VERSION "created by canmatrix"

NS_ :

BS_:

BU_: RadarFrontCenter DASy

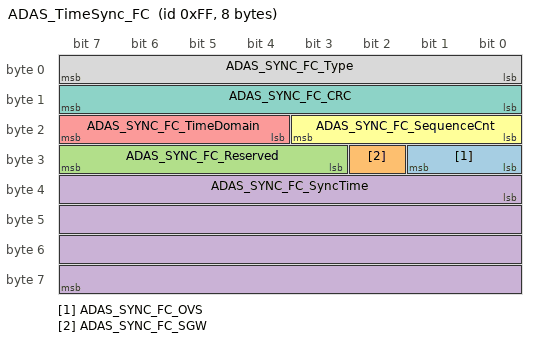
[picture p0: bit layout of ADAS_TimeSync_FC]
BO_ 255 ADAS_TimeSync_FC: 8 DASy
 SG_ ADAS_SYNC_FC_OVS : 24|2@1+ (1,0) [0|3] ""  RadarFrontCenter
 SG_ ADAS_SYNC_FC_SGW : 26|1@1+ (1,0) [0|1] ""  RadarFrontCenter
 SG_ ADAS_SYNC_FC_Reserved : 27|5@1+ (1,0) [0|31] ""  RadarFrontCenter
 SG_ ADAS_SYNC_FC_SyncTime : 32|32@1+ (1,0) [0|4294967295] ""  RadarFrontCenter
 SG_ ADAS_SYNC_FC_TimeDomain : 20|4@1+ (1,0) [0|15] ""  RadarFrontCenter
 SG_ ADAS_SYNC_FC_SequenceCnt : 16|4@1+ (1,0) [0|15] ""  RadarFrontCenter
 SG_ ADAS_SYNC_FC_CRC : 8|8@1+ (1,0) [0|0] ""  RadarFrontCenter
 SG_ ADAS_SYNC_FC_Type : 0|8@1+ (1,0) [0|255] ""  RadarFrontCenter

BO_ 384 RFC_LocationHdr00: 64 RadarFrontCenter
 SG_ RFC_Hdr00_CRC : 0|16@1+ (1,0) [0|65535] ""  DASy
 SG_ RFC_Hdr00_AliveCtr : 16|8@1+ (1,0) [0|255] ""  DASy
 SG_ RFC_Hdr00_ProtBlockCtr : 24|8@1+ (1,0) [0|255] ""  DASy
 SG_ RFC_Hdr00_ProtLocationCount : 48|8@1+ (1,0) [0|255] ""  DASy
 SG_ RFC_Hdr00_SensorState : 56|4@1+ (1,0) [0|15] ""  DASy
 SG_ RFC_Hdr00_TimeStamp : 60|26@1+ (1,0) [0|67108863] "ms"  DASy
 SG_ RFC_Hdr00_TimeStampStatus : 488|8@1+ (1,0) [0|255] ""  DASy

BO_ 400 RFC_Location_000_001: 64 RadarFrontCenter
 SG_ RFC_Loc000_CRC : 0|16@1+ (1,0) [0|65535] ""  DASy
 SG_ RFC_Loc000_AliveCtr : 16|8@1+ (1,0) [0|255] ""  DASy
 SG_ RFC_Loc000_ProtBlockCtr : 24|8@1+ (1,0) [0|255] ""  DASy
 SG_ RFC_Loc000_Dr : 32|16@1+ (0.0078125,0) [0|511.9921875] "m"  DASy
 SG_ RFC_Loc000_Vr : 48|16@1+ (0.00390625,-128) [-128|127.99609375] "m/s"  DASy
 SG_ RFC_Loc000_Theta : 64|16@1+ (0.01,-327.68) [-90|90] "deg"  DASy
 SG_ RFC_Loc000_Phi : 80|16@1+ (0.01,-327.68) [-30|30] "deg"  DASy
 SG_ RFC_Loc000_DrVnce : 96|16@1+ (1.52588E-005,0) [0|0.999984741210937] "m^2"  DASy
 SG_ RFC_Loc000_VrVnce : 112|16@1+ (1.52588E-005,0) [0|0.999984741210937] "m^2/s^2"  DASy
 SG_ RFC_Loc000_ThetaVnce : 128|16@1+ (0.00390625,0) [0|255.99609375] "deg^2"  DASy
 SG_ RFC_Loc000_PhiVnce : 144|16@1+ (0.00390625,0) [0|255.99609375] "deg^2"  DASy
 SG_ RFC_Loc000_RCS : 176|16@1+ (0.00390625,-128) [-128|127.99609375] "dBsm"  DASy
 SG_ RFC_Loc000_RSSI : 192|16@1+ (0.00195312,0) [0|127.998046875] "dimensionless"  DASy
 SG_ RFC_Loc001_Dr : 256|16@1+ (0.0078125,0) [0|511.9921875] "m"  DASy
 SG_ RFC_Loc001_Vr : 272|16@1+ (0.00390625,-128) [-128|127.99609375] "m/s"  DASy
 SG_ RFC_Loc001_Theta : 288|16@1+ (0.01,-327.68) [-90|90] "deg"  DASy
 SG_ RFC_Loc001_Phi : 304|16@1+ (0.01,-327.68) [-30|30] "deg"  DASy
 SG_ RFC_Loc001_DrVnce : 320|16@1+ (1.52588E-005,0) [0|0.999984741210937] "m^2"  DASy
 SG_ RFC_Loc001_VrVnce : 336|16@1+ (1.52588E-005,0) [0|0.999984741210937] "m^2/s^2"  DASy
 SG_ RFC_Loc001_ThetaVnce : 352|16@1+ (0.00390625,0) [0|255.99609375] "deg^2"  DASy
 SG_ RFC_Loc001_PhiVnce : 368|16@1+ (0.00390625,0) [0|255.99609375] "deg^2"  DASy
 SG_ RFC_Loc001_RCS : 400|16@1+ (0.00390625,-128) [-128|127.99609375] "dBsm"  DASy
 SG_ RFC_Loc001_RSSI : 416|16@1+ (0.00195312,0) [0|127.998046875] "dimensionless"  DASy

BO_ 401 RFC_Location_002_003: 64 RadarFrontCenter
 SG_ RFC_Loc002_CRC : 0|16@1+ (1,0) [0|65535] ""  DASy
 SG_ RFC_Loc002_AliveCtr : 16|8@1+ (1,0) [0|255] ""  DASy
 SG_ RFC_Loc002_ProtBlockCtr : 24|8@1+ (1,0) [0|255] ""  DASy
 SG_ RFC_Loc002_Dr : 32|16@1+ (0.0078125,0) [0|511.9921875] "m"  DASy
 SG_ RFC_Loc002_Vr : 48|16@1+ (0.00390625,-128) [-128|127.99609375] "m/s"  DASy
 SG_ RFC_Loc002_Theta : 64|16@1+ (0.01,-327.68) [-90|90] "deg"  DASy
 SG_ RFC_Loc002_Phi : 80|16@1+ (0.01,-327.68) [-30|30] "deg"  DASy
 SG_ RFC_Loc002_DrVnce : 96|16@1+ (1.52588E-005,0) [0|0.999984741210937] "m^2"  DASy
 SG_ RFC_Loc002_VrVnce : 112|16@1+ (1.52588E-005,0) [0|0.999984741210937] "m^2/s^2"  DASy
 SG_ RFC_Loc002_ThetaVnce : 128|16@1+ (0.00390625,0) [0|255.99609375] "deg^2"  DASy
 SG_ RFC_Loc002_PhiVnce : 144|16@1+ (0.00390625,0) [0|255.99609375] "deg^2"  DASy
 SG_ RFC_Loc002_RCS : 176|16@1+ (0.00390625,-128) [-128|127.99609375] "dBsm"  DASy
 SG_ RFC_Loc002_RSSI : 192|16@1+ (0.00195312,0) [0|127.998046875] "dimensionless"  DASy
 SG_ RFC_Loc003_Dr : 256|16@1+ (0.0078125,0) [0|511.9921875] "m"  DASy
 SG_ RFC_Loc003_Vr : 272|16@1+ (0.00390625,-128) [-128|127.99609375] "m/s"  DASy
 SG_ RFC_Loc003_Theta : 288|16@1+ (0.01,-327.68) [-90|90] "deg"  DASy
 SG_ RFC_Loc003_Phi : 304|16@1+ (0.01,-327.68) [-30|30] "deg"  DASy
 SG_ RFC_Loc003_DrVnce : 320|16@1+ (1.52588E-005,0) [0|0.999984741210937] "m^2"  DASy
 SG_ RFC_Loc003_VrVnce : 336|16@1+ (1.52588E-005,0) [0|0.999984741210937] "m^2/s^2"  DASy
 SG_ RFC_Loc003_ThetaVnce : 352|16@1+ (0.00390625,0) [0|255.99609375] "deg^2"  DASy
 SG_ RFC_Loc003_PhiVnce : 368|16@1+ (0.00390625,0) [0|255.99609375] "deg^2"  DASy
 SG_ RFC_Loc003_RCS : 400|16@1+ (0.00390625,-128) [-128|127.99609375] "dBsm"  DASy
 SG_ RFC_Loc003_RSSI : 416|16@1+ (0.00195312,0) [0|127.998046875] "dimensionless"  DASy

BO_ 402 RFC_Location_004_005: 64 RadarFrontCenter
 SG_ RFC_Loc004_CRC : 0|16@1+ (1,0) [0|65535] ""  DASy
 SG_ RFC_Loc004_AliveCtr : 16|8@1+ (1,0) [0|255] ""  DASy
 SG_ RFC_Loc004_ProtBlockCtr : 24|8@1+ (1,0) [0|255] ""  DASy
 SG_ RFC_Loc004_Dr : 32|16@1+ (0.0078125,0) [0|511.9921875] "m"  DASy
 SG_ RFC_Loc004_Vr : 48|16@1+ (0.00390625,-128) [-128|127.99609375] "m/s"  DASy
 SG_ RFC_Loc004_Theta : 64|16@1+ (0.01,-327.68) [-90|90] "deg"  DASy
 SG_ RFC_Loc004_Phi : 80|16@1+ (0.01,-327.68) [-30|30] "deg"  DASy
 SG_ RFC_Loc004_DrVnce : 96|16@1+ (1.52588E-005,0) [0|0.999984741210937] "m^2"  DASy
 SG_ RFC_Loc004_VrVnce : 112|16@1+ (1.52588E-005,0) [0|0.999984741210937] "m^2/s^2"  DASy
 SG_ RFC_Loc004_ThetaVnce : 128|16@1+ (0.00390625,0) [0|255.99609375] "deg^2"  DASy
 SG_ RFC_Loc004_PhiVnce : 144|16@1+ (0.00390625,0) [0|255.99609375] "deg^2"  DASy
 SG_ RFC_Loc004_RCS : 176|16@1+ (0.00390625,-128) [-128|127.99609375] "dBsm"  DASy
 SG_ RFC_Loc004_RSSI : 192|16@1+ (0.00195312,0) [0|127.998046875] "dimensionless"  DASy
 SG_ RFC_Loc005_Dr : 256|16@1+ (0.0078125,0) [0|511.9921875] "m"  DASy
 SG_ RFC_Loc005_Vr : 272|16@1+ (0.00390625,-128) [-128|127.99609375] "m/s"  DASy
 SG_ RFC_Loc005_Theta : 288|16@1+ (0.01,-327.68) [-90|90] "deg"  DASy
 SG_ RFC_Loc005_Phi : 304|16@1+ (0.01,-327.68) [-30|30] "deg"  DASy
 SG_ RFC_Loc005_DrVnce : 320|16@1+ (1.52588E-005,0) [0|0.999984741210937] "m^2"  DASy
 SG_ RFC_Loc005_VrVnce : 336|16@1+ (1.52588E-005,0) [0|0.999984741210937] "m^2/s^2"  DASy
 SG_ RFC_Loc005_ThetaVnce : 352|16@1+ (0.00390625,0) [0|255.99609375] "deg^2"  DASy
 SG_ RFC_Loc005_PhiVnce : 368|16@1+ (0.00390625,0) [0|255.99609375] "deg^2"  DASy
 SG_ RFC_Loc005_RCS : 400|16@1+ (0.00390625,-128) [-128|127.99609375] "dBsm"  DASy
 SG_ RFC_Loc005_RSSI : 416|16@1+ (0.00195312,0) [0|127.998046875] "dimensionless"  DASy

BO_ 403 RFC_Location_006_007: 64 RadarFrontCenter
 SG_ RFC_Loc006_CRC : 0|16@1+ (1,0) [0|65535] ""  DASy
 SG_ RFC_Loc006_AliveCtr : 16|8@1+ (1,0) [0|255] ""  DASy
 SG_ RFC_Loc006_ProtBlockCtr : 24|8@1+ (1,0) [0|255] ""  DASy
 SG_ RFC_Loc006_Dr : 32|16@1+ (0.0078125,0) [0|511.9921875] "m"  DASy
 SG_ RFC_Loc006_Vr : 48|16@1+ (0.00390625,-128) [-128|127.99609375] "m/s"  DASy
 SG_ RFC_Loc006_Theta : 64|16@1+ (0.01,-327.68) [-90|90] "deg"  DASy
 SG_ RFC_Loc006_Phi : 80|16@1+ (0.01,-327.68) [-30|30] "deg"  DASy
 SG_ RFC_Loc006_DrVnce : 96|16@1+ (1.52588E-005,0) [0|0.999984741210937] "m^2"  DASy
 SG_ RFC_Loc006_VrVnce : 112|16@1+ (1.52588E-005,0) [0|0.999984741210937] "m^2/s^2"  DASy
 SG_ RFC_Loc006_ThetaVnce : 128|16@1+ (0.00390625,0) [0|255.99609375] "deg^2"  DASy
 SG_ RFC_Loc006_PhiVnce : 144|16@1+ (0.00390625,0) [0|255.99609375] "deg^2"  DASy
 SG_ RFC_Loc006_RCS : 176|16@1+ (0.00390625,-128) [-128|127.99609375] "dBsm"  DASy
 SG_ RFC_Loc006_RSSI : 192|16@1+ (0.00195312,0) [0|127.998046875] "dimensionless"  DASy
 SG_ RFC_Loc007_Dr : 256|16@1+ (0.0078125,0) [0|511.9921875] "m"  DASy
 SG_ RFC_Loc007_Vr : 272|16@1+ (0.00390625,-128) [-128|127.99609375] "m/s"  DASy
 SG_ RFC_Loc007_Theta : 288|16@1+ (0.01,-327.68) [-90|90] "deg"  DASy
 SG_ RFC_Loc007_Phi : 304|16@1+ (0.01,-327.68) [-30|30] "deg"  DASy
 SG_ RFC_Loc007_DrVnce : 320|16@1+ (1.52588E-005,0) [0|0.999984741210937] "m^2"  DASy
 SG_ RFC_Loc007_VrVnce : 336|16@1+ (1.52588E-005,0) [0|0.999984741210937] "m^2/s^2"  DASy
 SG_ RFC_Loc007_ThetaVnce : 352|16@1+ (0.00390625,0) [0|255.99609375] "deg^2"  DASy
 SG_ RFC_Loc007_PhiVnce : 368|16@1+ (0.00390625,0) [0|255.99609375] "deg^2"  DASy
 SG_ RFC_Loc007_RCS : 400|16@1+ (0.00390625,-128) [-128|127.99609375] "dBsm"  DASy
 SG_ RFC_Loc007_RSSI : 416|16@1+ (0.00195312,0) [0|127.998046875] "dimensionless"  DASy

BO_ 404 RFC_Location_008_009: 64 RadarFrontCenter
 SG_ RFC_Loc008_CRC : 0|16@1+ (1,0) [0|65535] ""  DASy
 SG_ RFC_Loc008_AliveCtr : 16|8@1+ (1,0) [0|255] ""  DASy
 SG_ RFC_Loc008_ProtBlockCtr : 24|8@1+ (1,0) [0|255] ""  DASy
 SG_ RFC_Loc008_Dr : 32|16@1+ (0.0078125,0) [0|511.9921875] "m"  DASy
 SG_ RFC_Loc008_Vr : 48|16@1+ (0.00390625,-128) [-128|127.99609375] "m/s"  DASy
 SG_ RFC_Loc008_Theta : 64|16@1+ (0.01,-327.68) [-90|90] "deg"  DASy
 SG_ RFC_Loc008_Phi : 80|16@1+ (0.01,-327.68) [-30|30] "deg"  DASy
 SG_ RFC_Loc008_DrVnce : 96|16@1+ (1.52588E-005,0) [0|0.999984741210937] "m^2"  DASy
 SG_ RFC_Loc008_VrVnce : 112|16@1+ (1.52588E-005,0) [0|0.999984741210937] "m^2/s^2"  DASy
 SG_ RFC_Loc008_ThetaVnce : 128|16@1+ (0.00390625,0) [0|255.99609375] "deg^2"  DASy
 SG_ RFC_Loc008_PhiVnce : 144|16@1+ (0.00390625,0) [0|255.99609375] "deg^2"  DASy
 SG_ RFC_Loc008_RCS : 176|16@1+ (0.00390625,-128) [-128|127.99609375] "dBsm"  DASy
 SG_ RFC_Loc008_RSSI : 192|16@1+ (0.00195312,0) [0|127.998046875] "dimensionless"  DASy
 SG_ RFC_Loc009_Dr : 256|16@1+ (0.0078125,0) [0|511.9921875] "m"  DASy
 SG_ RFC_Loc009_Vr : 272|16@1+ (0.00390625,-128) [-128|127.99609375] "m/s"  DASy
 SG_ RFC_Loc009_Theta : 288|16@1+ (0.01,-327.68) [-90|90] "deg"  DASy
 SG_ RFC_Loc009_Phi : 304|16@1+ (0.01,-327.68) [-30|30] "deg"  DASy
 SG_ RFC_Loc009_DrVnce : 320|16@1+ (1.52588E-005,0) [0|0.999984741210937] "m^2"  DASy
 SG_ RFC_Loc009_VrVnce : 336|16@1+ (1.52588E-005,0) [0|0.999984741210937] "m^2/s^2"  DASy
 SG_ RFC_Loc009_ThetaVnce : 352|16@1+ (0.00390625,0) [0|255.99609375] "deg^2"  DASy
 SG_ RFC_Loc009_PhiVnce : 368|16@1+ (0.00390625,0) [0|255.99609375] "deg^2"  DASy
 SG_ RFC_Loc009_RCS : 400|16@1+ (0.00390625,-128) [-128|127.99609375] "dBsm"  DASy
 SG_ RFC_Loc009_RSSI : 416|16@1+ (0.00195312,0) [0|127.998046875] "dimensionless"  DASy

BO_ 405 RFC_Location_010_011: 64 RadarFrontCenter
 SG_ RFC_Loc010_CRC : 0|16@1+ (1,0) [0|65535] ""  DASy
 SG_ RFC_Loc010_AliveCtr : 16|8@1+ (1,0) [0|255] ""  DASy
 SG_ RFC_Loc010_ProtBlockCtr : 24|8@1+ (1,0) [0|255] ""  DASy
 SG_ RFC_Loc010_Dr : 32|16@1+ (0.0078125,0) [0|511.9921875] "m"  DASy
 SG_ RFC_Loc010_Vr : 48|16@1+ (0.00390625,-128) [-128|127.99609375] "m/s"  DASy
 SG_ RFC_Loc010_Theta : 64|16@1+ (0.01,-327.68) [-90|90] "deg"  DASy
 SG_ RFC_Loc010_Phi : 80|16@1+ (0.01,-327.68) [-30|30] "deg"  DASy
 SG_ RFC_Loc010_DrVnce : 96|16@1+ (1.52588E-005,0) [0|0.999984741210937] "m^2"  DASy
 SG_ RFC_Loc010_VrVnce : 112|16@1+ (1.52588E-005,0) [0|0.999984741210937] "m^2/s^2"  DASy
 SG_ RFC_Loc010_ThetaVnce : 128|16@1+ (0.00390625,0) [0|255.99609375] "deg^2"  DASy
 SG_ RFC_Loc010_PhiVnce : 144|16@1+ (0.00390625,0) [0|255.99609375] "deg^2"  DASy
 SG_ RFC_Loc010_RCS : 176|16@1+ (0.00390625,-128) [-128|127.99609375] "dBsm"  DASy
 SG_ RFC_Loc010_RSSI : 192|16@1+ (0.00195312,0) [0|127.998046875] "dimensionless"  DASy
 SG_ RFC_Loc011_Dr : 256|16@1+ (0.0078125,0) [0|511.9921875] "m"  DASy
 SG_ RFC_Loc011_Vr : 272|16@1+ (0.00390625,-128) [-128|127.99609375] "m/s"  DASy
 SG_ RFC_Loc011_Theta : 288|16@1+ (0.01,-327.68) [-90|90] "deg"  DASy
 SG_ RFC_Loc011_Phi : 304|16@1+ (0.01,-327.68) [-30|30] "deg"  DASy
 SG_ RFC_Loc011_DrVnce : 320|16@1+ (1.52588E-005,0) [0|0.999984741210937] "m^2"  DASy
 SG_ RFC_Loc011_VrVnce : 336|16@1+ (1.52588E-005,0) [0|0.999984741210937] "m^2/s^2"  DASy
 SG_ RFC_Loc011_ThetaVnce : 352|16@1+ (0.00390625,0) [0|255.99609375] "deg^2"  DASy
 SG_ RFC_Loc011_PhiVnce : 368|16@1+ (0.00390625,0) [0|255.99609375] "deg^2"  DASy
 SG_ RFC_Loc011_RCS : 400|16@1+ (0.00390625,-128) [-128|127.99609375] "dBsm"  DASy
 SG_ RFC_Loc011_RSSI : 416|16@1+ (0.00195312,0) [0|127.998046875] "dimensionless"  DASy

BO_ 406 RFC_Location_012_013: 64 RadarFrontCenter
 SG_ RFC_Loc012_CRC : 0|16@1+ (1,0) [0|65535] ""  DASy
 SG_ RFC_Loc012_AliveCtr : 16|8@1+ (1,0) [0|255] ""  DASy
 SG_ RFC_Loc012_ProtBlockCtr : 24|8@1+ (1,0) [0|255] ""  DASy
 SG_ RFC_Loc012_Dr : 32|16@1+ (0.0078125,0) [0|511.9921875] "m"  DASy
 SG_ RFC_Loc012_Vr : 48|16@1+ (0.00390625,-128) [-128|127.99609375] "m/s"  DASy
 SG_ RFC_Loc012_Theta : 64|16@1+ (0.01,-327.68) [-90|90] "deg"  DASy
 SG_ RFC_Loc012_Phi : 80|16@1+ (0.01,-327.68) [-30|30] "deg"  DASy
 SG_ RFC_Loc012_DrVnce : 96|16@1+ (1.52588E-005,0) [0|0.999984741210937] "m^2"  DASy
 SG_ RFC_Loc012_VrVnce : 112|16@1+ (1.52588E-005,0) [0|0.999984741210937] "m^2/s^2"  DASy
 SG_ RFC_Loc012_ThetaVnce : 128|16@1+ (0.00390625,0) [0|255.99609375] "deg^2"  DASy
 SG_ RFC_Loc012_PhiVnce : 144|16@1+ (0.00390625,0) [0|255.99609375] "deg^2"  DASy
 SG_ RFC_Loc012_RCS : 176|16@1+ (0.00390625,-128) [-128|127.99609375] "dBsm"  DASy
 SG_ RFC_Loc012_RSSI : 192|16@1+ (0.00195312,0) [0|127.998046875] "dimensionless"  DASy
 SG_ RFC_Loc013_Dr : 256|16@1+ (0.0078125,0) [0|511.9921875] "m"  DASy
 SG_ RFC_Loc013_Vr : 272|16@1+ (0.00390625,-128) [-128|127.99609375] "m/s"  DASy
 SG_ RFC_Loc013_Theta : 288|16@1+ (0.01,-327.68) [-90|90] "deg"  DASy
 SG_ RFC_Loc013_Phi : 304|16@1+ (0.01,-327.68) [-30|30] "deg"  DASy
 SG_ RFC_Loc013_DrVnce : 320|16@1+ (1.52588E-005,0) [0|0.999984741210937] "m^2"  DASy
 SG_ RFC_Loc013_VrVnce : 336|16@1+ (1.52588E-005,0) [0|0.999984741210937] "m^2/s^2"  DASy
 SG_ RFC_Loc013_ThetaVnce : 352|16@1+ (0.00390625,0) [0|255.99609375] "deg^2"  DASy
 SG_ RFC_Loc013_PhiVnce : 368|16@1+ (0.00390625,0) [0|255.99609375] "deg^2"  DASy
 SG_ RFC_Loc013_RCS : 400|16@1+ (0.00390625,-128) [-128|127.99609375] "dBsm"  DASy
 SG_ RFC_Loc013_RSSI : 416|16@1+ (0.00195312,0) [0|127.998046875] "dimensionless"  DASy

BO_ 407 RFC_Location_014_015: 64 RadarFrontCenter
 SG_ RFC_Loc014_CRC : 0|16@1+ (1,0) [0|65535] ""  DASy
 SG_ RFC_Loc014_AliveCtr : 16|8@1+ (1,0) [0|255] ""  DASy
 SG_ RFC_Loc014_ProtBlockCtr : 24|8@1+ (1,0) [0|255] ""  DASy
 SG_ RFC_Loc014_Dr : 32|16@1+ (0.0078125,0) [0|511.9921875] "m"  DASy
 SG_ RFC_Loc014_Vr : 48|16@1+ (0.00390625,-128) [-128|127.99609375] "m/s"  DASy
 SG_ RFC_Loc014_Theta : 64|16@1+ (0.01,-327.68) [-90|90] "deg"  DASy
 SG_ RFC_Loc014_Phi : 80|16@1+ (0.01,-327.68) [-30|30] "deg"  DASy
 SG_ RFC_Loc014_DrVnce : 96|16@1+ (1.52588E-005,0) [0|0.999984741210937] "m^2"  DASy
 SG_ RFC_Loc014_VrVnce : 112|16@1+ (1.52588E-005,0) [0|0.999984741210937] "m^2/s^2"  DASy
 SG_ RFC_Loc014_ThetaVnce : 128|16@1+ (0.00390625,0) [0|255.99609375] "deg^2"  DASy
 SG_ RFC_Loc014_PhiVnce : 144|16@1+ (0.00390625,0) [0|255.99609375] "deg^2"  DASy
 SG_ RFC_Loc014_RCS : 176|16@1+ (0.00390625,-128) [-128|127.99609375] "dBsm"  DASy
 SG_ RFC_Loc014_RSSI : 192|16@1+ (0.00195312,0) [0|127.998046875] "dimensionless"  DASy
 SG_ RFC_Loc015_Dr : 256|16@1+ (0.0078125,0) [0|511.9921875] "m"  DASy
 SG_ RFC_Loc015_Vr : 272|16@1+ (0.00390625,-128) [-128|127.99609375] "m/s"  DASy
 SG_ RFC_Loc015_Theta : 288|16@1+ (0.01,-327.68) [-90|90] "deg"  DASy
 SG_ RFC_Loc015_Phi : 304|16@1+ (0.01,-327.68) [-30|30] "deg"  DASy
 SG_ RFC_Loc015_DrVnce : 320|16@1+ (1.52588E-005,0) [0|0.999984741210937] "m^2"  DASy
 SG_ RFC_Loc015_VrVnce : 336|16@1+ (1.52588E-005,0) [0|0.999984741210937] "m^2/s^2"  DASy
 SG_ RFC_Loc015_ThetaVnce : 352|16@1+ (0.00390625,0) [0|255.99609375] "deg^2"  DASy
 SG_ RFC_Loc015_PhiVnce : 368|16@1+ (0.00390625,0) [0|255.99609375] "deg^2"  DASy
 SG_ RFC_Loc015_RCS : 400|16@1+ (0.00390625,-128) [-128|127.99609375] "dBsm"  DASy
 SG_ RFC_Loc015_RSSI : 416|16@1+ (0.00195312,0) [0|127.998046875] "dimensionless"  DASy

BO_ 408 RFC_Location_016_017: 64 RadarFrontCenter
 SG_ RFC_Loc016_CRC : 0|16@1+ (1,0) [0|65535] ""  DASy
 SG_ RFC_Loc016_AliveCtr : 16|8@1+ (1,0) [0|255] ""  DASy
 SG_ RFC_Loc016_ProtBlockCtr : 24|8@1+ (1,0) [0|255] ""  DASy
 SG_ RFC_Loc016_Dr : 32|16@1+ (0.0078125,0) [0|511.9921875] "m"  DASy
 SG_ RFC_Loc016_Vr : 48|16@1+ (0.00390625,-128) [-128|127.99609375] "m/s"  DASy
 SG_ RFC_Loc016_Theta : 64|16@1+ (0.01,-327.68) [-90|90] "deg"  DASy
 SG_ RFC_Loc016_Phi : 80|16@1+ (0.01,-327.68) [-30|30] "deg"  DASy
 SG_ RFC_Loc016_DrVnce : 96|16@1+ (1.52588E-005,0) [0|0.999984741210937] "m^2"  DASy
 SG_ RFC_Loc016_VrVnce : 112|16@1+ (1.52588E-005,0) [0|0.999984741210937] "m^2/s^2"  DASy
 SG_ RFC_Loc016_ThetaVnce : 128|16@1+ (0.00390625,0) [0|255.99609375] "deg^2"  DASy
 SG_ RFC_Loc016_PhiVnce : 144|16@1+ (0.00390625,0) [0|255.99609375] "deg^2"  DASy
 SG_ RFC_Loc016_RCS : 176|16@1+ (0.00390625,-128) [-128|127.99609375] "dBsm"  DASy
 SG_ RFC_Loc016_RSSI : 192|16@1+ (0.00195312,0) [0|127.998046875] "dimensionless"  DASy
 SG_ RFC_Loc017_Dr : 256|16@1+ (0.0078125,0) [0|511.9921875] "m"  DASy
 SG_ RFC_Loc017_Vr : 272|16@1+ (0.00390625,-128) [-128|127.99609375] "m/s"  DASy
 SG_ RFC_Loc017_Theta : 288|16@1+ (0.01,-327.68) [-90|90] "deg"  DASy
 SG_ RFC_Loc017_Phi : 304|16@1+ (0.01,-327.68) [-30|30] "deg"  DASy
 SG_ RFC_Loc017_DrVnce : 320|16@1+ (1.52588E-005,0) [0|0.999984741210937] "m^2"  DASy
 SG_ RFC_Loc017_VrVnce : 336|16@1+ (1.52588E-005,0) [0|0.999984741210937] "m^2/s^2"  DASy
 SG_ RFC_Loc017_ThetaVnce : 352|16@1+ (0.00390625,0) [0|255.99609375] "deg^2"  DASy
 SG_ RFC_Loc017_PhiVnce : 368|16@1+ (0.00390625,0) [0|255.99609375] "deg^2"  DASy
 SG_ RFC_Loc017_RCS : 400|16@1+ (0.00390625,-128) [-128|127.99609375] "dBsm"  DASy
 SG_ RFC_Loc017_RSSI : 416|16@1+ (0.00195312,0) [0|127.998046875] "dimensionless"  DASy

BO_ 409 RFC_Location_018_019: 64 RadarFrontCenter
 SG_ RFC_Loc018_CRC : 0|16@1+ (1,0) [0|65535] ""  DASy
 SG_ RFC_Loc018_AliveCtr : 16|8@1+ (1,0) [0|255] ""  DASy
 SG_ RFC_Loc018_ProtBlockCtr : 24|8@1+ (1,0) [0|255] ""  DASy
 SG_ RFC_Loc018_Dr : 32|16@1+ (0.0078125,0) [0|511.9921875] "m"  DASy
 SG_ RFC_Loc018_Vr : 48|16@1+ (0.00390625,-128) [-128|127.99609375] "m/s"  DASy
 SG_ RFC_Loc018_Theta : 64|16@1+ (0.01,-327.68) [-90|90] "deg"  DASy
 SG_ RFC_Loc018_Phi : 80|16@1+ (0.01,-327.68) [-30|30] "deg"  DASy
 SG_ RFC_Loc018_DrVnce : 96|16@1+ (1.52588E-005,0) [0|0.999984741210937] "m^2"  DASy
 SG_ RFC_Loc018_VrVnce : 112|16@1+ (1.52588E-005,0) [0|0.999984741210937] "m^2/s^2"  DASy
 SG_ RFC_Loc018_ThetaVnce : 128|16@1+ (0.00390625,0) [0|255.99609375] "deg^2"  DASy
 SG_ RFC_Loc018_PhiVnce : 144|16@1+ (0.00390625,0) [0|255.99609375] "deg^2"  DASy
 SG_ RFC_Loc018_RCS : 176|16@1+ (0.00390625,-128) [-128|127.99609375] "dBsm"  DASy
 SG_ RFC_Loc018_RSSI : 192|16@1+ (0.00195312,0) [0|127.998046875] "dimensionless"  DASy
 SG_ RFC_Loc019_Dr : 256|16@1+ (0.0078125,0) [0|511.9921875] "m"  DASy
 SG_ RFC_Loc019_Vr : 272|16@1+ (0.00390625,-128) [-128|127.99609375] "m/s"  DASy
 SG_ RFC_Loc019_Theta : 288|16@1+ (0.01,-327.68) [-90|90] "deg"  DASy
 SG_ RFC_Loc019_Phi : 304|16@1+ (0.01,-327.68) [-30|30] "deg"  DASy
 SG_ RFC_Loc019_DrVnce : 320|16@1+ (1.52588E-005,0) [0|0.999984741210937] "m^2"  DASy
 SG_ RFC_Loc019_VrVnce : 336|16@1+ (1.52588E-005,0) [0|0.999984741210937] "m^2/s^2"  DASy
 SG_ RFC_Loc019_ThetaVnce : 352|16@1+ (0.00390625,0) [0|255.99609375] "deg^2"  DASy
 SG_ RFC_Loc019_PhiVnce : 368|16@1+ (0.00390625,0) [0|255.99609375] "deg^2"  DASy
 SG_ RFC_Loc019_RCS : 400|16@1+ (0.00390625,-128) [-128|127.99609375] "dBsm"  DASy
 SG_ RFC_Loc019_RSSI : 416|16@1+ (0.00195312,0) [0|127.998046875] "dimensionless"  DASy

BO_ 410 RFC_Location_020_021: 64 RadarFrontCenter
 SG_ RFC_Loc020_CRC : 0|16@1+ (1,0) [0|65535] ""  DASy
 SG_ RFC_Loc020_AliveCtr : 16|8@1+ (1,0) [0|255] ""  DASy
 SG_ RFC_Loc020_ProtBlockCtr : 24|8@1+ (1,0) [0|255] ""  DASy
 SG_ RFC_Loc020_Dr : 32|16@1+ (0.0078125,0) [0|511.9921875] "m"  DASy
 SG_ RFC_Loc020_Vr : 48|16@1+ (0.00390625,-128) [-128|127.99609375] "m/s"  DASy
 SG_ RFC_Loc020_Theta : 64|16@1+ (0.01,-327.68) [-90|90] "deg"  DASy
 SG_ RFC_Loc020_Phi : 80|16@1+ (0.01,-327.68) [-30|30] "deg"  DASy
 SG_ RFC_Loc020_DrVnce : 96|16@1+ (1.52588E-005,0) [0|0.999984741210937] "m^2"  DASy
 SG_ RFC_Loc020_VrVnce : 112|16@1+ (1.52588E-005,0) [0|0.999984741210937] "m^2/s^2"  DASy
 SG_ RFC_Loc020_ThetaVnce : 128|16@1+ (0.00390625,0) [0|255.99609375] "deg^2"  DASy
 SG_ RFC_Loc020_PhiVnce : 144|16@1+ (0.00390625,0) [0|255.99609375] "deg^2"  DASy
 SG_ RFC_Loc020_RCS : 176|16@1+ (0.00390625,-128) [-128|127.99609375] "dBsm"  DASy
 SG_ RFC_Loc020_RSSI : 192|16@1+ (0.00195312,0) [0|127.998046875] "dimensionless"  DASy
 SG_ RFC_Loc021_Dr : 256|16@1+ (0.0078125,0) [0|511.9921875] "m"  DASy
 SG_ RFC_Loc021_Vr : 272|16@1+ (0.00390625,-128) [-128|127.99609375] "m/s"  DASy
 SG_ RFC_Loc021_Theta : 288|16@1+ (0.01,-327.68) [-90|90] "deg"  DASy
 SG_ RFC_Loc021_Phi : 304|16@1+ (0.01,-327.68) [-30|30] "deg"  DASy
 SG_ RFC_Loc021_DrVnce : 320|16@1+ (1.52588E-005,0) [0|0.999984741210937] "m^2"  DASy
 SG_ RFC_Loc021_VrVnce : 336|16@1+ (1.52588E-005,0) [0|0.999984741210937] "m^2/s^2"  DASy
 SG_ RFC_Loc021_ThetaVnce : 352|16@1+ (0.00390625,0) [0|255.99609375] "deg^2"  DASy
 SG_ RFC_Loc021_PhiVnce : 368|16@1+ (0.00390625,0) [0|255.99609375] "deg^2"  DASy
 SG_ RFC_Loc021_RCS : 400|16@1+ (0.00390625,-128) [-128|127.99609375] "dBsm"  DASy
 SG_ RFC_Loc021_RSSI : 416|16@1+ (0.00195312,0) [0|127.998046875] "dimensionless"  DASy

BO_ 411 RFC_Location_022_023: 64 RadarFrontCenter
 SG_ RFC_Loc022_CRC : 0|16@1+ (1,0) [0|65535] ""  DASy
 SG_ RFC_Loc022_AliveCtr : 16|8@1+ (1,0) [0|255] ""  DASy
 SG_ RFC_Loc022_ProtBlockCtr : 24|8@1+ (1,0) [0|255] ""  DASy
 SG_ RFC_Loc022_Dr : 32|16@1+ (0.0078125,0) [0|511.9921875] "m"  DASy
 SG_ RFC_Loc022_Vr : 48|16@1+ (0.00390625,-128) [-128|127.99609375] "m/s"  DASy
 SG_ RFC_Loc022_Theta : 64|16@1+ (0.01,-327.68) [-90|90] "deg"  DASy
 SG_ RFC_Loc022_Phi : 80|16@1+ (0.01,-327.68) [-30|30] "deg"  DASy
 SG_ RFC_Loc022_DrVnce : 96|16@1+ (1.52588E-005,0) [0|0.999984741210937] "m^2"  DASy
 SG_ RFC_Loc022_VrVnce : 112|16@1+ (1.52588E-005,0) [0|0.999984741210937] "m^2/s^2"  DASy
 SG_ RFC_Loc022_ThetaVnce : 128|16@1+ (0.00390625,0) [0|255.99609375] "deg^2"  DASy
 SG_ RFC_Loc022_PhiVnce : 144|16@1+ (0.00390625,0) [0|255.99609375] "deg^2"  DASy
 SG_ RFC_Loc022_RCS : 176|16@1+ (0.00390625,-128) [-128|127.99609375] "dBsm"  DASy
 SG_ RFC_Loc022_RSSI : 192|16@1+ (0.00195312,0) [0|127.998046875] "dimensionless"  DASy
 SG_ RFC_Loc023_Dr : 256|16@1+ (0.0078125,0) [0|511.9921875] "m"  DASy
 SG_ RFC_Loc023_Vr : 272|16@1+ (0.00390625,-128) [-128|127.99609375] "m/s"  DASy
 SG_ RFC_Loc023_Theta : 288|16@1+ (0.01,-327.68) [-90|90] "deg"  DASy
 SG_ RFC_Loc023_Phi : 304|16@1+ (0.01,-327.68) [-30|30] "deg"  DASy
 SG_ RFC_Loc023_DrVnce : 320|16@1+ (1.52588E-005,0) [0|0.999984741210937] "m^2"  DASy
 SG_ RFC_Loc023_VrVnce : 336|16@1+ (1.52588E-005,0) [0|0.999984741210937] "m^2/s^2"  DASy
 SG_ RFC_Loc023_ThetaVnce : 352|16@1+ (0.00390625,0) [0|255.99609375] "deg^2"  DASy
 SG_ RFC_Loc023_PhiVnce : 368|16@1+ (0.00390625,0) [0|255.99609375] "deg^2"  DASy
 SG_ RFC_Loc023_RCS : 400|16@1+ (0.00390625,-128) [-128|127.99609375] "dBsm"  DASy
 SG_ RFC_Loc023_RSSI : 416|16@1+ (0.00195312,0) [0|127.998046875] "dimensionless"  DASy

BO_ 412 RFC_Location_024_025: 64 RadarFrontCenter
 SG_ RFC_Loc024_CRC : 0|16@1+ (1,0) [0|65535] ""  DASy
 SG_ RFC_Loc024_AliveCtr : 16|8@1+ (1,0) [0|255] ""  DASy
 SG_ RFC_Loc024_ProtBlockCtr : 24|8@1+ (1,0) [0|255] ""  DASy
 SG_ RFC_Loc024_Dr : 32|16@1+ (0.0078125,0) [0|511.9921875] "m"  DASy
 SG_ RFC_Loc024_Vr : 48|16@1+ (0.00390625,-128) [-128|127.99609375] "m/s"  DASy
 SG_ RFC_Loc024_Theta : 64|16@1+ (0.01,-327.68) [-90|90] "deg"  DASy
 SG_ RFC_Loc024_Phi : 80|16@1+ (0.01,-327.68) [-30|30] "deg"  DASy
 SG_ RFC_Loc024_DrVnce : 96|16@1+ (1.52588E-005,0) [0|0.999984741210937] "m^2"  DASy
 SG_ RFC_Loc024_VrVnce : 112|16@1+ (1.52588E-005,0) [0|0.999984741210937] "m^2/s^2"  DASy
 SG_ RFC_Loc024_ThetaVnce : 128|16@1+ (0.00390625,0) [0|255.99609375] "deg^2"  DASy
 SG_ RFC_Loc024_PhiVnce : 144|16@1+ (0.00390625,0) [0|255.99609375] "deg^2"  DASy
 SG_ RFC_Loc024_RCS : 176|16@1+ (0.00390625,-128) [-128|127.99609375] "dBsm"  DASy
 SG_ RFC_Loc024_RSSI : 192|16@1+ (0.00195312,0) [0|127.998046875] "dimensionless"  DASy
 SG_ RFC_Loc025_Dr : 256|16@1+ (0.0078125,0) [0|511.9921875] "m"  DASy
 SG_ RFC_Loc025_Vr : 272|16@1+ (0.00390625,-128) [-128|127.99609375] "m/s"  DASy
 SG_ RFC_Loc025_Theta : 288|16@1+ (0.01,-327.68) [-90|90] "deg"  DASy
 SG_ RFC_Loc025_Phi : 304|16@1+ (0.01,-327.68) [-30|30] "deg"  DASy
 SG_ RFC_Loc025_DrVnce : 320|16@1+ (1.52588E-005,0) [0|0.999984741210937] "m^2"  DASy
 SG_ RFC_Loc025_VrVnce : 336|16@1+ (1.52588E-005,0) [0|0.999984741210937] "m^2/s^2"  DASy
 SG_ RFC_Loc025_ThetaVnce : 352|16@1+ (0.00390625,0) [0|255.99609375] "deg^2"  DASy
 SG_ RFC_Loc025_PhiVnce : 368|16@1+ (0.00390625,0) [0|255.99609375] "deg^2"  DASy
 SG_ RFC_Loc025_RCS : 400|16@1+ (0.00390625,-128) [-128|127.99609375] "dBsm"  DASy
 SG_ RFC_Loc025_RSSI : 416|16@1+ (0.00195312,0) [0|127.998046875] "dimensionless"  DASy

BO_ 413 RFC_Location_026_027: 64 RadarFrontCenter
 SG_ RFC_Loc026_CRC : 0|16@1+ (1,0) [0|65535] ""  DASy
 SG_ RFC_Loc026_AliveCtr : 16|8@1+ (1,0) [0|255] ""  DASy
 SG_ RFC_Loc026_ProtBlockCtr : 24|8@1+ (1,0) [0|255] ""  DASy
 SG_ RFC_Loc026_Dr : 32|16@1+ (0.0078125,0) [0|511.9921875] "m"  DASy
 SG_ RFC_Loc026_Vr : 48|16@1+ (0.00390625,-128) [-128|127.99609375] "m/s"  DASy
 SG_ RFC_Loc026_Theta : 64|16@1+ (0.01,-327.68) [-90|90] "deg"  DASy
 SG_ RFC_Loc026_Phi : 80|16@1+ (0.01,-327.68) [-30|30] "deg"  DASy
 SG_ RFC_Loc026_DrVnce : 96|16@1+ (1.52588E-005,0) [0|0.999984741210937] "m^2"  DASy
 SG_ RFC_Loc026_VrVnce : 112|16@1+ (1.52588E-005,0) [0|0.999984741210937] "m^2/s^2"  DASy
 SG_ RFC_Loc026_ThetaVnce : 128|16@1+ (0.00390625,0) [0|255.99609375] "deg^2"  DASy
 SG_ RFC_Loc026_PhiVnce : 144|16@1+ (0.00390625,0) [0|255.99609375] "deg^2"  DASy
 SG_ RFC_Loc026_RCS : 176|16@1+ (0.00390625,-128) [-128|127.99609375] "dBsm"  DASy
 SG_ RFC_Loc026_RSSI : 192|16@1+ (0.00195312,0) [0|127.998046875] "dimensionless"  DASy
 SG_ RFC_Loc027_Dr : 256|16@1+ (0.0078125,0) [0|511.9921875] "m"  DASy
 SG_ RFC_Loc027_Vr : 272|16@1+ (0.00390625,-128) [-128|127.99609375] "m/s"  DASy
 SG_ RFC_Loc027_Theta : 288|16@1+ (0.01,-327.68) [-90|90] "deg"  DASy
 SG_ RFC_Loc027_Phi : 304|16@1+ (0.01,-327.68) [-30|30] "deg"  DASy
 SG_ RFC_Loc027_DrVnce : 320|16@1+ (1.52588E-005,0) [0|0.999984741210937] "m^2"  DASy
 SG_ RFC_Loc027_VrVnce : 336|16@1+ (1.52588E-005,0) [0|0.999984741210937] "m^2/s^2"  DASy
 SG_ RFC_Loc027_ThetaVnce : 352|16@1+ (0.00390625,0) [0|255.99609375] "deg^2"  DASy
 SG_ RFC_Loc027_PhiVnce : 368|16@1+ (0.00390625,0) [0|255.99609375] "deg^2"  DASy
 SG_ RFC_Loc027_RCS : 400|16@1+ (0.00390625,-128) [-128|127.99609375] "dBsm"  DASy
 SG_ RFC_Loc027_RSSI : 416|16@1+ (0.00195312,0) [0|127.998046875] "dimensionless"  DASy

BO_ 414 RFC_Location_028_029: 64 RadarFrontCenter
 SG_ RFC_Loc028_CRC : 0|16@1+ (1,0) [0|65535] ""  DASy
 SG_ RFC_Loc028_AliveCtr : 16|8@1+ (1,0) [0|255] ""  DASy
 SG_ RFC_Loc028_ProtBlockCtr : 24|8@1+ (1,0) [0|255] ""  DASy
 SG_ RFC_Loc028_Dr : 32|16@1+ (0.0078125,0) [0|511.9921875] "m"  DASy
 SG_ RFC_Loc028_Vr : 48|16@1+ (0.00390625,-128) [-128|127.99609375] "m/s"  DASy
 SG_ RFC_Loc028_Theta : 64|16@1+ (0.01,-327.68) [-90|90] "deg"  DASy
 SG_ RFC_Loc028_Phi : 80|16@1+ (0.01,-327.68) [-30|30] "deg"  DASy
 SG_ RFC_Loc028_DrVnce : 96|16@1+ (1.52588E-005,0) [0|0.999984741210937] "m^2"  DASy
 SG_ RFC_Loc028_VrVnce : 112|16@1+ (1.52588E-005,0) [0|0.999984741210937] "m^2/s^2"  DASy
 SG_ RFC_Loc028_ThetaVnce : 128|16@1+ (0.00390625,0) [0|255.99609375] "deg^2"  DASy
 SG_ RFC_Loc028_PhiVnce : 144|16@1+ (0.00390625,0) [0|255.99609375] "deg^2"  DASy
 SG_ RFC_Loc028_RCS : 176|16@1+ (0.00390625,-128) [-128|127.99609375] "dBsm"  DASy
 SG_ RFC_Loc028_RSSI : 192|16@1+ (0.00195312,0) [0|127.998046875] "dimensionless"  DASy
 SG_ RFC_Loc029_Dr : 256|16@1+ (0.0078125,0) [0|511.9921875] "m"  DASy
 SG_ RFC_Loc029_Vr : 272|16@1+ (0.00390625,-128) [-128|127.99609375] "m/s"  DASy
 SG_ RFC_Loc029_Theta : 288|16@1+ (0.01,-327.68) [-90|90] "deg"  DASy
 SG_ RFC_Loc029_Phi : 304|16@1+ (0.01,-327.68) [-30|30] "deg"  DASy
 SG_ RFC_Loc029_DrVnce : 320|16@1+ (1.52588E-005,0) [0|0.999984741210937] "m^2"  DASy
 SG_ RFC_Loc029_VrVnce : 336|16@1+ (1.52588E-005,0) [0|0.999984741210937] "m^2/s^2"  DASy
 SG_ RFC_Loc029_ThetaVnce : 352|16@1+ (0.00390625,0) [0|255.99609375] "deg^2"  DASy
 SG_ RFC_Loc029_PhiVnce : 368|16@1+ (0.00390625,0) [0|255.99609375] "deg^2"  DASy
 SG_ RFC_Loc029_RCS : 400|16@1+ (0.00390625,-128) [-128|127.99609375] "dBsm"  DASy
 SG_ RFC_Loc029_RSSI : 416|16@1+ (0.00195312,0) [0|127.998046875] "dimensionless"  DASy

BO_ 415 RFC_Location_030_031: 64 RadarFrontCenter
 SG_ RFC_Loc030_CRC : 0|16@1+ (1,0) [0|65535] ""  DASy
 SG_ RFC_Loc030_AliveCtr : 16|8@1+ (1,0) [0|255] ""  DASy
 SG_ RFC_Loc030_ProtBlockCtr : 24|8@1+ (1,0) [0|255] ""  DASy
 SG_ RFC_Loc030_Dr : 32|16@1+ (0.0078125,0) [0|511.9921875] "m"  DASy
 SG_ RFC_Loc030_Vr : 48|16@1+ (0.00390625,-128) [-128|127.99609375] "m/s"  DASy
 SG_ RFC_Loc030_Theta : 64|16@1+ (0.01,-327.68) [-90|90] "deg"  DASy
 SG_ RFC_Loc030_Phi : 80|16@1+ (0.01,-327.68) [-30|30] "deg"  DASy
 SG_ RFC_Loc030_DrVnce : 96|16@1+ (1.52588E-005,0) [0|0.999984741210937] "m^2"  DASy
 SG_ RFC_Loc030_VrVnce : 112|16@1+ (1.52588E-005,0) [0|0.999984741210937] "m^2/s^2"  DASy
 SG_ RFC_Loc030_ThetaVnce : 128|16@1+ (0.00390625,0) [0|255.99609375] "deg^2"  DASy
 SG_ RFC_Loc030_PhiVnce : 144|16@1+ (0.00390625,0) [0|255.99609375] "deg^2"  DASy
 SG_ RFC_Loc030_RCS : 176|16@1+ (0.00390625,-128) [-128|127.99609375] "dBsm"  DASy
 SG_ RFC_Loc030_RSSI : 192|16@1+ (0.00195312,0) [0|127.998046875] "dimensionless"  DASy
 SG_ RFC_Loc031_Dr : 256|16@1+ (0.0078125,0) [0|511.9921875] "m"  DASy
 SG_ RFC_Loc031_Vr : 272|16@1+ (0.00390625,-128) [-128|127.99609375] "m/s"  DASy
 SG_ RFC_Loc031_Theta : 288|16@1+ (0.01,-327.68) [-90|90] "deg"  DASy
 SG_ RFC_Loc031_Phi : 304|16@1+ (0.01,-327.68) [-30|30] "deg"  DASy
 SG_ RFC_Loc031_DrVnce : 320|16@1+ (1.52588E-005,0) [0|0.999984741210937] "m^2"  DASy
 SG_ RFC_Loc031_VrVnce : 336|16@1+ (1.52588E-005,0) [0|0.999984741210937] "m^2/s^2"  DASy
 SG_ RFC_Loc031_ThetaVnce : 352|16@1+ (0.00390625,0) [0|255.99609375] "deg^2"  DASy
 SG_ RFC_Loc031_PhiVnce : 368|16@1+ (0.00390625,0) [0|255.99609375] "deg^2"  DASy
 SG_ RFC_Loc031_RCS : 400|16@1+ (0.00390625,-128) [-128|127.99609375] "dBsm"  DASy
 SG_ RFC_Loc031_RSSI : 416|16@1+ (0.00195312,0) [0|127.998046875] "dimensionless"  DASy

BO_ 416 RFC_Location_032_033: 64 RadarFrontCenter
 SG_ RFC_Loc032_CRC : 0|16@1+ (1,0) [0|65535] ""  DASy
 SG_ RFC_Loc032_AliveCtr : 16|8@1+ (1,0) [0|255] ""  DASy
 SG_ RFC_Loc032_ProtBlockCtr : 24|8@1+ (1,0) [0|255] ""  DASy
 SG_ RFC_Loc032_Dr : 32|16@1+ (0.0078125,0) [0|511.9921875] "m"  DASy
 SG_ RFC_Loc032_Vr : 48|16@1+ (0.00390625,-128) [-128|127.99609375] "m/s"  DASy
 SG_ RFC_Loc032_Theta : 64|16@1+ (0.01,-327.68) [-90|90] "deg"  DASy
 SG_ RFC_Loc032_Phi : 80|16@1+ (0.01,-327.68) [-30|30] "deg"  DASy
 SG_ RFC_Loc032_DrVnce : 96|16@1+ (1.52588E-005,0) [0|0.999984741210937] "m^2"  DASy
 SG_ RFC_Loc032_VrVnce : 112|16@1+ (1.52588E-005,0) [0|0.999984741210937] "m^2/s^2"  DASy
 SG_ RFC_Loc032_ThetaVnce : 128|16@1+ (0.00390625,0) [0|255.99609375] "deg^2"  DASy
 SG_ RFC_Loc032_PhiVnce : 144|16@1+ (0.00390625,0) [0|255.99609375] "deg^2"  DASy
 SG_ RFC_Loc032_RCS : 176|16@1+ (0.00390625,-128) [-128|127.99609375] "dBsm"  DASy
 SG_ RFC_Loc032_RSSI : 192|16@1+ (0.00195312,0) [0|127.998046875] "dimensionless"  DASy
 SG_ RFC_Loc033_Dr : 256|16@1+ (0.0078125,0) [0|511.9921875] "m"  DASy
 SG_ RFC_Loc033_Vr : 272|16@1+ (0.00390625,-128) [-128|127.99609375] "m/s"  DASy
 SG_ RFC_Loc033_Theta : 288|16@1+ (0.01,-327.68) [-90|90] "deg"  DASy
 SG_ RFC_Loc033_Phi : 304|16@1+ (0.01,-327.68) [-30|30] "deg"  DASy
 SG_ RFC_Loc033_DrVnce : 320|16@1+ (1.52588E-005,0) [0|0.999984741210937] "m^2"  DASy
 SG_ RFC_Loc033_VrVnce : 336|16@1+ (1.52588E-005,0) [0|0.999984741210937] "m^2/s^2"  DASy
 SG_ RFC_Loc033_ThetaVnce : 352|16@1+ (0.00390625,0) [0|255.99609375] "deg^2"  DASy
 SG_ RFC_Loc033_PhiVnce : 368|16@1+ (0.00390625,0) [0|255.99609375] "deg^2"  DASy
 SG_ RFC_Loc033_RCS : 400|16@1+ (0.00390625,-128) [-128|127.99609375] "dBsm"  DASy
 SG_ RFC_Loc033_RSSI : 416|16@1+ (0.00195312,0) [0|127.998046875] "dimensionless"  DASy

BO_ 417 RFC_Location_034_035: 64 RadarFrontCenter
 SG_ RFC_Loc034_CRC : 0|16@1+ (1,0) [0|65535] ""  DASy
 SG_ RFC_Loc034_AliveCtr : 16|8@1+ (1,0) [0|255] ""  DASy
 SG_ RFC_Loc034_ProtBlockCtr : 24|8@1+ (1,0) [0|255] ""  DASy
 SG_ RFC_Loc034_Dr : 32|16@1+ (0.0078125,0) [0|511.9921875] "m"  DASy
 SG_ RFC_Loc034_Vr : 48|16@1+ (0.00390625,-128) [-128|127.99609375] "m/s"  DASy
 SG_ RFC_Loc034_Theta : 64|16@1+ (0.01,-327.68) [-90|90] "deg"  DASy
 SG_ RFC_Loc034_Phi : 80|16@1+ (0.01,-327.68) [-30|30] "deg"  DASy
 SG_ RFC_Loc034_DrVnce : 96|16@1+ (1.52588E-005,0) [0|0.999984741210937] "m^2"  DASy
 SG_ RFC_Loc034_VrVnce : 112|16@1+ (1.52588E-005,0) [0|0.999984741210937] "m^2/s^2"  DASy
 SG_ RFC_Loc034_ThetaVnce : 128|16@1+ (0.00390625,0) [0|255.99609375] "deg^2"  DASy
 SG_ RFC_Loc034_PhiVnce : 144|16@1+ (0.00390625,0) [0|255.99609375] "deg^2"  DASy
 SG_ RFC_Loc034_RCS : 176|16@1+ (0.00390625,-128) [-128|127.99609375] "dBsm"  DASy
 SG_ RFC_Loc034_RSSI : 192|16@1+ (0.00195312,0) [0|127.998046875] "dimensionless"  DASy
 SG_ RFC_Loc035_Dr : 256|16@1+ (0.0078125,0) [0|511.9921875] "m"  DASy
 SG_ RFC_Loc035_Vr : 272|16@1+ (0.00390625,-128) [-128|127.99609375] "m/s"  DASy
 SG_ RFC_Loc035_Theta : 288|16@1+ (0.01,-327.68) [-90|90] "deg"  DASy
 SG_ RFC_Loc035_Phi : 304|16@1+ (0.01,-327.68) [-30|30] "deg"  DASy
 SG_ RFC_Loc035_DrVnce : 320|16@1+ (1.52588E-005,0) [0|0.999984741210937] "m^2"  DASy
 SG_ RFC_Loc035_VrVnce : 336|16@1+ (1.52588E-005,0) [0|0.999984741210937] "m^2/s^2"  DASy
 SG_ RFC_Loc035_ThetaVnce : 352|16@1+ (0.00390625,0) [0|255.99609375] "deg^2"  DASy
 SG_ RFC_Loc035_PhiVnce : 368|16@1+ (0.00390625,0) [0|255.99609375] "deg^2"  DASy
 SG_ RFC_Loc035_RCS : 400|16@1+ (0.00390625,-128) [-128|127.99609375] "dBsm"  DASy
 SG_ RFC_Loc035_RSSI : 416|16@1+ (0.00195312,0) [0|127.998046875] "dimensionless"  DASy

BO_ 418 RFC_Location_036_037: 64 RadarFrontCenter
 SG_ RFC_Loc036_CRC : 0|16@1+ (1,0) [0|65535] ""  DASy
 SG_ RFC_Loc036_AliveCtr : 16|8@1+ (1,0) [0|255] ""  DASy
 SG_ RFC_Loc036_ProtBlockCtr : 24|8@1+ (1,0) [0|255] ""  DASy
 SG_ RFC_Loc036_Dr : 32|16@1+ (0.0078125,0) [0|511.9921875] "m"  DASy
 SG_ RFC_Loc036_Vr : 48|16@1+ (0.00390625,-128) [-128|127.99609375] "m/s"  DASy
 SG_ RFC_Loc036_Theta : 64|16@1+ (0.01,-327.68) [-90|90] "deg"  DASy
 SG_ RFC_Loc036_Phi : 80|16@1+ (0.01,-327.68) [-30|30] "deg"  DASy
 SG_ RFC_Loc036_DrVnce : 96|16@1+ (1.52588E-005,0) [0|0.999984741210937] "m^2"  DASy
 SG_ RFC_Loc036_VrVnce : 112|16@1+ (1.52588E-005,0) [0|0.999984741210937] "m^2/s^2"  DASy
 SG_ RFC_Loc036_ThetaVnce : 128|16@1+ (0.00390625,0) [0|255.99609375] "deg^2"  DASy
 SG_ RFC_Loc036_PhiVnce : 144|16@1+ (0.00390625,0) [0|255.99609375] "deg^2"  DASy
 SG_ RFC_Loc036_RCS : 176|16@1+ (0.00390625,-128) [-128|127.99609375] "dBsm"  DASy
 SG_ RFC_Loc036_RSSI : 192|16@1+ (0.00195312,0) [0|127.998046875] "dimensionless"  DASy
 SG_ RFC_Loc037_Dr : 256|16@1+ (0.0078125,0) [0|511.9921875] "m"  DASy
 SG_ RFC_Loc037_Vr : 272|16@1+ (0.00390625,-128) [-128|127.99609375] "m/s"  DASy
 SG_ RFC_Loc037_Theta : 288|16@1+ (0.01,-327.68) [-90|90] "deg"  DASy
 SG_ RFC_Loc037_Phi : 304|16@1+ (0.01,-327.68) [-30|30] "deg"  DASy
 SG_ RFC_Loc037_DrVnce : 320|16@1+ (1.52588E-005,0) [0|0.999984741210937] "m^2"  DASy
 SG_ RFC_Loc037_VrVnce : 336|16@1+ (1.52588E-005,0) [0|0.999984741210937] "m^2/s^2"  DASy
 SG_ RFC_Loc037_ThetaVnce : 352|16@1+ (0.00390625,0) [0|255.99609375] "deg^2"  DASy
 SG_ RFC_Loc037_PhiVnce : 368|16@1+ (0.00390625,0) [0|255.99609375] "deg^2"  DASy
 SG_ RFC_Loc037_RCS : 400|16@1+ (0.00390625,-128) [-128|127.99609375] "dBsm"  DASy
 SG_ RFC_Loc037_RSSI : 416|16@1+ (0.00195312,0) [0|127.998046875] "dimensionless"  DASy

BO_ 419 RFC_Location_038_039: 64 RadarFrontCenter
 SG_ RFC_Loc038_CRC : 0|16@1+ (1,0) [0|65535] ""  DASy
 SG_ RFC_Loc038_AliveCtr : 16|8@1+ (1,0) [0|255] ""  DASy
 SG_ RFC_Loc038_ProtBlockCtr : 24|8@1+ (1,0) [0|255] ""  DASy
 SG_ RFC_Loc038_Dr : 32|16@1+ (0.0078125,0) [0|511.9921875] "m"  DASy
 SG_ RFC_Loc038_Vr : 48|16@1+ (0.00390625,-128) [-128|127.99609375] "m/s"  DASy
 SG_ RFC_Loc038_Theta : 64|16@1+ (0.01,-327.68) [-90|90] "deg"  DASy
 SG_ RFC_Loc038_Phi : 80|16@1+ (0.01,-327.68) [-30|30] "deg"  DASy
 SG_ RFC_Loc038_DrVnce : 96|16@1+ (1.52588E-005,0) [0|0.999984741210937] "m^2"  DASy
 SG_ RFC_Loc038_VrVnce : 112|16@1+ (1.52588E-005,0) [0|0.999984741210937] "m^2/s^2"  DASy
 SG_ RFC_Loc038_ThetaVnce : 128|16@1+ (0.00390625,0) [0|255.99609375] "deg^2"  DASy
 SG_ RFC_Loc038_PhiVnce : 144|16@1+ (0.00390625,0) [0|255.99609375] "deg^2"  DASy
 SG_ RFC_Loc038_RCS : 176|16@1+ (0.00390625,-128) [-128|127.99609375] "dBsm"  DASy
 SG_ RFC_Loc038_RSSI : 192|16@1+ (0.00195312,0) [0|127.998046875] "dimensionless"  DASy
 SG_ RFC_Loc039_Dr : 256|16@1+ (0.0078125,0) [0|511.9921875] "m"  DASy
 SG_ RFC_Loc039_Vr : 272|16@1+ (0.00390625,-128) [-128|127.99609375] "m/s"  DASy
 SG_ RFC_Loc039_Theta : 288|16@1+ (0.01,-327.68) [-90|90] "deg"  DASy
 SG_ RFC_Loc039_Phi : 304|16@1+ (0.01,-327.68) [-30|30] "deg"  DASy
 SG_ RFC_Loc039_DrVnce : 320|16@1+ (1.52588E-005,0) [0|0.999984741210937] "m^2"  DASy
 SG_ RFC_Loc039_VrVnce : 336|16@1+ (1.52588E-005,0) [0|0.999984741210937] "m^2/s^2"  DASy
 SG_ RFC_Loc039_ThetaVnce : 352|16@1+ (0.00390625,0) [0|255.99609375] "deg^2"  DASy
 SG_ RFC_Loc039_PhiVnce : 368|16@1+ (0.00390625,0) [0|255.99609375] "deg^2"  DASy
 SG_ RFC_Loc039_RCS : 400|16@1+ (0.00390625,-128) [-128|127.99609375] "dBsm"  DASy
 SG_ RFC_Loc039_RSSI : 416|16@1+ (0.00195312,0) [0|127.998046875] "dimensionless"  DASy

BO_ 420 RFC_Location_040_041: 64 RadarFrontCenter
 SG_ RFC_Loc040_CRC : 0|16@1+ (1,0) [0|65535] ""  DASy
 SG_ RFC_Loc040_AliveCtr : 16|8@1+ (1,0) [0|255] ""  DASy
 SG_ RFC_Loc040_ProtBlockCtr : 24|8@1+ (1,0) [0|255] ""  DASy
 SG_ RFC_Loc040_Dr : 32|16@1+ (0.0078125,0) [0|511.9921875] "m"  DASy
 SG_ RFC_Loc040_Vr : 48|16@1+ (0.00390625,-128) [-128|127.99609375] "m/s"  DASy
 SG_ RFC_Loc040_Theta : 64|16@1+ (0.01,-327.68) [-90|90] "deg"  DASy
 SG_ RFC_Loc040_Phi : 80|16@1+ (0.01,-327.68) [-30|30] "deg"  DASy
 SG_ RFC_Loc040_DrVnce : 96|16@1+ (1.52588E-005,0) [0|0.999984741210937] "m^2"  DASy
 SG_ RFC_Loc040_VrVnce : 112|16@1+ (1.52588E-005,0) [0|0.999984741210937] "m^2/s^2"  DASy
 SG_ RFC_Loc040_ThetaVnce : 128|16@1+ (0.00390625,0) [0|255.99609375] "deg^2"  DASy
 SG_ RFC_Loc040_PhiVnce : 144|16@1+ (0.00390625,0) [0|255.99609375] "deg^2"  DASy
 SG_ RFC_Loc040_RCS : 176|16@1+ (0.00390625,-128) [-128|127.99609375] "dBsm"  DASy
 SG_ RFC_Loc040_RSSI : 192|16@1+ (0.00195312,0) [0|127.998046875] "dimensionless"  DASy
 SG_ RFC_Loc041_Dr : 256|16@1+ (0.0078125,0) [0|511.9921875] "m"  DASy
 SG_ RFC_Loc041_Vr : 272|16@1+ (0.00390625,-128) [-128|127.99609375] "m/s"  DASy
 SG_ RFC_Loc041_Theta : 288|16@1+ (0.01,-327.68) [-90|90] "deg"  DASy
 SG_ RFC_Loc041_Phi : 304|16@1+ (0.01,-327.68) [-30|30] "deg"  DASy
 SG_ RFC_Loc041_DrVnce : 320|16@1+ (1.52588E-005,0) [0|0.999984741210937] "m^2"  DASy
 SG_ RFC_Loc041_VrVnce : 336|16@1+ (1.52588E-005,0) [0|0.999984741210937] "m^2/s^2"  DASy
 SG_ RFC_Loc041_ThetaVnce : 352|16@1+ (0.00390625,0) [0|255.99609375] "deg^2"  DASy
 SG_ RFC_Loc041_PhiVnce : 368|16@1+ (0.00390625,0) [0|255.99609375] "deg^2"  DASy
 SG_ RFC_Loc041_RCS : 400|16@1+ (0.00390625,-128) [-128|127.99609375] "dBsm"  DASy
 SG_ RFC_Loc041_RSSI : 416|16@1+ (0.00195312,0) [0|127.998046875] "dimensionless"  DASy

BO_ 421 RFC_Location_042_043: 64 RadarFrontCenter
 SG_ RFC_Loc042_CRC : 0|16@1+ (1,0) [0|65535] ""  DASy
 SG_ RFC_Loc042_AliveCtr : 16|8@1+ (1,0) [0|255] ""  DASy
 SG_ RFC_Loc042_ProtBlockCtr : 24|8@1+ (1,0) [0|255] ""  DASy
 SG_ RFC_Loc042_Dr : 32|16@1+ (0.0078125,0) [0|511.9921875] "m"  DASy
 SG_ RFC_Loc042_Vr : 48|16@1+ (0.00390625,-128) [-128|127.99609375] "m/s"  DASy
 SG_ RFC_Loc042_Theta : 64|16@1+ (0.01,-327.68) [-90|90] "deg"  DASy
 SG_ RFC_Loc042_Phi : 80|16@1+ (0.01,-327.68) [-30|30] "deg"  DASy
 SG_ RFC_Loc042_DrVnce : 96|16@1+ (1.52588E-005,0) [0|0.999984741210937] "m^2"  DASy
 SG_ RFC_Loc042_VrVnce : 112|16@1+ (1.52588E-005,0) [0|0.999984741210937] "m^2/s^2"  DASy
 SG_ RFC_Loc042_ThetaVnce : 128|16@1+ (0.00390625,0) [0|255.99609375] "deg^2"  DASy
 SG_ RFC_Loc042_PhiVnce : 144|16@1+ (0.00390625,0) [0|255.99609375] "deg^2"  DASy
 SG_ RFC_Loc042_RCS : 176|16@1+ (0.00390625,-128) [-128|127.99609375] "dBsm"  DASy
 SG_ RFC_Loc042_RSSI : 192|16@1+ (0.00195312,0) [0|127.998046875] "dimensionless"  DASy
 SG_ RFC_Loc043_Dr : 256|16@1+ (0.0078125,0) [0|511.9921875] "m"  DASy
 SG_ RFC_Loc043_Vr : 272|16@1+ (0.00390625,-128) [-128|127.99609375] "m/s"  DASy
 SG_ RFC_Loc043_Theta : 288|16@1+ (0.01,-327.68) [-90|90] "deg"  DASy
 SG_ RFC_Loc043_Phi : 304|16@1+ (0.01,-327.68) [-30|30] "deg"  DASy
 SG_ RFC_Loc043_DrVnce : 320|16@1+ (1.52588E-005,0) [0|0.999984741210937] "m^2"  DASy
 SG_ RFC_Loc043_VrVnce : 336|16@1+ (1.52588E-005,0) [0|0.999984741210937] "m^2/s^2"  DASy
 SG_ RFC_Loc043_ThetaVnce : 352|16@1+ (0.00390625,0) [0|255.99609375] "deg^2"  DASy
 SG_ RFC_Loc043_PhiVnce : 368|16@1+ (0.00390625,0) [0|255.99609375] "deg^2"  DASy
 SG_ RFC_Loc043_RCS : 400|16@1+ (0.00390625,-128) [-128|127.99609375] "dBsm"  DASy
 SG_ RFC_Loc043_RSSI : 416|16@1+ (0.00195312,0) [0|127.998046875] "dimensionless"  DASy

BO_ 422 RFC_Location_044_045: 64 RadarFrontCenter
 SG_ RFC_Loc044_CRC : 0|16@1+ (1,0) [0|65535] ""  DASy
 SG_ RFC_Loc044_AliveCtr : 16|8@1+ (1,0) [0|255] ""  DASy
 SG_ RFC_Loc044_ProtBlockCtr : 24|8@1+ (1,0) [0|255] ""  DASy
 SG_ RFC_Loc044_Dr : 32|16@1+ (0.0078125,0) [0|511.9921875] "m"  DASy
 SG_ RFC_Loc044_Vr : 48|16@1+ (0.00390625,-128) [-128|127.99609375] "m/s"  DASy
 SG_ RFC_Loc044_Theta : 64|16@1+ (0.01,-327.68) [-90|90] "deg"  DASy
 SG_ RFC_Loc044_Phi : 80|16@1+ (0.01,-327.68) [-30|30] "deg"  DASy
 SG_ RFC_Loc044_DrVnce : 96|16@1+ (1.52588E-005,0) [0|0.999984741210937] "m^2"  DASy
 SG_ RFC_Loc044_VrVnce : 112|16@1+ (1.52588E-005,0) [0|0.999984741210937] "m^2/s^2"  DASy
 SG_ RFC_Loc044_ThetaVnce : 128|16@1+ (0.00390625,0) [0|255.99609375] "deg^2"  DASy
 SG_ RFC_Loc044_PhiVnce : 144|16@1+ (0.00390625,0) [0|255.99609375] "deg^2"  DASy
 SG_ RFC_Loc044_RCS : 176|16@1+ (0.00390625,-128) [-128|127.99609375] "dBsm"  DASy
 SG_ RFC_Loc044_RSSI : 192|16@1+ (0.00195312,0) [0|127.998046875] "dimensionless"  DASy
 SG_ RFC_Loc045_Dr : 256|16@1+ (0.0078125,0) [0|511.9921875] "m"  DASy
 SG_ RFC_Loc045_Vr : 272|16@1+ (0.00390625,-128) [-128|127.99609375] "m/s"  DASy
 SG_ RFC_Loc045_Theta : 288|16@1+ (0.01,-327.68) [-90|90] "deg"  DASy
 SG_ RFC_Loc045_Phi : 304|16@1+ (0.01,-327.68) [-30|30] "deg"  DASy
 SG_ RFC_Loc045_DrVnce : 320|16@1+ (1.52588E-005,0) [0|0.999984741210937] "m^2"  DASy
 SG_ RFC_Loc045_VrVnce : 336|16@1+ (1.52588E-005,0) [0|0.999984741210937] "m^2/s^2"  DASy
 SG_ RFC_Loc045_ThetaVnce : 352|16@1+ (0.00390625,0) [0|255.99609375] "deg^2"  DASy
 SG_ RFC_Loc045_PhiVnce : 368|16@1+ (0.00390625,0) [0|255.99609375] "deg^2"  DASy
 SG_ RFC_Loc045_RCS : 400|16@1+ (0.00390625,-128) [-128|127.99609375] "dBsm"  DASy
 SG_ RFC_Loc045_RSSI : 416|16@1+ (0.00195312,0) [0|127.998046875] "dimensionless"  DASy

BO_ 423 RFC_Location_046_047: 64 RadarFrontCenter
 SG_ RFC_Loc046_CRC : 0|16@1+ (1,0) [0|65535] ""  DASy
 SG_ RFC_Loc046_AliveCtr : 16|8@1+ (1,0) [0|255] ""  DASy
 SG_ RFC_Loc046_ProtBlockCtr : 24|8@1+ (1,0) [0|255] ""  DASy
 SG_ RFC_Loc046_Dr : 32|16@1+ (0.0078125,0) [0|511.9921875] "m"  DASy
 SG_ RFC_Loc046_Vr : 48|16@1+ (0.00390625,-128) [-128|127.99609375] "m/s"  DASy
 SG_ RFC_Loc046_Theta : 64|16@1+ (0.01,-327.68) [-90|90] "deg"  DASy
 SG_ RFC_Loc046_Phi : 80|16@1+ (0.01,-327.68) [-30|30] "deg"  DASy
 SG_ RFC_Loc046_DrVnce : 96|16@1+ (1.52588E-005,0) [0|0.999984741210937] "m^2"  DASy
 SG_ RFC_Loc046_VrVnce : 112|16@1+ (1.52588E-005,0) [0|0.999984741210937] "m^2/s^2"  DASy
 SG_ RFC_Loc046_ThetaVnce : 128|16@1+ (0.00390625,0) [0|255.99609375] "deg^2"  DASy
 SG_ RFC_Loc046_PhiVnce : 144|16@1+ (0.00390625,0) [0|255.99609375] "deg^2"  DASy
 SG_ RFC_Loc046_RCS : 176|16@1+ (0.00390625,-128) [-128|127.99609375] "dBsm"  DASy
 SG_ RFC_Loc046_RSSI : 192|16@1+ (0.00195312,0) [0|127.998046875] "dimensionless"  DASy
 SG_ RFC_Loc047_Dr : 256|16@1+ (0.0078125,0) [0|511.9921875] "m"  DASy
 SG_ RFC_Loc047_Vr : 272|16@1+ (0.00390625,-128) [-128|127.99609375] "m/s"  DASy
 SG_ RFC_Loc047_Theta : 288|16@1+ (0.01,-327.68) [-90|90] "deg"  DASy
 SG_ RFC_Loc047_Phi : 304|16@1+ (0.01,-327.68) [-30|30] "deg"  DASy
 SG_ RFC_Loc047_DrVnce : 320|16@1+ (1.52588E-005,0) [0|0.999984741210937] "m^2"  DASy
 SG_ RFC_Loc047_VrVnce : 336|16@1+ (1.52588E-005,0) [0|0.999984741210937] "m^2/s^2"  DASy
 SG_ RFC_Loc047_ThetaVnce : 352|16@1+ (0.00390625,0) [0|255.99609375] "deg^2"  DASy
 SG_ RFC_Loc047_PhiVnce : 368|16@1+ (0.00390625,0) [0|255.99609375] "deg^2"  DASy
 SG_ RFC_Loc047_RCS : 400|16@1+ (0.00390625,-128) [-128|127.99609375] "dBsm"  DASy
 SG_ RFC_Loc047_RSSI : 416|16@1+ (0.00195312,0) [0|127.998046875] "dimensionless"  DASy

BO_ 424 RFC_Location_048_049: 64 RadarFrontCenter
 SG_ RFC_Loc048_CRC : 0|16@1+ (1,0) [0|65535] ""  DASy
 SG_ RFC_Loc048_AliveCtr : 16|8@1+ (1,0) [0|255] ""  DASy
 SG_ RFC_Loc048_ProtBlockCtr : 24|8@1+ (1,0) [0|255] ""  DASy
 SG_ RFC_Loc048_Dr : 32|16@1+ (0.0078125,0) [0|511.9921875] "m"  DASy
 SG_ RFC_Loc048_Vr : 48|16@1+ (0.00390625,-128) [-128|127.99609375] "m/s"  DASy
 SG_ RFC_Loc048_Theta : 64|16@1+ (0.01,-327.68) [-90|90] "deg"  DASy
 SG_ RFC_Loc048_Phi : 80|16@1+ (0.01,-327.68) [-30|30] "deg"  DASy
 SG_ RFC_Loc048_DrVnce : 96|16@1+ (1.52588E-005,0) [0|0.999984741210937] "m^2"  DASy
 SG_ RFC_Loc048_VrVnce : 112|16@1+ (1.52588E-005,0) [0|0.999984741210937] "m^2/s^2"  DASy
 SG_ RFC_Loc048_ThetaVnce : 128|16@1+ (0.00390625,0) [0|255.99609375] "deg^2"  DASy
 SG_ RFC_Loc048_PhiVnce : 144|16@1+ (0.00390625,0) [0|255.99609375] "deg^2"  DASy
 SG_ RFC_Loc048_RCS : 176|16@1+ (0.00390625,-128) [-128|127.99609375] "dBsm"  DASy
 SG_ RFC_Loc048_RSSI : 192|16@1+ (0.00195312,0) [0|127.998046875] "dimensionless"  DASy
 SG_ RFC_Loc049_Dr : 256|16@1+ (0.0078125,0) [0|511.9921875] "m"  DASy
 SG_ RFC_Loc049_Vr : 272|16@1+ (0.00390625,-128) [-128|127.99609375] "m/s"  DASy
 SG_ RFC_Loc049_Theta : 288|16@1+ (0.01,-327.68) [-90|90] "deg"  DASy
 SG_ RFC_Loc049_Phi : 304|16@1+ (0.01,-327.68) [-30|30] "deg"  DASy
 SG_ RFC_Loc049_DrVnce : 320|16@1+ (1.52588E-005,0) [0|0.999984741210937] "m^2"  DASy
 SG_ RFC_Loc049_VrVnce : 336|16@1+ (1.52588E-005,0) [0|0.999984741210937] "m^2/s^2"  DASy
 SG_ RFC_Loc049_ThetaVnce : 352|16@1+ (0.00390625,0) [0|255.99609375] "deg^2"  DASy
 SG_ RFC_Loc049_PhiVnce : 368|16@1+ (0.00390625,0) [0|255.99609375] "deg^2"  DASy
 SG_ RFC_Loc049_RCS : 400|16@1+ (0.00390625,-128) [-128|127.99609375] "dBsm"  DASy
 SG_ RFC_Loc049_RSSI : 416|16@1+ (0.00195312,0) [0|127.998046875] "dimensionless"  DASy

BO_ 425 RFC_Location_050_051: 64 RadarFrontCenter
 SG_ RFC_Loc050_CRC : 0|16@1+ (1,0) [0|65535] ""  DASy
 SG_ RFC_Loc050_AliveCtr : 16|8@1+ (1,0) [0|255] ""  DASy
 SG_ RFC_Loc050_ProtBlockCtr : 24|8@1+ (1,0) [0|255] ""  DASy
 SG_ RFC_Loc050_Dr : 32|16@1+ (0.0078125,0) [0|511.9921875] "m"  DASy
 SG_ RFC_Loc050_Vr : 48|16@1+ (0.00390625,-128) [-128|127.99609375] "m/s"  DASy
 SG_ RFC_Loc050_Theta : 64|16@1+ (0.01,-327.68) [-90|90] "deg"  DASy
 SG_ RFC_Loc050_Phi : 80|16@1+ (0.01,-327.68) [-30|30] "deg"  DASy
 SG_ RFC_Loc050_DrVnce : 96|16@1+ (1.52588E-005,0) [0|0.999984741210937] "m^2"  DASy
 SG_ RFC_Loc050_VrVnce : 112|16@1+ (1.52588E-005,0) [0|0.999984741210937] "m^2/s^2"  DASy
 SG_ RFC_Loc050_ThetaVnce : 128|16@1+ (0.00390625,0) [0|255.99609375] "deg^2"  DASy
 SG_ RFC_Loc050_PhiVnce : 144|16@1+ (0.00390625,0) [0|255.99609375] "deg^2"  DASy
 SG_ RFC_Loc050_RCS : 176|16@1+ (0.00390625,-128) [-128|127.99609375] "dBsm"  DASy
 SG_ RFC_Loc050_RSSI : 192|16@1+ (0.00195312,0) [0|127.998046875] "dimensionless"  DASy
 SG_ RFC_Loc051_Dr : 256|16@1+ (0.0078125,0) [0|511.9921875] "m"  DASy
 SG_ RFC_Loc051_Vr : 272|16@1+ (0.00390625,-128) [-128|127.99609375] "m/s"  DASy
 SG_ RFC_Loc051_Theta : 288|16@1+ (0.01,-327.68) [-90|90] "deg"  DASy
 SG_ RFC_Loc051_Phi : 304|16@1+ (0.01,-327.68) [-30|30] "deg"  DASy
 SG_ RFC_Loc051_DrVnce : 320|16@1+ (1.52588E-005,0) [0|0.999984741210937] "m^2"  DASy
 SG_ RFC_Loc051_VrVnce : 336|16@1+ (1.52588E-005,0) [0|0.999984741210937] "m^2/s^2"  DASy
 SG_ RFC_Loc051_ThetaVnce : 352|16@1+ (0.00390625,0) [0|255.99609375] "deg^2"  DASy
 SG_ RFC_Loc051_PhiVnce : 368|16@1+ (0.00390625,0) [0|255.99609375] "deg^2"  DASy
 SG_ RFC_Loc051_RCS : 400|16@1+ (0.00390625,-128) [-128|127.99609375] "dBsm"  DASy
 SG_ RFC_Loc051_RSSI : 416|16@1+ (0.00195312,0) [0|127.998046875] "dimensionless"  DASy

BO_ 426 RFC_Location_052_053: 64 RadarFrontCenter
 SG_ RFC_Loc052_CRC : 0|16@1+ (1,0) [0|65535] ""  DASy
 SG_ RFC_Loc052_AliveCtr : 16|8@1+ (1,0) [0|255] ""  DASy
 SG_ RFC_Loc052_ProtBlockCtr : 24|8@1+ (1,0) [0|255] ""  DASy
 SG_ RFC_Loc052_Dr : 32|16@1+ (0.0078125,0) [0|511.9921875] "m"  DASy
 SG_ RFC_Loc052_Vr : 48|16@1+ (0.00390625,-128) [-128|127.99609375] "m/s"  DASy
 SG_ RFC_Loc052_Theta : 64|16@1+ (0.01,-327.68) [-90|90] "deg"  DASy
 SG_ RFC_Loc052_Phi : 80|16@1+ (0.01,-327.68) [-30|30] "deg"  DASy
 SG_ RFC_Loc052_DrVnce : 96|16@1+ (1.52588E-005,0) [0|0.999984741210937] "m^2"  DASy
 SG_ RFC_Loc052_VrVnce : 112|16@1+ (1.52588E-005,0) [0|0.999984741210937] "m^2/s^2"  DASy
 SG_ RFC_Loc052_ThetaVnce : 128|16@1+ (0.00390625,0) [0|255.99609375] "deg^2"  DASy
 SG_ RFC_Loc052_PhiVnce : 144|16@1+ (0.00390625,0) [0|255.99609375] "deg^2"  DASy
 SG_ RFC_Loc052_RCS : 176|16@1+ (0.00390625,-128) [-128|127.99609375] "dBsm"  DASy
 SG_ RFC_Loc052_RSSI : 192|16@1+ (0.00195312,0) [0|127.998046875] "dimensionless"  DASy
 SG_ RFC_Loc053_Dr : 256|16@1+ (0.0078125,0) [0|511.9921875] "m"  DASy
 SG_ RFC_Loc053_Vr : 272|16@1+ (0.00390625,-128) [-128|127.99609375] "m/s"  DASy
 SG_ RFC_Loc053_Theta : 288|16@1+ (0.01,-327.68) [-90|90] "deg"  DASy
 SG_ RFC_Loc053_Phi : 304|16@1+ (0.01,-327.68) [-30|30] "deg"  DASy
 SG_ RFC_Loc053_DrVnce : 320|16@1+ (1.52588E-005,0) [0|0.999984741210937] "m^2"  DASy
 SG_ RFC_Loc053_VrVnce : 336|16@1+ (1.52588E-005,0) [0|0.999984741210937] "m^2/s^2"  DASy
 SG_ RFC_Loc053_ThetaVnce : 352|16@1+ (0.00390625,0) [0|255.99609375] "deg^2"  DASy
 SG_ RFC_Loc053_PhiVnce : 368|16@1+ (0.00390625,0) [0|255.99609375] "deg^2"  DASy
 SG_ RFC_Loc053_RCS : 400|16@1+ (0.00390625,-128) [-128|127.99609375] "dBsm"  DASy
 SG_ RFC_Loc053_RSSI : 416|16@1+ (0.00195312,0) [0|127.998046875] "dimensionless"  DASy

BO_ 427 RFC_Location_054_055: 64 RadarFrontCenter
 SG_ RFC_Loc054_CRC : 0|16@1+ (1,0) [0|65535] ""  DASy
 SG_ RFC_Loc054_AliveCtr : 16|8@1+ (1,0) [0|255] ""  DASy
 SG_ RFC_Loc054_ProtBlockCtr : 24|8@1+ (1,0) [0|255] ""  DASy
 SG_ RFC_Loc054_Dr : 32|16@1+ (0.0078125,0) [0|511.9921875] "m"  DASy
 SG_ RFC_Loc054_Vr : 48|16@1+ (0.00390625,-128) [-128|127.99609375] "m/s"  DASy
 SG_ RFC_Loc054_Theta : 64|16@1+ (0.01,-327.68) [-90|90] "deg"  DASy
 SG_ RFC_Loc054_Phi : 80|16@1+ (0.01,-327.68) [-30|30] "deg"  DASy
 SG_ RFC_Loc054_DrVnce : 96|16@1+ (1.52588E-005,0) [0|0.999984741210937] "m^2"  DASy
 SG_ RFC_Loc054_VrVnce : 112|16@1+ (1.52588E-005,0) [0|0.999984741210937] "m^2/s^2"  DASy
 SG_ RFC_Loc054_ThetaVnce : 128|16@1+ (0.00390625,0) [0|255.99609375] "deg^2"  DASy
 SG_ RFC_Loc054_PhiVnce : 144|16@1+ (0.00390625,0) [0|255.99609375] "deg^2"  DASy
 SG_ RFC_Loc054_RCS : 176|16@1+ (0.00390625,-128) [-128|127.99609375] "dBsm"  DASy
 SG_ RFC_Loc054_RSSI : 192|16@1+ (0.00195312,0) [0|127.998046875] "dimensionless"  DASy
 SG_ RFC_Loc055_Dr : 256|16@1+ (0.0078125,0) [0|511.9921875] "m"  DASy
 SG_ RFC_Loc055_Vr : 272|16@1+ (0.00390625,-128) [-128|127.99609375] "m/s"  DASy
 SG_ RFC_Loc055_Theta : 288|16@1+ (0.01,-327.68) [-90|90] "deg"  DASy
 SG_ RFC_Loc055_Phi : 304|16@1+ (0.01,-327.68) [-30|30] "deg"  DASy
 SG_ RFC_Loc055_DrVnce : 320|16@1+ (1.52588E-005,0) [0|0.999984741210937] "m^2"  DASy
 SG_ RFC_Loc055_VrVnce : 336|16@1+ (1.52588E-005,0) [0|0.999984741210937] "m^2/s^2"  DASy
 SG_ RFC_Loc055_ThetaVnce : 352|16@1+ (0.00390625,0) [0|255.99609375] "deg^2"  DASy
 SG_ RFC_Loc055_PhiVnce : 368|16@1+ (0.00390625,0) [0|255.99609375] "deg^2"  DASy
 SG_ RFC_Loc055_RCS : 400|16@1+ (0.00390625,-128) [-128|127.99609375] "dBsm"  DASy
 SG_ RFC_Loc055_RSSI : 416|16@1+ (0.00195312,0) [0|127.998046875] "dimensionless"  DASy

CM_ "for BJEV BL05";
CM_ BO_ 255 "AUTOSAR Time Sync";
CM_ SG_ 255 ADAS_SYNC_FC_OVS "in FUP PDU
OVS = Overflow of seconds";
CM_ SG_ 255 ADAS_SYNC_FC_SGW "in FUP PDU
SyncToGTM = 0
SyncToSubDomain = 1";
CM_ SG_ 255 ADAS_SYNC_FC_Reserved "in FUP PDU
reserved, default =0";
CM_ SG_ 255 ADAS_SYNC_FC_SyncTime "TSync: SyncTimeSec = 32 bit LSB of the 48 bits seconds part of the time
TSync FUP: SyncTimeNSec = 32 Bit time value in nanoseconds";
CM_ SG_ 255 ADAS_SYNC_FC_TimeDomain "Time Domain";
CM_ SG_ 255 ADAS_SYNC_FC_SequenceCnt "Sequence counter";
CM_ SG_ 255 ADAS_SYNC_FC_CRC "CRC";
CM_ SG_ 255 ADAS_SYNC_FC_Type "Type=0x20 : TSync    Type=0x28 : TSync FUP";
CM_ SG_ 384 RFC_Hdr00_CRC "CRC - Autosar E2E Profile 5";
CM_ SG_ 384 RFC_Hdr00_AliveCtr "Alive counter - Autosar E2E Profile 5";
CM_ SG_ 384 RFC_Hdr00_ProtBlockCtr "Protocol-Signal: Block-Counter";
CM_ SG_ 384 RFC_Hdr00_ProtLocationCount "number of detected VALID Locations that have been sent to the bus";
CM_ SG_ 384 RFC_Hdr00_SensorState "The sensor shall provide its operation state.
In case of multiple errors the most severe state shall be sent.";
CM_ SG_ 384 RFC_Hdr00_TimeStamp "Time Stamp";
CM_ SG_ 384 RFC_Hdr00_TimeStampStatus "Autosar StbM_TimeBaseStatusType bitfield with extension:
Bit 0: TIMEOUT
Bit 1: Reserved1
Bit 2: SYNC_TO_GATEWAY
Bit 3: GLOBAL_TIME_BASE
Bit 4: TIMELEAP_FUTURE
Bit 5: TIMELEAP_PAST
Bit 6: Reserved6
Bit 7: Extension: GENERAL_ERROR";
CM_ SG_ 400 RFC_Loc000_CRC "CRC - Autosar E2E Profile 5, DataID = TBD";
CM_ SG_ 400 RFC_Loc000_AliveCtr "Alive counter - Autosar E2E Profile 5";
CM_ SG_ 400 RFC_Loc000_ProtBlockCtr "Protocol-Signal: Block-Counter";
CM_ SG_ 400 RFC_Loc000_Dr "Location radial distance";
CM_ SG_ 400 RFC_Loc000_Vr "Location radial relative velocity";
CM_ SG_ 400 RFC_Loc000_Theta "Location azimuth angle. \"Not a number\" TBD";
CM_ SG_ 400 RFC_Loc000_Phi "Location elevation angle. \"Not a number\" TBD";
CM_ SG_ 400 RFC_Loc000_DrVnce "Variance of Location radial distance";
CM_ SG_ 400 RFC_Loc000_VrVnce "Variance of Location radial relative velocity";
CM_ SG_ 400 RFC_Loc000_ThetaVnce "Variance of Location azimuth angle";
CM_ SG_ 400 RFC_Loc000_PhiVnce "Variance of Location elevation angle";
CM_ SG_ 400 RFC_Loc000_RCS "Radar Cross Section (RCS) estimation";
CM_ SG_ 400 RFC_Loc000_RSSI "Received Signal Strength Indication (RSSI)";
CM_ SG_ 400 RFC_Loc001_Dr "Location radial distance";
CM_ SG_ 400 RFC_Loc001_Vr "Location radial relative velocity";
CM_ SG_ 400 RFC_Loc001_Theta "Location azimuth angle. \"Not a number\" TBD";
CM_ SG_ 400 RFC_Loc001_Phi "Location elevation angle. \"Not a number\" TBD";
CM_ SG_ 400 RFC_Loc001_DrVnce "Variance of Location radial distance";
CM_ SG_ 400 RFC_Loc001_VrVnce "Variance of Location radial relative velocity";
CM_ SG_ 400 RFC_Loc001_ThetaVnce "Variance of Location azimuth angle";
CM_ SG_ 400 RFC_Loc001_PhiVnce "Variance of Location elevation angle";
CM_ SG_ 400 RFC_Loc001_RCS "Radar Cross Section (RCS) estimation";
CM_ SG_ 400 RFC_Loc001_RSSI "Received Signal Strength Indication (RSSI)";
CM_ SG_ 401 RFC_Loc002_CRC "CRC - Autosar E2E Profile 5, DataID = TBD";
CM_ SG_ 401 RFC_Loc002_AliveCtr "Alive counter - Autosar E2E Profile 5";
CM_ SG_ 401 RFC_Loc002_ProtBlockCtr "Protocol-Signal: Block-Counter";
CM_ SG_ 401 RFC_Loc002_Dr "Location radial distance";
CM_ SG_ 401 RFC_Loc002_Vr "Location radial relative velocity";
CM_ SG_ 401 RFC_Loc002_Theta "Location azimuth angle. \"Not a number\" TBD";
CM_ SG_ 401 RFC_Loc002_Phi "Location elevation angle. \"Not a number\" TBD";
CM_ SG_ 401 RFC_Loc002_DrVnce "Variance of Location radial distance";
CM_ SG_ 401 RFC_Loc002_VrVnce "Variance of Location radial relative velocity";
CM_ SG_ 401 RFC_Loc002_ThetaVnce "Variance of Location azimuth angle";
CM_ SG_ 401 RFC_Loc002_PhiVnce "Variance of Location elevation angle";
CM_ SG_ 401 RFC_Loc002_RCS "Radar Cross Section (RCS) estimation";
CM_ SG_ 401 RFC_Loc002_RSSI "Received Signal Strength Indication (RSSI)";
CM_ SG_ 401 RFC_Loc003_Dr "Location radial distance";
CM_ SG_ 401 RFC_Loc003_Vr "Location radial relative velocity";
CM_ SG_ 401 RFC_Loc003_Theta "Location azimuth angle. \"Not a number\" TBD";
CM_ SG_ 401 RFC_Loc003_Phi "Location elevation angle. \"Not a number\" TBD";
CM_ SG_ 401 RFC_Loc003_DrVnce "Variance of Location radial distance";
CM_ SG_ 401 RFC_Loc003_VrVnce "Variance of Location radial relative velocity";
CM_ SG_ 401 RFC_Loc003_ThetaVnce "Variance of Location azimuth angle";
CM_ SG_ 401 RFC_Loc003_PhiVnce "Variance of Location elevation angle";
CM_ SG_ 401 RFC_Loc003_RCS "Radar Cross Section (RCS) estimation";
CM_ SG_ 401 RFC_Loc003_RSSI "Received Signal Strength Indication (RSSI)";
CM_ SG_ 402 RFC_Loc004_CRC "CRC - Autosar E2E Profile 5, DataID = TBD";
CM_ SG_ 402 RFC_Loc004_AliveCtr "Alive counter - Autosar E2E Profile 5";
CM_ SG_ 402 RFC_Loc004_ProtBlockCtr "Protocol-Signal: Block-Counter";
CM_ SG_ 402 RFC_Loc004_Dr "Location radial distance";
CM_ SG_ 402 RFC_Loc004_Vr "Location radial relative velocity";
CM_ SG_ 402 RFC_Loc004_Theta "Location azimuth angle. \"Not a number\" TBD";
CM_ SG_ 402 RFC_Loc004_Phi "Location elevation angle. \"Not a number\" TBD";
CM_ SG_ 402 RFC_Loc004_DrVnce "Variance of Location radial distance";
CM_ SG_ 402 RFC_Loc004_VrVnce "Variance of Location radial relative velocity";
CM_ SG_ 402 RFC_Loc004_ThetaVnce "Variance of Location azimuth angle";
CM_ SG_ 402 RFC_Loc004_PhiVnce "Variance of Location elevation angle";
CM_ SG_ 402 RFC_Loc004_RCS "Radar Cross Section (RCS) estimation";
CM_ SG_ 402 RFC_Loc004_RSSI "Received Signal Strength Indication (RSSI)";
CM_ SG_ 402 RFC_Loc005_Dr "Location radial distance";
CM_ SG_ 402 RFC_Loc005_Vr "Location radial relative velocity";
CM_ SG_ 402 RFC_Loc005_Theta "Location azimuth angle. \"Not a number\" TBD";
CM_ SG_ 402 RFC_Loc005_Phi "Location elevation angle. \"Not a number\" TBD";
CM_ SG_ 402 RFC_Loc005_DrVnce "Variance of Location radial distance";
CM_ SG_ 402 RFC_Loc005_VrVnce "Variance of Location radial relative velocity";
CM_ SG_ 402 RFC_Loc005_ThetaVnce "Variance of Location azimuth angle";
CM_ SG_ 402 RFC_Loc005_PhiVnce "Variance of Location elevation angle";
CM_ SG_ 402 RFC_Loc005_RCS "Radar Cross Section (RCS) estimation";
CM_ SG_ 402 RFC_Loc005_RSSI "Received Signal Strength Indication (RSSI)";
CM_ SG_ 403 RFC_Loc006_CRC "CRC - Autosar E2E Profile 5, DataID = TBD";
CM_ SG_ 403 RFC_Loc006_AliveCtr "Alive counter - Autosar E2E Profile 5";
CM_ SG_ 403 RFC_Loc006_ProtBlockCtr "Protocol-Signal: Block-Counter";
CM_ SG_ 403 RFC_Loc006_Dr "Location radial distance";
CM_ SG_ 403 RFC_Loc006_Vr "Location radial relative velocity";
CM_ SG_ 403 RFC_Loc006_Theta "Location azimuth angle. \"Not a number\" TBD";
CM_ SG_ 403 RFC_Loc006_Phi "Location elevation angle. \"Not a number\" TBD";
CM_ SG_ 403 RFC_Loc006_DrVnce "Variance of Location radial distance";
CM_ SG_ 403 RFC_Loc006_VrVnce "Variance of Location radial relative velocity";
CM_ SG_ 403 RFC_Loc006_ThetaVnce "Variance of Location azimuth angle";
CM_ SG_ 403 RFC_Loc006_PhiVnce "Variance of Location elevation angle";
CM_ SG_ 403 RFC_Loc006_RCS "Radar Cross Section (RCS) estimation";
CM_ SG_ 403 RFC_Loc006_RSSI "Received Signal Strength Indication (RSSI)";
CM_ SG_ 403 RFC_Loc007_Dr "Location radial distance";
CM_ SG_ 403 RFC_Loc007_Vr "Location radial relative velocity";
CM_ SG_ 403 RFC_Loc007_Theta "Location azimuth angle. \"Not a number\" TBD";
CM_ SG_ 403 RFC_Loc007_Phi "Location elevation angle. \"Not a number\" TBD";
CM_ SG_ 403 RFC_Loc007_DrVnce "Variance of Location radial distance";
CM_ SG_ 403 RFC_Loc007_VrVnce "Variance of Location radial relative velocity";
CM_ SG_ 403 RFC_Loc007_ThetaVnce "Variance of Location azimuth angle";
CM_ SG_ 403 RFC_Loc007_PhiVnce "Variance of Location elevation angle";
CM_ SG_ 403 RFC_Loc007_RCS "Radar Cross Section (RCS) estimation";
CM_ SG_ 403 RFC_Loc007_RSSI "Received Signal Strength Indication (RSSI)";
CM_ SG_ 404 RFC_Loc008_CRC "CRC - Autosar E2E Profile 5, DataID = TBD";
CM_ SG_ 404 RFC_Loc008_AliveCtr "Alive counter - Autosar E2E Profile 5";
CM_ SG_ 404 RFC_Loc008_ProtBlockCtr "Protocol-Signal: Block-Counter";
CM_ SG_ 404 RFC_Loc008_Dr "Location radial distance";
CM_ SG_ 404 RFC_Loc008_Vr "Location radial relative velocity";
CM_ SG_ 404 RFC_Loc008_Theta "Location azimuth angle. \"Not a number\" TBD";
CM_ SG_ 404 RFC_Loc008_Phi "Location elevation angle. \"Not a number\" TBD";
CM_ SG_ 404 RFC_Loc008_DrVnce "Variance of Location radial distance";
CM_ SG_ 404 RFC_Loc008_VrVnce "Variance of Location radial relative velocity";
CM_ SG_ 404 RFC_Loc008_ThetaVnce "Variance of Location azimuth angle";
CM_ SG_ 404 RFC_Loc008_PhiVnce "Variance of Location elevation angle";
CM_ SG_ 404 RFC_Loc008_RCS "Radar Cross Section (RCS) estimation";
CM_ SG_ 404 RFC_Loc008_RSSI "Received Signal Strength Indication (RSSI)";
CM_ SG_ 404 RFC_Loc009_Dr "Location radial distance";
CM_ SG_ 404 RFC_Loc009_Vr "Location radial relative velocity";
CM_ SG_ 404 RFC_Loc009_Theta "Location azimuth angle. \"Not a number\" TBD";
CM_ SG_ 404 RFC_Loc009_Phi "Location elevation angle. \"Not a number\" TBD";
CM_ SG_ 404 RFC_Loc009_DrVnce "Variance of Location radial distance";
CM_ SG_ 404 RFC_Loc009_VrVnce "Variance of Location radial relative velocity";
CM_ SG_ 404 RFC_Loc009_ThetaVnce "Variance of Location azimuth angle";
CM_ SG_ 404 RFC_Loc009_PhiVnce "Variance of Location elevation angle";
CM_ SG_ 404 RFC_Loc009_RCS "Radar Cross Section (RCS) estimation";
CM_ SG_ 404 RFC_Loc009_RSSI "Received Signal Strength Indication (RSSI)";
CM_ SG_ 405 RFC_Loc010_CRC "CRC - Autosar E2E Profile 5, DataID = TBD";
CM_ SG_ 405 RFC_Loc010_AliveCtr "Alive counter - Autosar E2E Profile 5";
CM_ SG_ 405 RFC_Loc010_ProtBlockCtr "Protocol-Signal: Block-Counter";
CM_ SG_ 405 RFC_Loc010_Dr "Location radial distance";
CM_ SG_ 405 RFC_Loc010_Vr "Location radial relative velocity";
CM_ SG_ 405 RFC_Loc010_Theta "Location azimuth angle. \"Not a number\" TBD";
CM_ SG_ 405 RFC_Loc010_Phi "Location elevation angle. \"Not a number\" TBD";
CM_ SG_ 405 RFC_Loc010_DrVnce "Variance of Location radial distance";
CM_ SG_ 405 RFC_Loc010_VrVnce "Variance of Location radial relative velocity";
CM_ SG_ 405 RFC_Loc010_ThetaVnce "Variance of Location azimuth angle";
CM_ SG_ 405 RFC_Loc010_PhiVnce "Variance of Location elevation angle";
CM_ SG_ 405 RFC_Loc010_RCS "Radar Cross Section (RCS) estimation";
CM_ SG_ 405 RFC_Loc010_RSSI "Received Signal Strength Indication (RSSI)";
CM_ SG_ 405 RFC_Loc011_Dr "Location radial distance";
CM_ SG_ 405 RFC_Loc011_Vr "Location radial relative velocity";
CM_ SG_ 405 RFC_Loc011_Theta "Location azimuth angle. \"Not a number\" TBD";
CM_ SG_ 405 RFC_Loc011_Phi "Location elevation angle. \"Not a number\" TBD";
CM_ SG_ 405 RFC_Loc011_DrVnce "Variance of Location radial distance";
CM_ SG_ 405 RFC_Loc011_VrVnce "Variance of Location radial relative velocity";
CM_ SG_ 405 RFC_Loc011_ThetaVnce "Variance of Location azimuth angle";
CM_ SG_ 405 RFC_Loc011_PhiVnce "Variance of Location elevation angle";
CM_ SG_ 405 RFC_Loc011_RCS "Radar Cross Section (RCS) estimation";
CM_ SG_ 405 RFC_Loc011_RSSI "Received Signal Strength Indication (RSSI)";
CM_ SG_ 406 RFC_Loc012_CRC "CRC - Autosar E2E Profile 5, DataID = TBD";
CM_ SG_ 406 RFC_Loc012_AliveCtr "Alive counter - Autosar E2E Profile 5";
CM_ SG_ 406 RFC_Loc012_ProtBlockCtr "Protocol-Signal: Block-Counter";
CM_ SG_ 406 RFC_Loc012_Dr "Location radial distance";
CM_ SG_ 406 RFC_Loc012_Vr "Location radial relative velocity";
CM_ SG_ 406 RFC_Loc012_Theta "Location azimuth angle. \"Not a number\" TBD";
CM_ SG_ 406 RFC_Loc012_Phi "Location elevation angle. \"Not a number\" TBD";
CM_ SG_ 406 RFC_Loc012_DrVnce "Variance of Location radial distance";
CM_ SG_ 406 RFC_Loc012_VrVnce "Variance of Location radial relative velocity";
CM_ SG_ 406 RFC_Loc012_ThetaVnce "Variance of Location azimuth angle";
CM_ SG_ 406 RFC_Loc012_PhiVnce "Variance of Location elevation angle";
CM_ SG_ 406 RFC_Loc012_RCS "Radar Cross Section (RCS) estimation";
CM_ SG_ 406 RFC_Loc012_RSSI "Received Signal Strength Indication (RSSI)";
CM_ SG_ 406 RFC_Loc013_Dr "Location radial distance";
CM_ SG_ 406 RFC_Loc013_Vr "Location radial relative velocity";
CM_ SG_ 406 RFC_Loc013_Theta "Location azimuth angle. \"Not a number\" TBD";
CM_ SG_ 406 RFC_Loc013_Phi "Location elevation angle. \"Not a number\" TBD";
CM_ SG_ 406 RFC_Loc013_DrVnce "Variance of Location radial distance";
CM_ SG_ 406 RFC_Loc013_VrVnce "Variance of Location radial relative velocity";
CM_ SG_ 406 RFC_Loc013_ThetaVnce "Variance of Location azimuth angle";
CM_ SG_ 406 RFC_Loc013_PhiVnce "Variance of Location elevation angle";
CM_ SG_ 406 RFC_Loc013_RCS "Radar Cross Section (RCS) estimation";
CM_ SG_ 406 RFC_Loc013_RSSI "Received Signal Strength Indication (RSSI)";
CM_ SG_ 407 RFC_Loc014_CRC "CRC - Autosar E2E Profile 5, DataID = TBD";
CM_ SG_ 407 RFC_Loc014_AliveCtr "Alive counter - Autosar E2E Profile 5";
CM_ SG_ 407 RFC_Loc014_ProtBlockCtr "Protocol-Signal: Block-Counter";
CM_ SG_ 407 RFC_Loc014_Dr "Location radial distance";
CM_ SG_ 407 RFC_Loc014_Vr "Location radial relative velocity";
CM_ SG_ 407 RFC_Loc014_Theta "Location azimuth angle. \"Not a number\" TBD";
CM_ SG_ 407 RFC_Loc014_Phi "Location elevation angle. \"Not a number\" TBD";
CM_ SG_ 407 RFC_Loc014_DrVnce "Variance of Location radial distance";
CM_ SG_ 407 RFC_Loc014_VrVnce "Variance of Location radial relative velocity";
CM_ SG_ 407 RFC_Loc014_ThetaVnce "Variance of Location azimuth angle";
CM_ SG_ 407 RFC_Loc014_PhiVnce "Variance of Location elevation angle";
CM_ SG_ 407 RFC_Loc014_RCS "Radar Cross Section (RCS) estimation";
CM_ SG_ 407 RFC_Loc014_RSSI "Received Signal Strength Indication (RSSI)";
CM_ SG_ 407 RFC_Loc015_Dr "Location radial distance";
CM_ SG_ 407 RFC_Loc015_Vr "Location radial relative velocity";
CM_ SG_ 407 RFC_Loc015_Theta "Location azimuth angle. \"Not a number\" TBD";
CM_ SG_ 407 RFC_Loc015_Phi "Location elevation angle. \"Not a number\" TBD";
CM_ SG_ 407 RFC_Loc015_DrVnce "Variance of Location radial distance";
CM_ SG_ 407 RFC_Loc015_VrVnce "Variance of Location radial relative velocity";
CM_ SG_ 407 RFC_Loc015_ThetaVnce "Variance of Location azimuth angle";
CM_ SG_ 407 RFC_Loc015_PhiVnce "Variance of Location elevation angle";
CM_ SG_ 407 RFC_Loc015_RCS "Radar Cross Section (RCS) estimation";
CM_ SG_ 407 RFC_Loc015_RSSI "Received Signal Strength Indication (RSSI)";
CM_ SG_ 408 RFC_Loc016_CRC "CRC - Autosar E2E Profile 5, DataID = TBD";
CM_ SG_ 408 RFC_Loc016_AliveCtr "Alive counter - Autosar E2E Profile 5";
CM_ SG_ 408 RFC_Loc016_ProtBlockCtr "Protocol-Signal: Block-Counter";
CM_ SG_ 408 RFC_Loc016_Dr "Location radial distance";
CM_ SG_ 408 RFC_Loc016_Vr "Location radial relative velocity";
CM_ SG_ 408 RFC_Loc016_Theta "Location azimuth angle. \"Not a number\" TBD";
CM_ SG_ 408 RFC_Loc016_Phi "Location elevation angle. \"Not a number\" TBD";
CM_ SG_ 408 RFC_Loc016_DrVnce "Variance of Location radial distance";
CM_ SG_ 408 RFC_Loc016_VrVnce "Variance of Location radial relative velocity";
CM_ SG_ 408 RFC_Loc016_ThetaVnce "Variance of Location azimuth angle";
CM_ SG_ 408 RFC_Loc016_PhiVnce "Variance of Location elevation angle";
CM_ SG_ 408 RFC_Loc016_RCS "Radar Cross Section (RCS) estimation";
CM_ SG_ 408 RFC_Loc016_RSSI "Received Signal Strength Indication (RSSI)";
CM_ SG_ 408 RFC_Loc017_Dr "Location radial distance";
CM_ SG_ 408 RFC_Loc017_Vr "Location radial relative velocity";
CM_ SG_ 408 RFC_Loc017_Theta "Location azimuth angle. \"Not a number\" TBD";
CM_ SG_ 408 RFC_Loc017_Phi "Location elevation angle. \"Not a number\" TBD";
CM_ SG_ 408 RFC_Loc017_DrVnce "Variance of Location radial distance";
CM_ SG_ 408 RFC_Loc017_VrVnce "Variance of Location radial relative velocity";
CM_ SG_ 408 RFC_Loc017_ThetaVnce "Variance of Location azimuth angle";
CM_ SG_ 408 RFC_Loc017_PhiVnce "Variance of Location elevation angle";
CM_ SG_ 408 RFC_Loc017_RCS "Radar Cross Section (RCS) estimation";
CM_ SG_ 408 RFC_Loc017_RSSI "Received Signal Strength Indication (RSSI)";
CM_ SG_ 409 RFC_Loc018_CRC "CRC - Autosar E2E Profile 5, DataID = TBD";
CM_ SG_ 409 RFC_Loc018_AliveCtr "Alive counter - Autosar E2E Profile 5";
CM_ SG_ 409 RFC_Loc018_ProtBlockCtr "Protocol-Signal: Block-Counter";
CM_ SG_ 409 RFC_Loc018_Dr "Location radial distance";
CM_ SG_ 409 RFC_Loc018_Vr "Location radial relative velocity";
CM_ SG_ 409 RFC_Loc018_Theta "Location azimuth angle. \"Not a number\" TBD";
CM_ SG_ 409 RFC_Loc018_Phi "Location elevation angle. \"Not a number\" TBD";
CM_ SG_ 409 RFC_Loc018_DrVnce "Variance of Location radial distance";
CM_ SG_ 409 RFC_Loc018_VrVnce "Variance of Location radial relative velocity";
CM_ SG_ 409 RFC_Loc018_ThetaVnce "Variance of Location azimuth angle";
CM_ SG_ 409 RFC_Loc018_PhiVnce "Variance of Location elevation angle";
CM_ SG_ 409 RFC_Loc018_RCS "Radar Cross Section (RCS) estimation";
CM_ SG_ 409 RFC_Loc018_RSSI "Received Signal Strength Indication (RSSI)";
CM_ SG_ 409 RFC_Loc019_Dr "Location radial distance";
CM_ SG_ 409 RFC_Loc019_Vr "Location radial relative velocity";
CM_ SG_ 409 RFC_Loc019_Theta "Location azimuth angle. \"Not a number\" TBD";
CM_ SG_ 409 RFC_Loc019_Phi "Location elevation angle. \"Not a number\" TBD";
CM_ SG_ 409 RFC_Loc019_DrVnce "Variance of Location radial distance";
CM_ SG_ 409 RFC_Loc019_VrVnce "Variance of Location radial relative velocity";
CM_ SG_ 409 RFC_Loc019_ThetaVnce "Variance of Location azimuth angle";
CM_ SG_ 409 RFC_Loc019_PhiVnce "Variance of Location elevation angle";
CM_ SG_ 409 RFC_Loc019_RCS "Radar Cross Section (RCS) estimation";
CM_ SG_ 409 RFC_Loc019_RSSI "Received Signal Strength Indication (RSSI)";
CM_ SG_ 410 RFC_Loc020_CRC "CRC - Autosar E2E Profile 5, DataID = TBD";
CM_ SG_ 410 RFC_Loc020_AliveCtr "Alive counter - Autosar E2E Profile 5";
CM_ SG_ 410 RFC_Loc020_ProtBlockCtr "Protocol-Signal: Block-Counter";
CM_ SG_ 410 RFC_Loc020_Dr "Location radial distance";
CM_ SG_ 410 RFC_Loc020_Vr "Location radial relative velocity";
CM_ SG_ 410 RFC_Loc020_Theta "Location azimuth angle. \"Not a number\" TBD";
CM_ SG_ 410 RFC_Loc020_Phi "Location elevation angle. \"Not a number\" TBD";
CM_ SG_ 410 RFC_Loc020_DrVnce "Variance of Location radial distance";
CM_ SG_ 410 RFC_Loc020_VrVnce "Variance of Location radial relative velocity";
CM_ SG_ 410 RFC_Loc020_ThetaVnce "Variance of Location azimuth angle";
CM_ SG_ 410 RFC_Loc020_PhiVnce "Variance of Location elevation angle";
CM_ SG_ 410 RFC_Loc020_RCS "Radar Cross Section (RCS) estimation";
CM_ SG_ 410 RFC_Loc020_RSSI "Received Signal Strength Indication (RSSI)";
CM_ SG_ 410 RFC_Loc021_Dr "Location radial distance";
CM_ SG_ 410 RFC_Loc021_Vr "Location radial relative velocity";
CM_ SG_ 410 RFC_Loc021_Theta "Location azimuth angle. \"Not a number\" TBD";
CM_ SG_ 410 RFC_Loc021_Phi "Location elevation angle. \"Not a number\" TBD";
CM_ SG_ 410 RFC_Loc021_DrVnce "Variance of Location radial distance";
CM_ SG_ 410 RFC_Loc021_VrVnce "Variance of Location radial relative velocity";
CM_ SG_ 410 RFC_Loc021_ThetaVnce "Variance of Location azimuth angle";
CM_ SG_ 410 RFC_Loc021_PhiVnce "Variance of Location elevation angle";
CM_ SG_ 410 RFC_Loc021_RCS "Radar Cross Section (RCS) estimation";
CM_ SG_ 410 RFC_Loc021_RSSI "Received Signal Strength Indication (RSSI)";
CM_ SG_ 411 RFC_Loc022_CRC "CRC - Autosar E2E Profile 5, DataID = TBD";
CM_ SG_ 411 RFC_Loc022_AliveCtr "Alive counter - Autosar E2E Profile 5";
CM_ SG_ 411 RFC_Loc022_ProtBlockCtr "Protocol-Signal: Block-Counter";
CM_ SG_ 411 RFC_Loc022_Dr "Location radial distance";
CM_ SG_ 411 RFC_Loc022_Vr "Location radial relative velocity";
CM_ SG_ 411 RFC_Loc022_Theta "Location azimuth angle. \"Not a number\" TBD";
CM_ SG_ 411 RFC_Loc022_Phi "Location elevation angle. \"Not a number\" TBD";
CM_ SG_ 411 RFC_Loc022_DrVnce "Variance of Location radial distance";
CM_ SG_ 411 RFC_Loc022_VrVnce "Variance of Location radial relative velocity";
CM_ SG_ 411 RFC_Loc022_ThetaVnce "Variance of Location azimuth angle";
CM_ SG_ 411 RFC_Loc022_PhiVnce "Variance of Location elevation angle";
CM_ SG_ 411 RFC_Loc022_RCS "Radar Cross Section (RCS) estimation";
CM_ SG_ 411 RFC_Loc022_RSSI "Received Signal Strength Indication (RSSI)";
CM_ SG_ 411 RFC_Loc023_Dr "Location radial distance";
CM_ SG_ 411 RFC_Loc023_Vr "Location radial relative velocity";
CM_ SG_ 411 RFC_Loc023_Theta "Location azimuth angle. \"Not a number\" TBD";
CM_ SG_ 411 RFC_Loc023_Phi "Location elevation angle. \"Not a number\" TBD";
CM_ SG_ 411 RFC_Loc023_DrVnce "Variance of Location radial distance";
CM_ SG_ 411 RFC_Loc023_VrVnce "Variance of Location radial relative velocity";
CM_ SG_ 411 RFC_Loc023_ThetaVnce "Variance of Location azimuth angle";
CM_ SG_ 411 RFC_Loc023_PhiVnce "Variance of Location elevation angle";
CM_ SG_ 411 RFC_Loc023_RCS "Radar Cross Section (RCS) estimation";
CM_ SG_ 411 RFC_Loc023_RSSI "Received Signal Strength Indication (RSSI)";
CM_ SG_ 412 RFC_Loc024_CRC "CRC - Autosar E2E Profile 5, DataID = TBD";
CM_ SG_ 412 RFC_Loc024_AliveCtr "Alive counter - Autosar E2E Profile 5";
CM_ SG_ 412 RFC_Loc024_ProtBlockCtr "Protocol-Signal: Block-Counter";
CM_ SG_ 412 RFC_Loc024_Dr "Location radial distance";
CM_ SG_ 412 RFC_Loc024_Vr "Location radial relative velocity";
CM_ SG_ 412 RFC_Loc024_Theta "Location azimuth angle. \"Not a number\" TBD";
CM_ SG_ 412 RFC_Loc024_Phi "Location elevation angle. \"Not a number\" TBD";
CM_ SG_ 412 RFC_Loc024_DrVnce "Variance of Location radial distance";
CM_ SG_ 412 RFC_Loc024_VrVnce "Variance of Location radial relative velocity";
CM_ SG_ 412 RFC_Loc024_ThetaVnce "Variance of Location azimuth angle";
CM_ SG_ 412 RFC_Loc024_PhiVnce "Variance of Location elevation angle";
CM_ SG_ 412 RFC_Loc024_RCS "Radar Cross Section (RCS) estimation";
CM_ SG_ 412 RFC_Loc024_RSSI "Received Signal Strength Indication (RSSI)";
CM_ SG_ 412 RFC_Loc025_Dr "Location radial distance";
CM_ SG_ 412 RFC_Loc025_Vr "Location radial relative velocity";
CM_ SG_ 412 RFC_Loc025_Theta "Location azimuth angle. \"Not a number\" TBD";
CM_ SG_ 412 RFC_Loc025_Phi "Location elevation angle. \"Not a number\" TBD";
CM_ SG_ 412 RFC_Loc025_DrVnce "Variance of Location radial distance";
CM_ SG_ 412 RFC_Loc025_VrVnce "Variance of Location radial relative velocity";
CM_ SG_ 412 RFC_Loc025_ThetaVnce "Variance of Location azimuth angle";
CM_ SG_ 412 RFC_Loc025_PhiVnce "Variance of Location elevation angle";
CM_ SG_ 412 RFC_Loc025_RCS "Radar Cross Section (RCS) estimation";
CM_ SG_ 412 RFC_Loc025_RSSI "Received Signal Strength Indication (RSSI)";
CM_ SG_ 413 RFC_Loc026_CRC "CRC - Autosar E2E Profile 5, DataID = TBD";
CM_ SG_ 413 RFC_Loc026_AliveCtr "Alive counter - Autosar E2E Profile 5";
CM_ SG_ 413 RFC_Loc026_ProtBlockCtr "Protocol-Signal: Block-Counter";
CM_ SG_ 413 RFC_Loc026_Dr "Location radial distance";
CM_ SG_ 413 RFC_Loc026_Vr "Location radial relative velocity";
CM_ SG_ 413 RFC_Loc026_Theta "Location azimuth angle. \"Not a number\" TBD";
CM_ SG_ 413 RFC_Loc026_Phi "Location elevation angle. \"Not a number\" TBD";
CM_ SG_ 413 RFC_Loc026_DrVnce "Variance of Location radial distance";
CM_ SG_ 413 RFC_Loc026_VrVnce "Variance of Location radial relative velocity";
CM_ SG_ 413 RFC_Loc026_ThetaVnce "Variance of Location azimuth angle";
CM_ SG_ 413 RFC_Loc026_PhiVnce "Variance of Location elevation angle";
CM_ SG_ 413 RFC_Loc026_RCS "Radar Cross Section (RCS) estimation";
CM_ SG_ 413 RFC_Loc026_RSSI "Received Signal Strength Indication (RSSI)";
CM_ SG_ 413 RFC_Loc027_Dr "Location radial distance";
CM_ SG_ 413 RFC_Loc027_Vr "Location radial relative velocity";
CM_ SG_ 413 RFC_Loc027_Theta "Location azimuth angle. \"Not a number\" TBD";
CM_ SG_ 413 RFC_Loc027_Phi "Location elevation angle. \"Not a number\" TBD";
CM_ SG_ 413 RFC_Loc027_DrVnce "Variance of Location radial distance";
CM_ SG_ 413 RFC_Loc027_VrVnce "Variance of Location radial relative velocity";
CM_ SG_ 413 RFC_Loc027_ThetaVnce "Variance of Location azimuth angle";
CM_ SG_ 413 RFC_Loc027_PhiVnce "Variance of Location elevation angle";
CM_ SG_ 413 RFC_Loc027_RCS "Radar Cross Section (RCS) estimation";
CM_ SG_ 413 RFC_Loc027_RSSI "Received Signal Strength Indication (RSSI)";
CM_ SG_ 414 RFC_Loc028_CRC "CRC - Autosar E2E Profile 5, DataID = TBD";
CM_ SG_ 414 RFC_Loc028_AliveCtr "Alive counter - Autosar E2E Profile 5";
CM_ SG_ 414 RFC_Loc028_ProtBlockCtr "Protocol-Signal: Block-Counter";
CM_ SG_ 414 RFC_Loc028_Dr "Location radial distance";
CM_ SG_ 414 RFC_Loc028_Vr "Location radial relative velocity";
CM_ SG_ 414 RFC_Loc028_Theta "Location azimuth angle. \"Not a number\" TBD";
CM_ SG_ 414 RFC_Loc028_Phi "Location elevation angle. \"Not a number\" TBD";
CM_ SG_ 414 RFC_Loc028_DrVnce "Variance of Location radial distance";
CM_ SG_ 414 RFC_Loc028_VrVnce "Variance of Location radial relative velocity";
CM_ SG_ 414 RFC_Loc028_ThetaVnce "Variance of Location azimuth angle";
CM_ SG_ 414 RFC_Loc028_PhiVnce "Variance of Location elevation angle";
CM_ SG_ 414 RFC_Loc028_RCS "Radar Cross Section (RCS) estimation";
CM_ SG_ 414 RFC_Loc028_RSSI "Received Signal Strength Indication (RSSI)";
CM_ SG_ 414 RFC_Loc029_Dr "Location radial distance";
CM_ SG_ 414 RFC_Loc029_Vr "Location radial relative velocity";
CM_ SG_ 414 RFC_Loc029_Theta "Location azimuth angle. \"Not a number\" TBD";
CM_ SG_ 414 RFC_Loc029_Phi "Location elevation angle. \"Not a number\" TBD";
CM_ SG_ 414 RFC_Loc029_DrVnce "Variance of Location radial distance";
CM_ SG_ 414 RFC_Loc029_VrVnce "Variance of Location radial relative velocity";
CM_ SG_ 414 RFC_Loc029_ThetaVnce "Variance of Location azimuth angle";
CM_ SG_ 414 RFC_Loc029_PhiVnce "Variance of Location elevation angle";
CM_ SG_ 414 RFC_Loc029_RCS "Radar Cross Section (RCS) estimation";
CM_ SG_ 414 RFC_Loc029_RSSI "Received Signal Strength Indication (RSSI)";
CM_ SG_ 415 RFC_Loc030_CRC "CRC - Autosar E2E Profile 5, DataID = TBD";
CM_ SG_ 415 RFC_Loc030_AliveCtr "Alive counter - Autosar E2E Profile 5";
CM_ SG_ 415 RFC_Loc030_ProtBlockCtr "Protocol-Signal: Block-Counter";
CM_ SG_ 415 RFC_Loc030_Dr "Location radial distance";
CM_ SG_ 415 RFC_Loc030_Vr "Location radial relative velocity";
CM_ SG_ 415 RFC_Loc030_Theta "Location azimuth angle. \"Not a number\" TBD";
CM_ SG_ 415 RFC_Loc030_Phi "Location elevation angle. \"Not a number\" TBD";
CM_ SG_ 415 RFC_Loc030_DrVnce "Variance of Location radial distance";
CM_ SG_ 415 RFC_Loc030_VrVnce "Variance of Location radial relative velocity";
CM_ SG_ 415 RFC_Loc030_ThetaVnce "Variance of Location azimuth angle";
CM_ SG_ 415 RFC_Loc030_PhiVnce "Variance of Location elevation angle";
CM_ SG_ 415 RFC_Loc030_RCS "Radar Cross Section (RCS) estimation";
CM_ SG_ 415 RFC_Loc030_RSSI "Received Signal Strength Indication (RSSI)";
CM_ SG_ 415 RFC_Loc031_Dr "Location radial distance";
CM_ SG_ 415 RFC_Loc031_Vr "Location radial relative velocity";
CM_ SG_ 415 RFC_Loc031_Theta "Location azimuth angle. \"Not a number\" TBD";
CM_ SG_ 415 RFC_Loc031_Phi "Location elevation angle. \"Not a number\" TBD";
CM_ SG_ 415 RFC_Loc031_DrVnce "Variance of Location radial distance";
CM_ SG_ 415 RFC_Loc031_VrVnce "Variance of Location radial relative velocity";
CM_ SG_ 415 RFC_Loc031_ThetaVnce "Variance of Location azimuth angle";
CM_ SG_ 415 RFC_Loc031_PhiVnce "Variance of Location elevation angle";
CM_ SG_ 415 RFC_Loc031_RCS "Radar Cross Section (RCS) estimation";
CM_ SG_ 415 RFC_Loc031_RSSI "Received Signal Strength Indication (RSSI)";
CM_ SG_ 416 RFC_Loc032_CRC "CRC - Autosar E2E Profile 5, DataID = TBD";
CM_ SG_ 416 RFC_Loc032_AliveCtr "Alive counter - Autosar E2E Profile 5";
CM_ SG_ 416 RFC_Loc032_ProtBlockCtr "Protocol-Signal: Block-Counter";
CM_ SG_ 416 RFC_Loc032_Dr "Location radial distance";
CM_ SG_ 416 RFC_Loc032_Vr "Location radial relative velocity";
CM_ SG_ 416 RFC_Loc032_Theta "Location azimuth angle. \"Not a number\" TBD";
CM_ SG_ 416 RFC_Loc032_Phi "Location elevation angle. \"Not a number\" TBD";
CM_ SG_ 416 RFC_Loc032_DrVnce "Variance of Location radial distance";
CM_ SG_ 416 RFC_Loc032_VrVnce "Variance of Location radial relative velocity";
CM_ SG_ 416 RFC_Loc032_ThetaVnce "Variance of Location azimuth angle";
CM_ SG_ 416 RFC_Loc032_PhiVnce "Variance of Location elevation angle";
CM_ SG_ 416 RFC_Loc032_RCS "Radar Cross Section (RCS) estimation";
CM_ SG_ 416 RFC_Loc032_RSSI "Received Signal Strength Indication (RSSI)";
CM_ SG_ 416 RFC_Loc033_Dr "Location radial distance";
CM_ SG_ 416 RFC_Loc033_Vr "Location radial relative velocity";
CM_ SG_ 416 RFC_Loc033_Theta "Location azimuth angle. \"Not a number\" TBD";
CM_ SG_ 416 RFC_Loc033_Phi "Location elevation angle. \"Not a number\" TBD";
CM_ SG_ 416 RFC_Loc033_DrVnce "Variance of Location radial distance";
CM_ SG_ 416 RFC_Loc033_VrVnce "Variance of Location radial relative velocity";
CM_ SG_ 416 RFC_Loc033_ThetaVnce "Variance of Location azimuth angle";
CM_ SG_ 416 RFC_Loc033_PhiVnce "Variance of Location elevation angle";
CM_ SG_ 416 RFC_Loc033_RCS "Radar Cross Section (RCS) estimation";
CM_ SG_ 416 RFC_Loc033_RSSI "Received Signal Strength Indication (RSSI)";
CM_ SG_ 417 RFC_Loc034_CRC "CRC - Autosar E2E Profile 5, DataID = TBD";
CM_ SG_ 417 RFC_Loc034_AliveCtr "Alive counter - Autosar E2E Profile 5";
CM_ SG_ 417 RFC_Loc034_ProtBlockCtr "Protocol-Signal: Block-Counter";
CM_ SG_ 417 RFC_Loc034_Dr "Location radial distance";
CM_ SG_ 417 RFC_Loc034_Vr "Location radial relative velocity";
CM_ SG_ 417 RFC_Loc034_Theta "Location azimuth angle. \"Not a number\" TBD";
CM_ SG_ 417 RFC_Loc034_Phi "Location elevation angle. \"Not a number\" TBD";
CM_ SG_ 417 RFC_Loc034_DrVnce "Variance of Location radial distance";
CM_ SG_ 417 RFC_Loc034_VrVnce "Variance of Location radial relative velocity";
CM_ SG_ 417 RFC_Loc034_ThetaVnce "Variance of Location azimuth angle";
CM_ SG_ 417 RFC_Loc034_PhiVnce "Variance of Location elevation angle";
CM_ SG_ 417 RFC_Loc034_RCS "Radar Cross Section (RCS) estimation";
CM_ SG_ 417 RFC_Loc034_RSSI "Received Signal Strength Indication (RSSI)";
CM_ SG_ 417 RFC_Loc035_Dr "Location radial distance";
CM_ SG_ 417 RFC_Loc035_Vr "Location radial relative velocity";
CM_ SG_ 417 RFC_Loc035_Theta "Location azimuth angle. \"Not a number\" TBD";
CM_ SG_ 417 RFC_Loc035_Phi "Location elevation angle. \"Not a number\" TBD";
CM_ SG_ 417 RFC_Loc035_DrVnce "Variance of Location radial distance";
CM_ SG_ 417 RFC_Loc035_VrVnce "Variance of Location radial relative velocity";
CM_ SG_ 417 RFC_Loc035_ThetaVnce "Variance of Location azimuth angle";
CM_ SG_ 417 RFC_Loc035_PhiVnce "Variance of Location elevation angle";
CM_ SG_ 417 RFC_Loc035_RCS "Radar Cross Section (RCS) estimation";
CM_ SG_ 417 RFC_Loc035_RSSI "Received Signal Strength Indication (RSSI)";
CM_ SG_ 418 RFC_Loc036_CRC "CRC - Autosar E2E Profile 5, DataID = TBD";
CM_ SG_ 418 RFC_Loc036_AliveCtr "Alive counter - Autosar E2E Profile 5";
CM_ SG_ 418 RFC_Loc036_ProtBlockCtr "Protocol-Signal: Block-Counter";
CM_ SG_ 418 RFC_Loc036_Dr "Location radial distance";
CM_ SG_ 418 RFC_Loc036_Vr "Location radial relative velocity";
CM_ SG_ 418 RFC_Loc036_Theta "Location azimuth angle. \"Not a number\" TBD";
CM_ SG_ 418 RFC_Loc036_Phi "Location elevation angle. \"Not a number\" TBD";
CM_ SG_ 418 RFC_Loc036_DrVnce "Variance of Location radial distance";
CM_ SG_ 418 RFC_Loc036_VrVnce "Variance of Location radial relative velocity";
CM_ SG_ 418 RFC_Loc036_ThetaVnce "Variance of Location azimuth angle";
CM_ SG_ 418 RFC_Loc036_PhiVnce "Variance of Location elevation angle";
CM_ SG_ 418 RFC_Loc036_RCS "Radar Cross Section (RCS) estimation";
CM_ SG_ 418 RFC_Loc036_RSSI "Received Signal Strength Indication (RSSI)";
CM_ SG_ 418 RFC_Loc037_Dr "Location radial distance";
CM_ SG_ 418 RFC_Loc037_Vr "Location radial relative velocity";
CM_ SG_ 418 RFC_Loc037_Theta "Location azimuth angle. \"Not a number\" TBD";
CM_ SG_ 418 RFC_Loc037_Phi "Location elevation angle. \"Not a number\" TBD";
CM_ SG_ 418 RFC_Loc037_DrVnce "Variance of Location radial distance";
CM_ SG_ 418 RFC_Loc037_VrVnce "Variance of Location radial relative velocity";
CM_ SG_ 418 RFC_Loc037_ThetaVnce "Variance of Location azimuth angle";
CM_ SG_ 418 RFC_Loc037_PhiVnce "Variance of Location elevation angle";
CM_ SG_ 418 RFC_Loc037_RCS "Radar Cross Section (RCS) estimation";
CM_ SG_ 418 RFC_Loc037_RSSI "Received Signal Strength Indication (RSSI)";
CM_ SG_ 419 RFC_Loc038_CRC "CRC - Autosar E2E Profile 5, DataID = TBD";
CM_ SG_ 419 RFC_Loc038_AliveCtr "Alive counter - Autosar E2E Profile 5";
CM_ SG_ 419 RFC_Loc038_ProtBlockCtr "Protocol-Signal: Block-Counter";
CM_ SG_ 419 RFC_Loc038_Dr "Location radial distance";
CM_ SG_ 419 RFC_Loc038_Vr "Location radial relative velocity";
CM_ SG_ 419 RFC_Loc038_Theta "Location azimuth angle. \"Not a number\" TBD";
CM_ SG_ 419 RFC_Loc038_Phi "Location elevation angle. \"Not a number\" TBD";
CM_ SG_ 419 RFC_Loc038_DrVnce "Variance of Location radial distance";
CM_ SG_ 419 RFC_Loc038_VrVnce "Variance of Location radial relative velocity";
CM_ SG_ 419 RFC_Loc038_ThetaVnce "Variance of Location azimuth angle";
CM_ SG_ 419 RFC_Loc038_PhiVnce "Variance of Location elevation angle";
CM_ SG_ 419 RFC_Loc038_RCS "Radar Cross Section (RCS) estimation";
CM_ SG_ 419 RFC_Loc038_RSSI "Received Signal Strength Indication (RSSI)";
CM_ SG_ 419 RFC_Loc039_Dr "Location radial distance";
CM_ SG_ 419 RFC_Loc039_Vr "Location radial relative velocity";
CM_ SG_ 419 RFC_Loc039_Theta "Location azimuth angle. \"Not a number\" TBD";
CM_ SG_ 419 RFC_Loc039_Phi "Location elevation angle. \"Not a number\" TBD";
CM_ SG_ 419 RFC_Loc039_DrVnce "Variance of Location radial distance";
CM_ SG_ 419 RFC_Loc039_VrVnce "Variance of Location radial relative velocity";
CM_ SG_ 419 RFC_Loc039_ThetaVnce "Variance of Location azimuth angle";
CM_ SG_ 419 RFC_Loc039_PhiVnce "Variance of Location elevation angle";
CM_ SG_ 419 RFC_Loc039_RCS "Radar Cross Section (RCS) estimation";
CM_ SG_ 419 RFC_Loc039_RSSI "Received Signal Strength Indication (RSSI)";
CM_ SG_ 420 RFC_Loc040_CRC "CRC - Autosar E2E Profile 5, DataID = TBD";
CM_ SG_ 420 RFC_Loc040_AliveCtr "Alive counter - Autosar E2E Profile 5";
CM_ SG_ 420 RFC_Loc040_ProtBlockCtr "Protocol-Signal: Block-Counter";
CM_ SG_ 420 RFC_Loc040_Dr "Location radial distance";
CM_ SG_ 420 RFC_Loc040_Vr "Location radial relative velocity";
CM_ SG_ 420 RFC_Loc040_Theta "Location azimuth angle. \"Not a number\" TBD";
CM_ SG_ 420 RFC_Loc040_Phi "Location elevation angle. \"Not a number\" TBD";
CM_ SG_ 420 RFC_Loc040_DrVnce "Variance of Location radial distance";
CM_ SG_ 420 RFC_Loc040_VrVnce "Variance of Location radial relative velocity";
CM_ SG_ 420 RFC_Loc040_ThetaVnce "Variance of Location azimuth angle";
CM_ SG_ 420 RFC_Loc040_PhiVnce "Variance of Location elevation angle";
CM_ SG_ 420 RFC_Loc040_RCS "Radar Cross Section (RCS) estimation";
CM_ SG_ 420 RFC_Loc040_RSSI "Received Signal Strength Indication (RSSI)";
CM_ SG_ 420 RFC_Loc041_Dr "Location radial distance";
CM_ SG_ 420 RFC_Loc041_Vr "Location radial relative velocity";
CM_ SG_ 420 RFC_Loc041_Theta "Location azimuth angle. \"Not a number\" TBD";
CM_ SG_ 420 RFC_Loc041_Phi "Location elevation angle. \"Not a number\" TBD";
CM_ SG_ 420 RFC_Loc041_DrVnce "Variance of Location radial distance";
CM_ SG_ 420 RFC_Loc041_VrVnce "Variance of Location radial relative velocity";
CM_ SG_ 420 RFC_Loc041_ThetaVnce "Variance of Location azimuth angle";
CM_ SG_ 420 RFC_Loc041_PhiVnce "Variance of Location elevation angle";
CM_ SG_ 420 RFC_Loc041_RCS "Radar Cross Section (RCS) estimation";
CM_ SG_ 420 RFC_Loc041_RSSI "Received Signal Strength Indication (RSSI)";
CM_ SG_ 421 RFC_Loc042_CRC "CRC - Autosar E2E Profile 5, DataID = TBD";
CM_ SG_ 421 RFC_Loc042_AliveCtr "Alive counter - Autosar E2E Profile 5";
CM_ SG_ 421 RFC_Loc042_ProtBlockCtr "Protocol-Signal: Block-Counter";
CM_ SG_ 421 RFC_Loc042_Dr "Location radial distance";
CM_ SG_ 421 RFC_Loc042_Vr "Location radial relative velocity";
CM_ SG_ 421 RFC_Loc042_Theta "Location azimuth angle. \"Not a number\" TBD";
CM_ SG_ 421 RFC_Loc042_Phi "Location elevation angle. \"Not a number\" TBD";
CM_ SG_ 421 RFC_Loc042_DrVnce "Variance of Location radial distance";
CM_ SG_ 421 RFC_Loc042_VrVnce "Variance of Location radial relative velocity";
CM_ SG_ 421 RFC_Loc042_ThetaVnce "Variance of Location azimuth angle";
CM_ SG_ 421 RFC_Loc042_PhiVnce "Variance of Location elevation angle";
CM_ SG_ 421 RFC_Loc042_RCS "Radar Cross Section (RCS) estimation";
CM_ SG_ 421 RFC_Loc042_RSSI "Received Signal Strength Indication (RSSI)";
CM_ SG_ 421 RFC_Loc043_Dr "Location radial distance";
CM_ SG_ 421 RFC_Loc043_Vr "Location radial relative velocity";
CM_ SG_ 421 RFC_Loc043_Theta "Location azimuth angle. \"Not a number\" TBD";
CM_ SG_ 421 RFC_Loc043_Phi "Location elevation angle. \"Not a number\" TBD";
CM_ SG_ 421 RFC_Loc043_DrVnce "Variance of Location radial distance";
CM_ SG_ 421 RFC_Loc043_VrVnce "Variance of Location radial relative velocity";
CM_ SG_ 421 RFC_Loc043_ThetaVnce "Variance of Location azimuth angle";
CM_ SG_ 421 RFC_Loc043_PhiVnce "Variance of Location elevation angle";
CM_ SG_ 421 RFC_Loc043_RCS "Radar Cross Section (RCS) estimation";
CM_ SG_ 421 RFC_Loc043_RSSI "Received Signal Strength Indication (RSSI)";
CM_ SG_ 422 RFC_Loc044_CRC "CRC - Autosar E2E Profile 5, DataID = TBD";
CM_ SG_ 422 RFC_Loc044_AliveCtr "Alive counter - Autosar E2E Profile 5";
CM_ SG_ 422 RFC_Loc044_ProtBlockCtr "Protocol-Signal: Block-Counter";
CM_ SG_ 422 RFC_Loc044_Dr "Location radial distance";
CM_ SG_ 422 RFC_Loc044_Vr "Location radial relative velocity";
CM_ SG_ 422 RFC_Loc044_Theta "Location azimuth angle. \"Not a number\" TBD";
CM_ SG_ 422 RFC_Loc044_Phi "Location elevation angle. \"Not a number\" TBD";
CM_ SG_ 422 RFC_Loc044_DrVnce "Variance of Location radial distance";
CM_ SG_ 422 RFC_Loc044_VrVnce "Variance of Location radial relative velocity";
CM_ SG_ 422 RFC_Loc044_ThetaVnce "Variance of Location azimuth angle";
CM_ SG_ 422 RFC_Loc044_PhiVnce "Variance of Location elevation angle";
CM_ SG_ 422 RFC_Loc044_RCS "Radar Cross Section (RCS) estimation";
CM_ SG_ 422 RFC_Loc044_RSSI "Received Signal Strength Indication (RSSI)";
CM_ SG_ 422 RFC_Loc045_Dr "Location radial distance";
CM_ SG_ 422 RFC_Loc045_Vr "Location radial relative velocity";
CM_ SG_ 422 RFC_Loc045_Theta "Location azimuth angle. \"Not a number\" TBD";
CM_ SG_ 422 RFC_Loc045_Phi "Location elevation angle. \"Not a number\" TBD";
CM_ SG_ 422 RFC_Loc045_DrVnce "Variance of Location radial distance";
CM_ SG_ 422 RFC_Loc045_VrVnce "Variance of Location radial relative velocity";
CM_ SG_ 422 RFC_Loc045_ThetaVnce "Variance of Location azimuth angle";
CM_ SG_ 422 RFC_Loc045_PhiVnce "Variance of Location elevation angle";
CM_ SG_ 422 RFC_Loc045_RCS "Radar Cross Section (RCS) estimation";
CM_ SG_ 422 RFC_Loc045_RSSI "Received Signal Strength Indication (RSSI)";
CM_ SG_ 423 RFC_Loc046_CRC "CRC - Autosar E2E Profile 5, DataID = TBD";
CM_ SG_ 423 RFC_Loc046_AliveCtr "Alive counter - Autosar E2E Profile 5";
CM_ SG_ 423 RFC_Loc046_ProtBlockCtr "Protocol-Signal: Block-Counter";
CM_ SG_ 423 RFC_Loc046_Dr "Location radial distance";
CM_ SG_ 423 RFC_Loc046_Vr "Location radial relative velocity";
CM_ SG_ 423 RFC_Loc046_Theta "Location azimuth angle. \"Not a number\" TBD";
CM_ SG_ 423 RFC_Loc046_Phi "Location elevation angle. \"Not a number\" TBD";
CM_ SG_ 423 RFC_Loc046_DrVnce "Variance of Location radial distance";
CM_ SG_ 423 RFC_Loc046_VrVnce "Variance of Location radial relative velocity";
CM_ SG_ 423 RFC_Loc046_ThetaVnce "Variance of Location azimuth angle";
CM_ SG_ 423 RFC_Loc046_PhiVnce "Variance of Location elevation angle";
CM_ SG_ 423 RFC_Loc046_RCS "Radar Cross Section (RCS) estimation";
CM_ SG_ 423 RFC_Loc046_RSSI "Received Signal Strength Indication (RSSI)";
CM_ SG_ 423 RFC_Loc047_Dr "Location radial distance";
CM_ SG_ 423 RFC_Loc047_Vr "Location radial relative velocity";
CM_ SG_ 423 RFC_Loc047_Theta "Location azimuth angle. \"Not a number\" TBD";
CM_ SG_ 423 RFC_Loc047_Phi "Location elevation angle. \"Not a number\" TBD";
CM_ SG_ 423 RFC_Loc047_DrVnce "Variance of Location radial distance";
CM_ SG_ 423 RFC_Loc047_VrVnce "Variance of Location radial relative velocity";
CM_ SG_ 423 RFC_Loc047_ThetaVnce "Variance of Location azimuth angle";
CM_ SG_ 423 RFC_Loc047_PhiVnce "Variance of Location elevation angle";
CM_ SG_ 423 RFC_Loc047_RCS "Radar Cross Section (RCS) estimation";
CM_ SG_ 423 RFC_Loc047_RSSI "Received Signal Strength Indication (RSSI)";
CM_ SG_ 424 RFC_Loc048_CRC "CRC - Autosar E2E Profile 5, DataID = TBD";
CM_ SG_ 424 RFC_Loc048_AliveCtr "Alive counter - Autosar E2E Profile 5";
CM_ SG_ 424 RFC_Loc048_ProtBlockCtr "Protocol-Signal: Block-Counter";
CM_ SG_ 424 RFC_Loc048_Dr "Location radial distance";
CM_ SG_ 424 RFC_Loc048_Vr "Location radial relative velocity";
CM_ SG_ 424 RFC_Loc048_Theta "Location azimuth angle. \"Not a number\" TBD";
CM_ SG_ 424 RFC_Loc048_Phi "Location elevation angle. \"Not a number\" TBD";
CM_ SG_ 424 RFC_Loc048_DrVnce "Variance of Location radial distance";
CM_ SG_ 424 RFC_Loc048_VrVnce "Variance of Location radial relative velocity";
CM_ SG_ 424 RFC_Loc048_ThetaVnce "Variance of Location azimuth angle";
CM_ SG_ 424 RFC_Loc048_PhiVnce "Variance of Location elevation angle";
CM_ SG_ 424 RFC_Loc048_RCS "Radar Cross Section (RCS) estimation";
CM_ SG_ 424 RFC_Loc048_RSSI "Received Signal Strength Indication (RSSI)";
CM_ SG_ 424 RFC_Loc049_Dr "Location radial distance";
CM_ SG_ 424 RFC_Loc049_Vr "Location radial relative velocity";
CM_ SG_ 424 RFC_Loc049_Theta "Location azimuth angle. \"Not a number\" TBD";
CM_ SG_ 424 RFC_Loc049_Phi "Location elevation angle. \"Not a number\" TBD";
CM_ SG_ 424 RFC_Loc049_DrVnce "Variance of Location radial distance";
CM_ SG_ 424 RFC_Loc049_VrVnce "Variance of Location radial relative velocity";
CM_ SG_ 424 RFC_Loc049_ThetaVnce "Variance of Location azimuth angle";
CM_ SG_ 424 RFC_Loc049_PhiVnce "Variance of Location elevation angle";
CM_ SG_ 424 RFC_Loc049_RCS "Radar Cross Section (RCS) estimation";
CM_ SG_ 424 RFC_Loc049_RSSI "Received Signal Strength Indication (RSSI)";
CM_ SG_ 425 RFC_Loc050_CRC "CRC - Autosar E2E Profile 5, DataID = TBD";
CM_ SG_ 425 RFC_Loc050_AliveCtr "Alive counter - Autosar E2E Profile 5";
CM_ SG_ 425 RFC_Loc050_ProtBlockCtr "Protocol-Signal: Block-Counter";
CM_ SG_ 425 RFC_Loc050_Dr "Location radial distance";
CM_ SG_ 425 RFC_Loc050_Vr "Location radial relative velocity";
CM_ SG_ 425 RFC_Loc050_Theta "Location azimuth angle. \"Not a number\" TBD";
CM_ SG_ 425 RFC_Loc050_Phi "Location elevation angle. \"Not a number\" TBD";
CM_ SG_ 425 RFC_Loc050_DrVnce "Variance of Location radial distance";
CM_ SG_ 425 RFC_Loc050_VrVnce "Variance of Location radial relative velocity";
CM_ SG_ 425 RFC_Loc050_ThetaVnce "Variance of Location azimuth angle";
CM_ SG_ 425 RFC_Loc050_PhiVnce "Variance of Location elevation angle";
CM_ SG_ 425 RFC_Loc050_RCS "Radar Cross Section (RCS) estimation";
CM_ SG_ 425 RFC_Loc050_RSSI "Received Signal Strength Indication (RSSI)";
CM_ SG_ 425 RFC_Loc051_Dr "Location radial distance";
CM_ SG_ 425 RFC_Loc051_Vr "Location radial relative velocity";
CM_ SG_ 425 RFC_Loc051_Theta "Location azimuth angle. \"Not a number\" TBD";
CM_ SG_ 425 RFC_Loc051_Phi "Location elevation angle. \"Not a number\" TBD";
CM_ SG_ 425 RFC_Loc051_DrVnce "Variance of Location radial distance";
CM_ SG_ 425 RFC_Loc051_VrVnce "Variance of Location radial relative velocity";
CM_ SG_ 425 RFC_Loc051_ThetaVnce "Variance of Location azimuth angle";
CM_ SG_ 425 RFC_Loc051_PhiVnce "Variance of Location elevation angle";
CM_ SG_ 425 RFC_Loc051_RCS "Radar Cross Section (RCS) estimation";
CM_ SG_ 425 RFC_Loc051_RSSI "Received Signal Strength Indication (RSSI)";
CM_ SG_ 426 RFC_Loc052_CRC "CRC - Autosar E2E Profile 5, DataID = TBD";
CM_ SG_ 426 RFC_Loc052_AliveCtr "Alive counter - Autosar E2E Profile 5";
CM_ SG_ 426 RFC_Loc052_ProtBlockCtr "Protocol-Signal: Block-Counter";
CM_ SG_ 426 RFC_Loc052_Dr "Location radial distance";
CM_ SG_ 426 RFC_Loc052_Vr "Location radial relative velocity";
CM_ SG_ 426 RFC_Loc052_Theta "Location azimuth angle. \"Not a number\" TBD";
CM_ SG_ 426 RFC_Loc052_Phi "Location elevation angle. \"Not a number\" TBD";
CM_ SG_ 426 RFC_Loc052_DrVnce "Variance of Location radial distance";
CM_ SG_ 426 RFC_Loc052_VrVnce "Variance of Location radial relative velocity";
CM_ SG_ 426 RFC_Loc052_ThetaVnce "Variance of Location azimuth angle";
CM_ SG_ 426 RFC_Loc052_PhiVnce "Variance of Location elevation angle";
CM_ SG_ 426 RFC_Loc052_RCS "Radar Cross Section (RCS) estimation";
CM_ SG_ 426 RFC_Loc052_RSSI "Received Signal Strength Indication (RSSI)";
CM_ SG_ 426 RFC_Loc053_Dr "Location radial distance";
CM_ SG_ 426 RFC_Loc053_Vr "Location radial relative velocity";
CM_ SG_ 426 RFC_Loc053_Theta "Location azimuth angle. \"Not a number\" TBD";
CM_ SG_ 426 RFC_Loc053_Phi "Location elevation angle. \"Not a number\" TBD";
CM_ SG_ 426 RFC_Loc053_DrVnce "Variance of Location radial distance";
CM_ SG_ 426 RFC_Loc053_VrVnce "Variance of Location radial relative velocity";
CM_ SG_ 426 RFC_Loc053_ThetaVnce "Variance of Location azimuth angle";
CM_ SG_ 426 RFC_Loc053_PhiVnce "Variance of Location elevation angle";
CM_ SG_ 426 RFC_Loc053_RCS "Radar Cross Section (RCS) estimation";
CM_ SG_ 426 RFC_Loc053_RSSI "Received Signal Strength Indication (RSSI)";
CM_ SG_ 427 RFC_Loc054_CRC "CRC - Autosar E2E Profile 5, DataID = TBD";
CM_ SG_ 427 RFC_Loc054_AliveCtr "Alive counter - Autosar E2E Profile 5";
CM_ SG_ 427 RFC_Loc054_ProtBlockCtr "Protocol-Signal: Block-Counter";
CM_ SG_ 427 RFC_Loc054_Dr "Location radial distance";
CM_ SG_ 427 RFC_Loc054_Vr "Location radial relative velocity";
CM_ SG_ 427 RFC_Loc054_Theta "Location azimuth angle. \"Not a number\" TBD";
CM_ SG_ 427 RFC_Loc054_Phi "Location elevation angle. \"Not a number\" TBD";
CM_ SG_ 427 RFC_Loc054_DrVnce "Variance of Location radial distance";
CM_ SG_ 427 RFC_Loc054_VrVnce "Variance of Location radial relative velocity";
CM_ SG_ 427 RFC_Loc054_ThetaVnce "Variance of Location azimuth angle";
CM_ SG_ 427 RFC_Loc054_PhiVnce "Variance of Location elevation angle";
CM_ SG_ 427 RFC_Loc054_RCS "Radar Cross Section (RCS) estimation";
CM_ SG_ 427 RFC_Loc054_RSSI "Received Signal Strength Indication (RSSI)";
CM_ SG_ 427 RFC_Loc055_Dr "Location radial distance";
CM_ SG_ 427 RFC_Loc055_Vr "Location radial relative velocity";
CM_ SG_ 427 RFC_Loc055_Theta "Location azimuth angle. \"Not a number\" TBD";
CM_ SG_ 427 RFC_Loc055_Phi "Location elevation angle. \"Not a number\" TBD";
CM_ SG_ 427 RFC_Loc055_DrVnce "Variance of Location radial distance";
CM_ SG_ 427 RFC_Loc055_VrVnce "Variance of Location radial relative velocity";
CM_ SG_ 427 RFC_Loc055_ThetaVnce "Variance of Location azimuth angle";
CM_ SG_ 427 RFC_Loc055_PhiVnce "Variance of Location elevation angle";
CM_ SG_ 427 RFC_Loc055_RCS "Radar Cross Section (RCS) estimation";
CM_ SG_ 427 RFC_Loc055_RSSI "Received Signal Strength Indication (RSSI)";
BA_DEF_ BO_  "GenMsgSendType" ENUM  "cyclic","NoMsgSendType","IfActive","Event","CA","CE";
BA_DEF_ BO_  "GenMsgCycleTime" INT 0 0;
BA_DEF_ SG_  "GenSigSendType" ENUM  "cyclic","OnChange","OnWrite","IfActive","OnChangeWithRepetition","OnWriteWithRepetition","IfActiveWithRepetition","CA","CE","Event";
BA_DEF_ SG_  "GenSigStartValue" INT 0 0;
BA_DEF_  "DBName" STRING ;
BA_DEF_ BO_  "CANFD_BRS" ENUM  "0","1";
BA_DEF_ BO_  "VFrameFormat" ENUM  "StandardCAN","ExtendedCAN","reserved","reserved","reserved","reserved","reserved","reserved","reserved","reserved","reserved","reserved","reserved","reserved","StandardCAN_FD","ExtendedCAN_FD";
BA_DEF_  "BusBaudateData" INT 0 10000;
BA_DEF_  "BusBaudateOther" INT 0 10000;
BA_DEF_ BO_  "GenMsgILSupport" ENUM  "No","Yes";
BA_DEF_  "BusType" STRING ;
BA_DEF_DEF_  "GenMsgSendType" "cyclic";
BA_DEF_DEF_  "GenMsgCycleTime" 0;
BA_DEF_DEF_  "GenSigSendType" "cyclic";
BA_DEF_DEF_  "GenSigStartValue" 0;
BA_DEF_DEF_  "DBName" "";
BA_DEF_DEF_  "CANFD_BRS" "1";
BA_DEF_DEF_  "VFrameFormat" "";
BA_DEF_DEF_  "BusBaudateData" 2;
BA_DEF_DEF_  "BusBaudateOther" 500;
BA_DEF_DEF_  "GenMsgILSupport" "Yes";
BA_DEF_DEF_  "BusType" "CAN FD";
BA_ "DBName" "FR5CP_LGU";
BA_ "GenMsgCycleTime" BO_ 255 500;
BA_ "VFrameFormat" BO_ 255 14;
BA_ "GenMsgSendType" BO_ 384 3;
BA_ "VFrameFormat" BO_ 384 14;
BA_ "GenMsgSendType" BO_ 400 3;
BA_ "VFrameFormat" BO_ 400 14;
BA_ "GenMsgSendType" BO_ 401 3;
BA_ "VFrameFormat" BO_ 401 14;
BA_ "GenMsgSendType" BO_ 402 3;
BA_ "VFrameFormat" BO_ 402 14;
BA_ "GenMsgSendType" BO_ 403 3;
BA_ "VFrameFormat" BO_ 403 14;
BA_ "GenMsgSendType" BO_ 404 3;
BA_ "VFrameFormat" BO_ 404 14;
BA_ "GenMsgSendType" BO_ 405 3;
BA_ "VFrameFormat" BO_ 405 14;
BA_ "GenMsgSendType" BO_ 406 3;
BA_ "VFrameFormat" BO_ 406 14;
BA_ "GenMsgSendType" BO_ 407 3;
BA_ "VFrameFormat" BO_ 407 14;
BA_ "GenMsgSendType" BO_ 408 3;
BA_ "VFrameFormat" BO_ 408 14;
BA_ "GenMsgSendType" BO_ 409 3;
BA_ "VFrameFormat" BO_ 409 14;
BA_ "GenMsgSendType" BO_ 410 3;
BA_ "VFrameFormat" BO_ 410 14;
BA_ "GenMsgSendType" BO_ 411 3;
BA_ "VFrameFormat" BO_ 411 14;
BA_ "GenMsgSendType" BO_ 412 3;
BA_ "VFrameFormat" BO_ 412 14;
BA_ "GenMsgSendType" BO_ 413 3;
BA_ "VFrameFormat" BO_ 413 14;
BA_ "GenMsgSendType" BO_ 414 3;
BA_ "VFrameFormat" BO_ 414 14;
BA_ "GenMsgSendType" BO_ 415 3;
BA_ "VFrameFormat" BO_ 415 14;
BA_ "GenMsgSendType" BO_ 416 3;
BA_ "VFrameFormat" BO_ 416 14;
BA_ "GenMsgSendType" BO_ 417 3;
BA_ "VFrameFormat" BO_ 417 14;
BA_ "GenMsgSendType" BO_ 418 3;
BA_ "VFrameFormat" BO_ 418 14;
BA_ "GenMsgSendType" BO_ 419 3;
BA_ "VFrameFormat" BO_ 419 14;
BA_ "GenMsgSendType" BO_ 420 3;
BA_ "VFrameFormat" BO_ 420 14;
BA_ "GenMsgSendType" BO_ 421 3;
BA_ "VFrameFormat" BO_ 421 14;
BA_ "GenMsgSendType" BO_ 422 3;
BA_ "VFrameFormat" BO_ 422 14;
BA_ "GenMsgSendType" BO_ 423 3;
BA_ "VFrameFormat" BO_ 423 14;
BA_ "GenMsgSendType" BO_ 424 3;
BA_ "VFrameFormat" BO_ 424 14;
BA_ "GenMsgSendType" BO_ 425 3;
BA_ "VFrameFormat" BO_ 425 14;
BA_ "GenMsgSendType" BO_ 426 3;
BA_ "VFrameFormat" BO_ 426 14;
BA_ "GenMsgSendType" BO_ 427 3;
BA_ "VFrameFormat" BO_ 427 14;
BA_ "GenSigSendType" SG_ 384 RFC_Hdr00_CRC 9;
BA_ "GenSigSendType" SG_ 384 RFC_Hdr00_AliveCtr 9;
BA_ "GenSigSendType" SG_ 384 RFC_Hdr00_ProtBlockCtr 9;
BA_ "GenSigSendType" SG_ 384 RFC_Hdr00_ProtLocationCount 9;
BA_ "GenSigSendType" SG_ 384 RFC_Hdr00_SensorState 9;
BA_ "GenSigSendType" SG_ 384 RFC_Hdr00_TimeStamp 9;
BA_ "GenSigSendType" SG_ 384 RFC_Hdr00_TimeStampStatus 9;
BA_ "GenSigSendType" SG_ 400 RFC_Loc000_CRC 9;
BA_ "GenSigSendType" SG_ 400 RFC_Loc000_AliveCtr 9;
BA_ "GenSigSendType" SG_ 400 RFC_Loc000_ProtBlockCtr 9;
BA_ "GenSigSendType" SG_ 400 RFC_Loc000_Dr 9;
BA_ "GenSigSendType" SG_ 400 RFC_Loc000_Vr 9;
BA_ "GenSigStartValue" SG_ 400 RFC_Loc000_Vr 32768;
BA_ "GenSigSendType" SG_ 400 RFC_Loc000_Theta 9;
BA_ "GenSigStartValue" SG_ 400 RFC_Loc000_Theta 32768;
BA_ "GenSigSendType" SG_ 400 RFC_Loc000_Phi 9;
BA_ "GenSigStartValue" SG_ 400 RFC_Loc000_Phi 32768;
BA_ "GenSigSendType" SG_ 400 RFC_Loc000_DrVnce 9;
BA_ "GenSigSendType" SG_ 400 RFC_Loc000_VrVnce 9;
BA_ "GenSigSendType" SG_ 400 RFC_Loc000_ThetaVnce 9;
BA_ "GenSigSendType" SG_ 400 RFC_Loc000_PhiVnce 9;
BA_ "GenSigSendType" SG_ 400 RFC_Loc000_RCS 9;
BA_ "GenSigStartValue" SG_ 400 RFC_Loc000_RCS 32768;
BA_ "GenSigSendType" SG_ 400 RFC_Loc000_RSSI 9;
BA_ "GenSigSendType" SG_ 400 RFC_Loc001_Dr 9;
BA_ "GenSigSendType" SG_ 400 RFC_Loc001_Vr 9;
BA_ "GenSigStartValue" SG_ 400 RFC_Loc001_Vr 32768;
BA_ "GenSigSendType" SG_ 400 RFC_Loc001_Theta 9;
BA_ "GenSigStartValue" SG_ 400 RFC_Loc001_Theta 32768;
BA_ "GenSigSendType" SG_ 400 RFC_Loc001_Phi 9;
BA_ "GenSigStartValue" SG_ 400 RFC_Loc001_Phi 32768;
BA_ "GenSigSendType" SG_ 400 RFC_Loc001_DrVnce 9;
BA_ "GenSigSendType" SG_ 400 RFC_Loc001_VrVnce 9;
BA_ "GenSigSendType" SG_ 400 RFC_Loc001_ThetaVnce 9;
BA_ "GenSigSendType" SG_ 400 RFC_Loc001_PhiVnce 9;
BA_ "GenSigSendType" SG_ 400 RFC_Loc001_RCS 9;
BA_ "GenSigStartValue" SG_ 400 RFC_Loc001_RCS 32768;
BA_ "GenSigSendType" SG_ 400 RFC_Loc001_RSSI 9;
BA_ "GenSigSendType" SG_ 401 RFC_Loc002_CRC 9;
BA_ "GenSigSendType" SG_ 401 RFC_Loc002_AliveCtr 9;
BA_ "GenSigSendType" SG_ 401 RFC_Loc002_ProtBlockCtr 9;
BA_ "GenSigSendType" SG_ 401 RFC_Loc002_Dr 9;
BA_ "GenSigSendType" SG_ 401 RFC_Loc002_Vr 9;
BA_ "GenSigStartValue" SG_ 401 RFC_Loc002_Vr 32768;
BA_ "GenSigSendType" SG_ 401 RFC_Loc002_Theta 9;
BA_ "GenSigStartValue" SG_ 401 RFC_Loc002_Theta 32768;
BA_ "GenSigSendType" SG_ 401 RFC_Loc002_Phi 9;
BA_ "GenSigStartValue" SG_ 401 RFC_Loc002_Phi 32768;
BA_ "GenSigSendType" SG_ 401 RFC_Loc002_DrVnce 9;
BA_ "GenSigSendType" SG_ 401 RFC_Loc002_VrVnce 9;
BA_ "GenSigSendType" SG_ 401 RFC_Loc002_ThetaVnce 9;
BA_ "GenSigSendType" SG_ 401 RFC_Loc002_PhiVnce 9;
BA_ "GenSigSendType" SG_ 401 RFC_Loc002_RCS 9;
BA_ "GenSigStartValue" SG_ 401 RFC_Loc002_RCS 32768;
BA_ "GenSigSendType" SG_ 401 RFC_Loc002_RSSI 9;
BA_ "GenSigSendType" SG_ 401 RFC_Loc003_Dr 9;
BA_ "GenSigSendType" SG_ 401 RFC_Loc003_Vr 9;
BA_ "GenSigStartValue" SG_ 401 RFC_Loc003_Vr 32768;
BA_ "GenSigSendType" SG_ 401 RFC_Loc003_Theta 9;
BA_ "GenSigStartValue" SG_ 401 RFC_Loc003_Theta 32768;
BA_ "GenSigSendType" SG_ 401 RFC_Loc003_Phi 9;
BA_ "GenSigStartValue" SG_ 401 RFC_Loc003_Phi 32768;
BA_ "GenSigSendType" SG_ 401 RFC_Loc003_DrVnce 9;
BA_ "GenSigSendType" SG_ 401 RFC_Loc003_VrVnce 9;
BA_ "GenSigSendType" SG_ 401 RFC_Loc003_ThetaVnce 9;
BA_ "GenSigSendType" SG_ 401 RFC_Loc003_PhiVnce 9;
BA_ "GenSigSendType" SG_ 401 RFC_Loc003_RCS 9;
BA_ "GenSigStartValue" SG_ 401 RFC_Loc003_RCS 32768;
BA_ "GenSigSendType" SG_ 401 RFC_Loc003_RSSI 9;
BA_ "GenSigSendType" SG_ 402 RFC_Loc004_CRC 9;
BA_ "GenSigSendType" SG_ 402 RFC_Loc004_AliveCtr 9;
BA_ "GenSigSendType" SG_ 402 RFC_Loc004_ProtBlockCtr 9;
BA_ "GenSigSendType" SG_ 402 RFC_Loc004_Dr 9;
BA_ "GenSigSendType" SG_ 402 RFC_Loc004_Vr 9;
BA_ "GenSigStartValue" SG_ 402 RFC_Loc004_Vr 32768;
BA_ "GenSigSendType" SG_ 402 RFC_Loc004_Theta 9;
BA_ "GenSigStartValue" SG_ 402 RFC_Loc004_Theta 32768;
BA_ "GenSigSendType" SG_ 402 RFC_Loc004_Phi 9;
BA_ "GenSigStartValue" SG_ 402 RFC_Loc004_Phi 32768;
BA_ "GenSigSendType" SG_ 402 RFC_Loc004_DrVnce 9;
BA_ "GenSigSendType" SG_ 402 RFC_Loc004_VrVnce 9;
BA_ "GenSigSendType" SG_ 402 RFC_Loc004_ThetaVnce 9;
BA_ "GenSigSendType" SG_ 402 RFC_Loc004_PhiVnce 9;
BA_ "GenSigSendType" SG_ 402 RFC_Loc004_RCS 9;
BA_ "GenSigStartValue" SG_ 402 RFC_Loc004_RCS 32768;
BA_ "GenSigSendType" SG_ 402 RFC_Loc004_RSSI 9;
BA_ "GenSigSendType" SG_ 402 RFC_Loc005_Dr 9;
BA_ "GenSigSendType" SG_ 402 RFC_Loc005_Vr 9;
BA_ "GenSigStartValue" SG_ 402 RFC_Loc005_Vr 32768;
BA_ "GenSigSendType" SG_ 402 RFC_Loc005_Theta 9;
BA_ "GenSigStartValue" SG_ 402 RFC_Loc005_Theta 32768;
BA_ "GenSigSendType" SG_ 402 RFC_Loc005_Phi 9;
BA_ "GenSigStartValue" SG_ 402 RFC_Loc005_Phi 32768;
BA_ "GenSigSendType" SG_ 402 RFC_Loc005_DrVnce 9;
BA_ "GenSigSendType" SG_ 402 RFC_Loc005_VrVnce 9;
BA_ "GenSigSendType" SG_ 402 RFC_Loc005_ThetaVnce 9;
BA_ "GenSigSendType" SG_ 402 RFC_Loc005_PhiVnce 9;
BA_ "GenSigSendType" SG_ 402 RFC_Loc005_RCS 9;
BA_ "GenSigStartValue" SG_ 402 RFC_Loc005_RCS 32768;
BA_ "GenSigSendType" SG_ 402 RFC_Loc005_RSSI 9;
BA_ "GenSigSendType" SG_ 403 RFC_Loc006_CRC 9;
BA_ "GenSigSendType" SG_ 403 RFC_Loc006_AliveCtr 9;
BA_ "GenSigSendType" SG_ 403 RFC_Loc006_ProtBlockCtr 9;
BA_ "GenSigSendType" SG_ 403 RFC_Loc006_Dr 9;
BA_ "GenSigSendType" SG_ 403 RFC_Loc006_Vr 9;
BA_ "GenSigStartValue" SG_ 403 RFC_Loc006_Vr 32768;
BA_ "GenSigSendType" SG_ 403 RFC_Loc006_Theta 9;
BA_ "GenSigStartValue" SG_ 403 RFC_Loc006_Theta 32768;
BA_ "GenSigSendType" SG_ 403 RFC_Loc006_Phi 9;
BA_ "GenSigStartValue" SG_ 403 RFC_Loc006_Phi 32768;
BA_ "GenSigSendType" SG_ 403 RFC_Loc006_DrVnce 9;
BA_ "GenSigSendType" SG_ 403 RFC_Loc006_VrVnce 9;
BA_ "GenSigSendType" SG_ 403 RFC_Loc006_ThetaVnce 9;
BA_ "GenSigSendType" SG_ 403 RFC_Loc006_PhiVnce 9;
BA_ "GenSigSendType" SG_ 403 RFC_Loc006_RCS 9;
BA_ "GenSigStartValue" SG_ 403 RFC_Loc006_RCS 32768;
BA_ "GenSigSendType" SG_ 403 RFC_Loc006_RSSI 9;
BA_ "GenSigSendType" SG_ 403 RFC_Loc007_Dr 9;
BA_ "GenSigSendType" SG_ 403 RFC_Loc007_Vr 9;
BA_ "GenSigStartValue" SG_ 403 RFC_Loc007_Vr 32768;
BA_ "GenSigSendType" SG_ 403 RFC_Loc007_Theta 9;
BA_ "GenSigStartValue" SG_ 403 RFC_Loc007_Theta 32768;
BA_ "GenSigSendType" SG_ 403 RFC_Loc007_Phi 9;
BA_ "GenSigStartValue" SG_ 403 RFC_Loc007_Phi 32768;
BA_ "GenSigSendType" SG_ 403 RFC_Loc007_DrVnce 9;
BA_ "GenSigSendType" SG_ 403 RFC_Loc007_VrVnce 9;
BA_ "GenSigSendType" SG_ 403 RFC_Loc007_ThetaVnce 9;
BA_ "GenSigSendType" SG_ 403 RFC_Loc007_PhiVnce 9;
BA_ "GenSigSendType" SG_ 403 RFC_Loc007_RCS 9;
BA_ "GenSigStartValue" SG_ 403 RFC_Loc007_RCS 32768;
BA_ "GenSigSendType" SG_ 403 RFC_Loc007_RSSI 9;
BA_ "GenSigSendType" SG_ 404 RFC_Loc008_CRC 9;
BA_ "GenSigSendType" SG_ 404 RFC_Loc008_AliveCtr 9;
BA_ "GenSigSendType" SG_ 404 RFC_Loc008_ProtBlockCtr 9;
BA_ "GenSigSendType" SG_ 404 RFC_Loc008_Dr 9;
BA_ "GenSigSendType" SG_ 404 RFC_Loc008_Vr 9;
BA_ "GenSigStartValue" SG_ 404 RFC_Loc008_Vr 32768;
BA_ "GenSigSendType" SG_ 404 RFC_Loc008_Theta 9;
BA_ "GenSigStartValue" SG_ 404 RFC_Loc008_Theta 32768;
BA_ "GenSigSendType" SG_ 404 RFC_Loc008_Phi 9;
BA_ "GenSigStartValue" SG_ 404 RFC_Loc008_Phi 32768;
BA_ "GenSigSendType" SG_ 404 RFC_Loc008_DrVnce 9;
BA_ "GenSigSendType" SG_ 404 RFC_Loc008_VrVnce 9;
BA_ "GenSigSendType" SG_ 404 RFC_Loc008_ThetaVnce 9;
BA_ "GenSigSendType" SG_ 404 RFC_Loc008_PhiVnce 9;
BA_ "GenSigSendType" SG_ 404 RFC_Loc008_RCS 9;
BA_ "GenSigStartValue" SG_ 404 RFC_Loc008_RCS 32768;
BA_ "GenSigSendType" SG_ 404 RFC_Loc008_RSSI 9;
BA_ "GenSigSendType" SG_ 404 RFC_Loc009_Dr 9;
BA_ "GenSigSendType" SG_ 404 RFC_Loc009_Vr 9;
BA_ "GenSigStartValue" SG_ 404 RFC_Loc009_Vr 32768;
BA_ "GenSigSendType" SG_ 404 RFC_Loc009_Theta 9;
BA_ "GenSigStartValue" SG_ 404 RFC_Loc009_Theta 32768;
BA_ "GenSigSendType" SG_ 404 RFC_Loc009_Phi 9;
BA_ "GenSigStartValue" SG_ 404 RFC_Loc009_Phi 32768;
BA_ "GenSigSendType" SG_ 404 RFC_Loc009_DrVnce 9;
BA_ "GenSigSendType" SG_ 404 RFC_Loc009_VrVnce 9;
BA_ "GenSigSendType" SG_ 404 RFC_Loc009_ThetaVnce 9;
BA_ "GenSigSendType" SG_ 404 RFC_Loc009_PhiVnce 9;
BA_ "GenSigSendType" SG_ 404 RFC_Loc009_RCS 9;
BA_ "GenSigStartValue" SG_ 404 RFC_Loc009_RCS 32768;
BA_ "GenSigSendType" SG_ 404 RFC_Loc009_RSSI 9;
BA_ "GenSigSendType" SG_ 405 RFC_Loc010_CRC 9;
BA_ "GenSigSendType" SG_ 405 RFC_Loc010_AliveCtr 9;
BA_ "GenSigSendType" SG_ 405 RFC_Loc010_ProtBlockCtr 9;
BA_ "GenSigSendType" SG_ 405 RFC_Loc010_Dr 9;
BA_ "GenSigSendType" SG_ 405 RFC_Loc010_Vr 9;
BA_ "GenSigStartValue" SG_ 405 RFC_Loc010_Vr 32768;
BA_ "GenSigSendType" SG_ 405 RFC_Loc010_Theta 9;
BA_ "GenSigStartValue" SG_ 405 RFC_Loc010_Theta 32768;
BA_ "GenSigSendType" SG_ 405 RFC_Loc010_Phi 9;
BA_ "GenSigStartValue" SG_ 405 RFC_Loc010_Phi 32768;
BA_ "GenSigSendType" SG_ 405 RFC_Loc010_DrVnce 9;
BA_ "GenSigSendType" SG_ 405 RFC_Loc010_VrVnce 9;
BA_ "GenSigSendType" SG_ 405 RFC_Loc010_ThetaVnce 9;
BA_ "GenSigSendType" SG_ 405 RFC_Loc010_PhiVnce 9;
BA_ "GenSigSendType" SG_ 405 RFC_Loc010_RCS 9;
BA_ "GenSigStartValue" SG_ 405 RFC_Loc010_RCS 32768;
BA_ "GenSigSendType" SG_ 405 RFC_Loc010_RSSI 9;
BA_ "GenSigSendType" SG_ 405 RFC_Loc011_Dr 9;
BA_ "GenSigSendType" SG_ 405 RFC_Loc011_Vr 9;
BA_ "GenSigStartValue" SG_ 405 RFC_Loc011_Vr 32768;
BA_ "GenSigSendType" SG_ 405 RFC_Loc011_Theta 9;
BA_ "GenSigStartValue" SG_ 405 RFC_Loc011_Theta 32768;
BA_ "GenSigSendType" SG_ 405 RFC_Loc011_Phi 9;
BA_ "GenSigStartValue" SG_ 405 RFC_Loc011_Phi 32768;
BA_ "GenSigSendType" SG_ 405 RFC_Loc011_DrVnce 9;
BA_ "GenSigSendType" SG_ 405 RFC_Loc011_VrVnce 9;
BA_ "GenSigSendType" SG_ 405 RFC_Loc011_ThetaVnce 9;
BA_ "GenSigSendType" SG_ 405 RFC_Loc011_PhiVnce 9;
BA_ "GenSigSendType" SG_ 405 RFC_Loc011_RCS 9;
BA_ "GenSigStartValue" SG_ 405 RFC_Loc011_RCS 32768;
BA_ "GenSigSendType" SG_ 405 RFC_Loc011_RSSI 9;
BA_ "GenSigSendType" SG_ 406 RFC_Loc012_CRC 9;
BA_ "GenSigSendType" SG_ 406 RFC_Loc012_AliveCtr 9;
BA_ "GenSigSendType" SG_ 406 RFC_Loc012_ProtBlockCtr 9;
BA_ "GenSigSendType" SG_ 406 RFC_Loc012_Dr 9;
BA_ "GenSigSendType" SG_ 406 RFC_Loc012_Vr 9;
BA_ "GenSigStartValue" SG_ 406 RFC_Loc012_Vr 32768;
BA_ "GenSigSendType" SG_ 406 RFC_Loc012_Theta 9;
BA_ "GenSigStartValue" SG_ 406 RFC_Loc012_Theta 32768;
BA_ "GenSigSendType" SG_ 406 RFC_Loc012_Phi 9;
BA_ "GenSigStartValue" SG_ 406 RFC_Loc012_Phi 32768;
BA_ "GenSigSendType" SG_ 406 RFC_Loc012_DrVnce 9;
BA_ "GenSigSendType" SG_ 406 RFC_Loc012_VrVnce 9;
BA_ "GenSigSendType" SG_ 406 RFC_Loc012_ThetaVnce 9;
BA_ "GenSigSendType" SG_ 406 RFC_Loc012_PhiVnce 9;
BA_ "GenSigSendType" SG_ 406 RFC_Loc012_RCS 9;
BA_ "GenSigStartValue" SG_ 406 RFC_Loc012_RCS 32768;
BA_ "GenSigSendType" SG_ 406 RFC_Loc012_RSSI 9;
BA_ "GenSigSendType" SG_ 406 RFC_Loc013_Dr 9;
BA_ "GenSigSendType" SG_ 406 RFC_Loc013_Vr 9;
BA_ "GenSigStartValue" SG_ 406 RFC_Loc013_Vr 32768;
BA_ "GenSigSendType" SG_ 406 RFC_Loc013_Theta 9;
BA_ "GenSigStartValue" SG_ 406 RFC_Loc013_Theta 32768;
BA_ "GenSigSendType" SG_ 406 RFC_Loc013_Phi 9;
BA_ "GenSigStartValue" SG_ 406 RFC_Loc013_Phi 32768;
BA_ "GenSigSendType" SG_ 406 RFC_Loc013_DrVnce 9;
BA_ "GenSigSendType" SG_ 406 RFC_Loc013_VrVnce 9;
BA_ "GenSigSendType" SG_ 406 RFC_Loc013_ThetaVnce 9;
BA_ "GenSigSendType" SG_ 406 RFC_Loc013_PhiVnce 9;
BA_ "GenSigSendType" SG_ 406 RFC_Loc013_RCS 9;
BA_ "GenSigStartValue" SG_ 406 RFC_Loc013_RCS 32768;
BA_ "GenSigSendType" SG_ 406 RFC_Loc013_RSSI 9;
BA_ "GenSigSendType" SG_ 407 RFC_Loc014_CRC 9;
BA_ "GenSigSendType" SG_ 407 RFC_Loc014_AliveCtr 9;
BA_ "GenSigSendType" SG_ 407 RFC_Loc014_ProtBlockCtr 9;
BA_ "GenSigSendType" SG_ 407 RFC_Loc014_Dr 9;
BA_ "GenSigSendType" SG_ 407 RFC_Loc014_Vr 9;
BA_ "GenSigStartValue" SG_ 407 RFC_Loc014_Vr 32768;
BA_ "GenSigSendType" SG_ 407 RFC_Loc014_Theta 9;
BA_ "GenSigStartValue" SG_ 407 RFC_Loc014_Theta 32768;
BA_ "GenSigSendType" SG_ 407 RFC_Loc014_Phi 9;
BA_ "GenSigStartValue" SG_ 407 RFC_Loc014_Phi 32768;
BA_ "GenSigSendType" SG_ 407 RFC_Loc014_DrVnce 9;
BA_ "GenSigSendType" SG_ 407 RFC_Loc014_VrVnce 9;
BA_ "GenSigSendType" SG_ 407 RFC_Loc014_ThetaVnce 9;
BA_ "GenSigSendType" SG_ 407 RFC_Loc014_PhiVnce 9;
BA_ "GenSigSendType" SG_ 407 RFC_Loc014_RCS 9;
BA_ "GenSigStartValue" SG_ 407 RFC_Loc014_RCS 32768;
BA_ "GenSigSendType" SG_ 407 RFC_Loc014_RSSI 9;
BA_ "GenSigSendType" SG_ 407 RFC_Loc015_Dr 9;
BA_ "GenSigSendType" SG_ 407 RFC_Loc015_Vr 9;
BA_ "GenSigStartValue" SG_ 407 RFC_Loc015_Vr 32768;
BA_ "GenSigSendType" SG_ 407 RFC_Loc015_Theta 9;
BA_ "GenSigStartValue" SG_ 407 RFC_Loc015_Theta 32768;
BA_ "GenSigSendType" SG_ 407 RFC_Loc015_Phi 9;
BA_ "GenSigStartValue" SG_ 407 RFC_Loc015_Phi 32768;
BA_ "GenSigSendType" SG_ 407 RFC_Loc015_DrVnce 9;
BA_ "GenSigSendType" SG_ 407 RFC_Loc015_VrVnce 9;
BA_ "GenSigSendType" SG_ 407 RFC_Loc015_ThetaVnce 9;
BA_ "GenSigSendType" SG_ 407 RFC_Loc015_PhiVnce 9;
BA_ "GenSigSendType" SG_ 407 RFC_Loc015_RCS 9;
BA_ "GenSigStartValue" SG_ 407 RFC_Loc015_RCS 32768;
BA_ "GenSigSendType" SG_ 407 RFC_Loc015_RSSI 9;
BA_ "GenSigSendType" SG_ 408 RFC_Loc016_CRC 9;
BA_ "GenSigSendType" SG_ 408 RFC_Loc016_AliveCtr 9;
BA_ "GenSigSendType" SG_ 408 RFC_Loc016_ProtBlockCtr 9;
BA_ "GenSigSendType" SG_ 408 RFC_Loc016_Dr 9;
BA_ "GenSigSendType" SG_ 408 RFC_Loc016_Vr 9;
BA_ "GenSigStartValue" SG_ 408 RFC_Loc016_Vr 32768;
BA_ "GenSigSendType" SG_ 408 RFC_Loc016_Theta 9;
BA_ "GenSigStartValue" SG_ 408 RFC_Loc016_Theta 32768;
BA_ "GenSigSendType" SG_ 408 RFC_Loc016_Phi 9;
BA_ "GenSigStartValue" SG_ 408 RFC_Loc016_Phi 32768;
BA_ "GenSigSendType" SG_ 408 RFC_Loc016_DrVnce 9;
BA_ "GenSigSendType" SG_ 408 RFC_Loc016_VrVnce 9;
BA_ "GenSigSendType" SG_ 408 RFC_Loc016_ThetaVnce 9;
BA_ "GenSigSendType" SG_ 408 RFC_Loc016_PhiVnce 9;
BA_ "GenSigSendType" SG_ 408 RFC_Loc016_RCS 9;
BA_ "GenSigStartValue" SG_ 408 RFC_Loc016_RCS 32768;
BA_ "GenSigSendType" SG_ 408 RFC_Loc016_RSSI 9;
BA_ "GenSigSendType" SG_ 408 RFC_Loc017_Dr 9;
BA_ "GenSigSendType" SG_ 408 RFC_Loc017_Vr 9;
BA_ "GenSigStartValue" SG_ 408 RFC_Loc017_Vr 32768;
BA_ "GenSigSendType" SG_ 408 RFC_Loc017_Theta 9;
BA_ "GenSigStartValue" SG_ 408 RFC_Loc017_Theta 32768;
BA_ "GenSigSendType" SG_ 408 RFC_Loc017_Phi 9;
BA_ "GenSigStartValue" SG_ 408 RFC_Loc017_Phi 32768;
BA_ "GenSigSendType" SG_ 408 RFC_Loc017_DrVnce 9;
BA_ "GenSigSendType" SG_ 408 RFC_Loc017_VrVnce 9;
BA_ "GenSigSendType" SG_ 408 RFC_Loc017_ThetaVnce 9;
BA_ "GenSigSendType" SG_ 408 RFC_Loc017_PhiVnce 9;
BA_ "GenSigSendType" SG_ 408 RFC_Loc017_RCS 9;
BA_ "GenSigStartValue" SG_ 408 RFC_Loc017_RCS 32768;
BA_ "GenSigSendType" SG_ 408 RFC_Loc017_RSSI 9;
BA_ "GenSigSendType" SG_ 409 RFC_Loc018_CRC 9;
BA_ "GenSigSendType" SG_ 409 RFC_Loc018_AliveCtr 9;
BA_ "GenSigSendType" SG_ 409 RFC_Loc018_ProtBlockCtr 9;
BA_ "GenSigSendType" SG_ 409 RFC_Loc018_Dr 9;
BA_ "GenSigSendType" SG_ 409 RFC_Loc018_Vr 9;
BA_ "GenSigStartValue" SG_ 409 RFC_Loc018_Vr 32768;
BA_ "GenSigSendType" SG_ 409 RFC_Loc018_Theta 9;
BA_ "GenSigStartValue" SG_ 409 RFC_Loc018_Theta 32768;
BA_ "GenSigSendType" SG_ 409 RFC_Loc018_Phi 9;
BA_ "GenSigStartValue" SG_ 409 RFC_Loc018_Phi 32768;
BA_ "GenSigSendType" SG_ 409 RFC_Loc018_DrVnce 9;
BA_ "GenSigSendType" SG_ 409 RFC_Loc018_VrVnce 9;
BA_ "GenSigSendType" SG_ 409 RFC_Loc018_ThetaVnce 9;
BA_ "GenSigSendType" SG_ 409 RFC_Loc018_PhiVnce 9;
BA_ "GenSigSendType" SG_ 409 RFC_Loc018_RCS 9;
BA_ "GenSigStartValue" SG_ 409 RFC_Loc018_RCS 32768;
BA_ "GenSigSendType" SG_ 409 RFC_Loc018_RSSI 9;
BA_ "GenSigSendType" SG_ 409 RFC_Loc019_Dr 9;
BA_ "GenSigSendType" SG_ 409 RFC_Loc019_Vr 9;
BA_ "GenSigStartValue" SG_ 409 RFC_Loc019_Vr 32768;
BA_ "GenSigSendType" SG_ 409 RFC_Loc019_Theta 9;
BA_ "GenSigStartValue" SG_ 409 RFC_Loc019_Theta 32768;
BA_ "GenSigSendType" SG_ 409 RFC_Loc019_Phi 9;
BA_ "GenSigStartValue" SG_ 409 RFC_Loc019_Phi 32768;
BA_ "GenSigSendType" SG_ 409 RFC_Loc019_DrVnce 9;
BA_ "GenSigSendType" SG_ 409 RFC_Loc019_VrVnce 9;
BA_ "GenSigSendType" SG_ 409 RFC_Loc019_ThetaVnce 9;
BA_ "GenSigSendType" SG_ 409 RFC_Loc019_PhiVnce 9;
BA_ "GenSigSendType" SG_ 409 RFC_Loc019_RCS 9;
BA_ "GenSigStartValue" SG_ 409 RFC_Loc019_RCS 32768;
BA_ "GenSigSendType" SG_ 409 RFC_Loc019_RSSI 9;
BA_ "GenSigSendType" SG_ 410 RFC_Loc020_CRC 9;
BA_ "GenSigSendType" SG_ 410 RFC_Loc020_AliveCtr 9;
BA_ "GenSigSendType" SG_ 410 RFC_Loc020_ProtBlockCtr 9;
BA_ "GenSigSendType" SG_ 410 RFC_Loc020_Dr 9;
BA_ "GenSigSendType" SG_ 410 RFC_Loc020_Vr 9;
BA_ "GenSigStartValue" SG_ 410 RFC_Loc020_Vr 32768;
BA_ "GenSigSendType" SG_ 410 RFC_Loc020_Theta 9;
BA_ "GenSigStartValue" SG_ 410 RFC_Loc020_Theta 32768;
BA_ "GenSigSendType" SG_ 410 RFC_Loc020_Phi 9;
BA_ "GenSigStartValue" SG_ 410 RFC_Loc020_Phi 32768;
BA_ "GenSigSendType" SG_ 410 RFC_Loc020_DrVnce 9;
BA_ "GenSigSendType" SG_ 410 RFC_Loc020_VrVnce 9;
BA_ "GenSigSendType" SG_ 410 RFC_Loc020_ThetaVnce 9;
BA_ "GenSigSendType" SG_ 410 RFC_Loc020_PhiVnce 9;
BA_ "GenSigSendType" SG_ 410 RFC_Loc020_RCS 9;
BA_ "GenSigStartValue" SG_ 410 RFC_Loc020_RCS 32768;
BA_ "GenSigSendType" SG_ 410 RFC_Loc020_RSSI 9;
BA_ "GenSigSendType" SG_ 410 RFC_Loc021_Dr 9;
BA_ "GenSigSendType" SG_ 410 RFC_Loc021_Vr 9;
BA_ "GenSigStartValue" SG_ 410 RFC_Loc021_Vr 32768;
BA_ "GenSigSendType" SG_ 410 RFC_Loc021_Theta 9;
BA_ "GenSigStartValue" SG_ 410 RFC_Loc021_Theta 32768;
BA_ "GenSigSendType" SG_ 410 RFC_Loc021_Phi 9;
BA_ "GenSigStartValue" SG_ 410 RFC_Loc021_Phi 32768;
BA_ "GenSigSendType" SG_ 410 RFC_Loc021_DrVnce 9;
BA_ "GenSigSendType" SG_ 410 RFC_Loc021_VrVnce 9;
BA_ "GenSigSendType" SG_ 410 RFC_Loc021_ThetaVnce 9;
BA_ "GenSigSendType" SG_ 410 RFC_Loc021_PhiVnce 9;
BA_ "GenSigSendType" SG_ 410 RFC_Loc021_RCS 9;
BA_ "GenSigStartValue" SG_ 410 RFC_Loc021_RCS 32768;
BA_ "GenSigSendType" SG_ 410 RFC_Loc021_RSSI 9;
BA_ "GenSigSendType" SG_ 411 RFC_Loc022_CRC 9;
BA_ "GenSigSendType" SG_ 411 RFC_Loc022_AliveCtr 9;
BA_ "GenSigSendType" SG_ 411 RFC_Loc022_ProtBlockCtr 9;
BA_ "GenSigSendType" SG_ 411 RFC_Loc022_Dr 9;
BA_ "GenSigSendType" SG_ 411 RFC_Loc022_Vr 9;
BA_ "GenSigStartValue" SG_ 411 RFC_Loc022_Vr 32768;
BA_ "GenSigSendType" SG_ 411 RFC_Loc022_Theta 9;
BA_ "GenSigStartValue" SG_ 411 RFC_Loc022_Theta 32768;
BA_ "GenSigSendType" SG_ 411 RFC_Loc022_Phi 9;
BA_ "GenSigStartValue" SG_ 411 RFC_Loc022_Phi 32768;
BA_ "GenSigSendType" SG_ 411 RFC_Loc022_DrVnce 9;
BA_ "GenSigSendType" SG_ 411 RFC_Loc022_VrVnce 9;
BA_ "GenSigSendType" SG_ 411 RFC_Loc022_ThetaVnce 9;
BA_ "GenSigSendType" SG_ 411 RFC_Loc022_PhiVnce 9;
BA_ "GenSigSendType" SG_ 411 RFC_Loc022_RCS 9;
BA_ "GenSigStartValue" SG_ 411 RFC_Loc022_RCS 32768;
BA_ "GenSigSendType" SG_ 411 RFC_Loc022_RSSI 9;
BA_ "GenSigSendType" SG_ 411 RFC_Loc023_Dr 9;
BA_ "GenSigSendType" SG_ 411 RFC_Loc023_Vr 9;
BA_ "GenSigStartValue" SG_ 411 RFC_Loc023_Vr 32768;
BA_ "GenSigSendType" SG_ 411 RFC_Loc023_Theta 9;
BA_ "GenSigStartValue" SG_ 411 RFC_Loc023_Theta 32768;
BA_ "GenSigSendType" SG_ 411 RFC_Loc023_Phi 9;
BA_ "GenSigStartValue" SG_ 411 RFC_Loc023_Phi 32768;
BA_ "GenSigSendType" SG_ 411 RFC_Loc023_DrVnce 9;
BA_ "GenSigSendType" SG_ 411 RFC_Loc023_VrVnce 9;
BA_ "GenSigSendType" SG_ 411 RFC_Loc023_ThetaVnce 9;
BA_ "GenSigSendType" SG_ 411 RFC_Loc023_PhiVnce 9;
BA_ "GenSigSendType" SG_ 411 RFC_Loc023_RCS 9;
BA_ "GenSigStartValue" SG_ 411 RFC_Loc023_RCS 32768;
BA_ "GenSigSendType" SG_ 411 RFC_Loc023_RSSI 9;
BA_ "GenSigSendType" SG_ 412 RFC_Loc024_CRC 9;
BA_ "GenSigSendType" SG_ 412 RFC_Loc024_AliveCtr 9;
BA_ "GenSigSendType" SG_ 412 RFC_Loc024_ProtBlockCtr 9;
BA_ "GenSigSendType" SG_ 412 RFC_Loc024_Dr 9;
BA_ "GenSigSendType" SG_ 412 RFC_Loc024_Vr 9;
BA_ "GenSigStartValue" SG_ 412 RFC_Loc024_Vr 32768;
BA_ "GenSigSendType" SG_ 412 RFC_Loc024_Theta 9;
BA_ "GenSigStartValue" SG_ 412 RFC_Loc024_Theta 32768;
BA_ "GenSigSendType" SG_ 412 RFC_Loc024_Phi 9;
BA_ "GenSigStartValue" SG_ 412 RFC_Loc024_Phi 32768;
BA_ "GenSigSendType" SG_ 412 RFC_Loc024_DrVnce 9;
BA_ "GenSigSendType" SG_ 412 RFC_Loc024_VrVnce 9;
BA_ "GenSigSendType" SG_ 412 RFC_Loc024_ThetaVnce 9;
BA_ "GenSigSendType" SG_ 412 RFC_Loc024_PhiVnce 9;
BA_ "GenSigSendType" SG_ 412 RFC_Loc024_RCS 9;
BA_ "GenSigStartValue" SG_ 412 RFC_Loc024_RCS 32768;
BA_ "GenSigSendType" SG_ 412 RFC_Loc024_RSSI 9;
BA_ "GenSigSendType" SG_ 412 RFC_Loc025_Dr 9;
BA_ "GenSigSendType" SG_ 412 RFC_Loc025_Vr 9;
BA_ "GenSigStartValue" SG_ 412 RFC_Loc025_Vr 32768;
BA_ "GenSigSendType" SG_ 412 RFC_Loc025_Theta 9;
BA_ "GenSigStartValue" SG_ 412 RFC_Loc025_Theta 32768;
BA_ "GenSigSendType" SG_ 412 RFC_Loc025_Phi 9;
BA_ "GenSigStartValue" SG_ 412 RFC_Loc025_Phi 32768;
BA_ "GenSigSendType" SG_ 412 RFC_Loc025_DrVnce 9;
BA_ "GenSigSendType" SG_ 412 RFC_Loc025_VrVnce 9;
BA_ "GenSigSendType" SG_ 412 RFC_Loc025_ThetaVnce 9;
BA_ "GenSigSendType" SG_ 412 RFC_Loc025_PhiVnce 9;
BA_ "GenSigSendType" SG_ 412 RFC_Loc025_RCS 9;
BA_ "GenSigStartValue" SG_ 412 RFC_Loc025_RCS 32768;
BA_ "GenSigSendType" SG_ 412 RFC_Loc025_RSSI 9;
BA_ "GenSigSendType" SG_ 413 RFC_Loc026_CRC 9;
BA_ "GenSigSendType" SG_ 413 RFC_Loc026_AliveCtr 9;
BA_ "GenSigSendType" SG_ 413 RFC_Loc026_ProtBlockCtr 9;
BA_ "GenSigSendType" SG_ 413 RFC_Loc026_Dr 9;
BA_ "GenSigSendType" SG_ 413 RFC_Loc026_Vr 9;
BA_ "GenSigStartValue" SG_ 413 RFC_Loc026_Vr 32768;
BA_ "GenSigSendType" SG_ 413 RFC_Loc026_Theta 9;
BA_ "GenSigStartValue" SG_ 413 RFC_Loc026_Theta 32768;
BA_ "GenSigSendType" SG_ 413 RFC_Loc026_Phi 9;
BA_ "GenSigStartValue" SG_ 413 RFC_Loc026_Phi 32768;
BA_ "GenSigSendType" SG_ 413 RFC_Loc026_DrVnce 9;
BA_ "GenSigSendType" SG_ 413 RFC_Loc026_VrVnce 9;
BA_ "GenSigSendType" SG_ 413 RFC_Loc026_ThetaVnce 9;
BA_ "GenSigSendType" SG_ 413 RFC_Loc026_PhiVnce 9;
BA_ "GenSigSendType" SG_ 413 RFC_Loc026_RCS 9;
BA_ "GenSigStartValue" SG_ 413 RFC_Loc026_RCS 32768;
BA_ "GenSigSendType" SG_ 413 RFC_Loc026_RSSI 9;
BA_ "GenSigSendType" SG_ 413 RFC_Loc027_Dr 9;
BA_ "GenSigSendType" SG_ 413 RFC_Loc027_Vr 9;
BA_ "GenSigStartValue" SG_ 413 RFC_Loc027_Vr 32768;
BA_ "GenSigSendType" SG_ 413 RFC_Loc027_Theta 9;
BA_ "GenSigStartValue" SG_ 413 RFC_Loc027_Theta 32768;
BA_ "GenSigSendType" SG_ 413 RFC_Loc027_Phi 9;
BA_ "GenSigStartValue" SG_ 413 RFC_Loc027_Phi 32768;
BA_ "GenSigSendType" SG_ 413 RFC_Loc027_DrVnce 9;
BA_ "GenSigSendType" SG_ 413 RFC_Loc027_VrVnce 9;
BA_ "GenSigSendType" SG_ 413 RFC_Loc027_ThetaVnce 9;
BA_ "GenSigSendType" SG_ 413 RFC_Loc027_PhiVnce 9;
BA_ "GenSigSendType" SG_ 413 RFC_Loc027_RCS 9;
BA_ "GenSigStartValue" SG_ 413 RFC_Loc027_RCS 32768;
BA_ "GenSigSendType" SG_ 413 RFC_Loc027_RSSI 9;
BA_ "GenSigSendType" SG_ 414 RFC_Loc028_CRC 9;
BA_ "GenSigSendType" SG_ 414 RFC_Loc028_AliveCtr 9;
BA_ "GenSigSendType" SG_ 414 RFC_Loc028_ProtBlockCtr 9;
BA_ "GenSigSendType" SG_ 414 RFC_Loc028_Dr 9;
BA_ "GenSigSendType" SG_ 414 RFC_Loc028_Vr 9;
BA_ "GenSigStartValue" SG_ 414 RFC_Loc028_Vr 32768;
BA_ "GenSigSendType" SG_ 414 RFC_Loc028_Theta 9;
BA_ "GenSigStartValue" SG_ 414 RFC_Loc028_Theta 32768;
BA_ "GenSigSendType" SG_ 414 RFC_Loc028_Phi 9;
BA_ "GenSigStartValue" SG_ 414 RFC_Loc028_Phi 32768;
BA_ "GenSigSendType" SG_ 414 RFC_Loc028_DrVnce 9;
BA_ "GenSigSendType" SG_ 414 RFC_Loc028_VrVnce 9;
BA_ "GenSigSendType" SG_ 414 RFC_Loc028_ThetaVnce 9;
BA_ "GenSigSendType" SG_ 414 RFC_Loc028_PhiVnce 9;
BA_ "GenSigSendType" SG_ 414 RFC_Loc028_RCS 9;
BA_ "GenSigStartValue" SG_ 414 RFC_Loc028_RCS 32768;
BA_ "GenSigSendType" SG_ 414 RFC_Loc028_RSSI 9;
BA_ "GenSigSendType" SG_ 414 RFC_Loc029_Dr 9;
BA_ "GenSigSendType" SG_ 414 RFC_Loc029_Vr 9;
BA_ "GenSigStartValue" SG_ 414 RFC_Loc029_Vr 32768;
BA_ "GenSigSendType" SG_ 414 RFC_Loc029_Theta 9;
BA_ "GenSigStartValue" SG_ 414 RFC_Loc029_Theta 32768;
BA_ "GenSigSendType" SG_ 414 RFC_Loc029_Phi 9;
BA_ "GenSigStartValue" SG_ 414 RFC_Loc029_Phi 32768;
BA_ "GenSigSendType" SG_ 414 RFC_Loc029_DrVnce 9;
BA_ "GenSigSendType" SG_ 414 RFC_Loc029_VrVnce 9;
BA_ "GenSigSendType" SG_ 414 RFC_Loc029_ThetaVnce 9;
BA_ "GenSigSendType" SG_ 414 RFC_Loc029_PhiVnce 9;
BA_ "GenSigSendType" SG_ 414 RFC_Loc029_RCS 9;
BA_ "GenSigStartValue" SG_ 414 RFC_Loc029_RCS 32768;
BA_ "GenSigSendType" SG_ 414 RFC_Loc029_RSSI 9;
BA_ "GenSigSendType" SG_ 415 RFC_Loc030_CRC 9;
BA_ "GenSigSendType" SG_ 415 RFC_Loc030_AliveCtr 9;
BA_ "GenSigSendType" SG_ 415 RFC_Loc030_ProtBlockCtr 9;
BA_ "GenSigSendType" SG_ 415 RFC_Loc030_Dr 9;
BA_ "GenSigSendType" SG_ 415 RFC_Loc030_Vr 9;
BA_ "GenSigStartValue" SG_ 415 RFC_Loc030_Vr 32768;
BA_ "GenSigSendType" SG_ 415 RFC_Loc030_Theta 9;
BA_ "GenSigStartValue" SG_ 415 RFC_Loc030_Theta 32768;
BA_ "GenSigSendType" SG_ 415 RFC_Loc030_Phi 9;
BA_ "GenSigStartValue" SG_ 415 RFC_Loc030_Phi 32768;
BA_ "GenSigSendType" SG_ 415 RFC_Loc030_DrVnce 9;
BA_ "GenSigSendType" SG_ 415 RFC_Loc030_VrVnce 9;
BA_ "GenSigSendType" SG_ 415 RFC_Loc030_ThetaVnce 9;
BA_ "GenSigSendType" SG_ 415 RFC_Loc030_PhiVnce 9;
BA_ "GenSigSendType" SG_ 415 RFC_Loc030_RCS 9;
BA_ "GenSigStartValue" SG_ 415 RFC_Loc030_RCS 32768;
BA_ "GenSigSendType" SG_ 415 RFC_Loc030_RSSI 9;
BA_ "GenSigSendType" SG_ 415 RFC_Loc031_Dr 9;
BA_ "GenSigSendType" SG_ 415 RFC_Loc031_Vr 9;
BA_ "GenSigStartValue" SG_ 415 RFC_Loc031_Vr 32768;
BA_ "GenSigSendType" SG_ 415 RFC_Loc031_Theta 9;
BA_ "GenSigStartValue" SG_ 415 RFC_Loc031_Theta 32768;
BA_ "GenSigSendType" SG_ 415 RFC_Loc031_Phi 9;
BA_ "GenSigStartValue" SG_ 415 RFC_Loc031_Phi 32768;
BA_ "GenSigSendType" SG_ 415 RFC_Loc031_DrVnce 9;
BA_ "GenSigSendType" SG_ 415 RFC_Loc031_VrVnce 9;
BA_ "GenSigSendType" SG_ 415 RFC_Loc031_ThetaVnce 9;
BA_ "GenSigSendType" SG_ 415 RFC_Loc031_PhiVnce 9;
BA_ "GenSigSendType" SG_ 415 RFC_Loc031_RCS 9;
BA_ "GenSigStartValue" SG_ 415 RFC_Loc031_RCS 32768;
BA_ "GenSigSendType" SG_ 415 RFC_Loc031_RSSI 9;
BA_ "GenSigSendType" SG_ 416 RFC_Loc032_CRC 9;
BA_ "GenSigSendType" SG_ 416 RFC_Loc032_AliveCtr 9;
BA_ "GenSigSendType" SG_ 416 RFC_Loc032_ProtBlockCtr 9;
BA_ "GenSigSendType" SG_ 416 RFC_Loc032_Dr 9;
BA_ "GenSigSendType" SG_ 416 RFC_Loc032_Vr 9;
BA_ "GenSigStartValue" SG_ 416 RFC_Loc032_Vr 32768;
BA_ "GenSigSendType" SG_ 416 RFC_Loc032_Theta 9;
BA_ "GenSigStartValue" SG_ 416 RFC_Loc032_Theta 32768;
BA_ "GenSigSendType" SG_ 416 RFC_Loc032_Phi 9;
BA_ "GenSigStartValue" SG_ 416 RFC_Loc032_Phi 32768;
BA_ "GenSigSendType" SG_ 416 RFC_Loc032_DrVnce 9;
BA_ "GenSigSendType" SG_ 416 RFC_Loc032_VrVnce 9;
BA_ "GenSigSendType" SG_ 416 RFC_Loc032_ThetaVnce 9;
BA_ "GenSigSendType" SG_ 416 RFC_Loc032_PhiVnce 9;
BA_ "GenSigSendType" SG_ 416 RFC_Loc032_RCS 9;
BA_ "GenSigStartValue" SG_ 416 RFC_Loc032_RCS 32768;
BA_ "GenSigSendType" SG_ 416 RFC_Loc032_RSSI 9;
BA_ "GenSigSendType" SG_ 416 RFC_Loc033_Dr 9;
BA_ "GenSigSendType" SG_ 416 RFC_Loc033_Vr 9;
BA_ "GenSigStartValue" SG_ 416 RFC_Loc033_Vr 32768;
BA_ "GenSigSendType" SG_ 416 RFC_Loc033_Theta 9;
BA_ "GenSigStartValue" SG_ 416 RFC_Loc033_Theta 32768;
BA_ "GenSigSendType" SG_ 416 RFC_Loc033_Phi 9;
BA_ "GenSigStartValue" SG_ 416 RFC_Loc033_Phi 32768;
BA_ "GenSigSendType" SG_ 416 RFC_Loc033_DrVnce 9;
BA_ "GenSigSendType" SG_ 416 RFC_Loc033_VrVnce 9;
BA_ "GenSigSendType" SG_ 416 RFC_Loc033_ThetaVnce 9;
BA_ "GenSigSendType" SG_ 416 RFC_Loc033_PhiVnce 9;
BA_ "GenSigSendType" SG_ 416 RFC_Loc033_RCS 9;
BA_ "GenSigStartValue" SG_ 416 RFC_Loc033_RCS 32768;
BA_ "GenSigSendType" SG_ 416 RFC_Loc033_RSSI 9;
BA_ "GenSigSendType" SG_ 417 RFC_Loc034_CRC 9;
BA_ "GenSigSendType" SG_ 417 RFC_Loc034_AliveCtr 9;
BA_ "GenSigSendType" SG_ 417 RFC_Loc034_ProtBlockCtr 9;
BA_ "GenSigSendType" SG_ 417 RFC_Loc034_Dr 9;
BA_ "GenSigSendType" SG_ 417 RFC_Loc034_Vr 9;
BA_ "GenSigStartValue" SG_ 417 RFC_Loc034_Vr 32768;
BA_ "GenSigSendType" SG_ 417 RFC_Loc034_Theta 9;
BA_ "GenSigStartValue" SG_ 417 RFC_Loc034_Theta 32768;
BA_ "GenSigSendType" SG_ 417 RFC_Loc034_Phi 9;
BA_ "GenSigStartValue" SG_ 417 RFC_Loc034_Phi 32768;
BA_ "GenSigSendType" SG_ 417 RFC_Loc034_DrVnce 9;
BA_ "GenSigSendType" SG_ 417 RFC_Loc034_VrVnce 9;
BA_ "GenSigSendType" SG_ 417 RFC_Loc034_ThetaVnce 9;
BA_ "GenSigSendType" SG_ 417 RFC_Loc034_PhiVnce 9;
BA_ "GenSigSendType" SG_ 417 RFC_Loc034_RCS 9;
BA_ "GenSigStartValue" SG_ 417 RFC_Loc034_RCS 32768;
BA_ "GenSigSendType" SG_ 417 RFC_Loc034_RSSI 9;
BA_ "GenSigSendType" SG_ 417 RFC_Loc035_Dr 9;
BA_ "GenSigSendType" SG_ 417 RFC_Loc035_Vr 9;
BA_ "GenSigStartValue" SG_ 417 RFC_Loc035_Vr 32768;
BA_ "GenSigSendType" SG_ 417 RFC_Loc035_Theta 9;
BA_ "GenSigStartValue" SG_ 417 RFC_Loc035_Theta 32768;
BA_ "GenSigSendType" SG_ 417 RFC_Loc035_Phi 9;
BA_ "GenSigStartValue" SG_ 417 RFC_Loc035_Phi 32768;
BA_ "GenSigSendType" SG_ 417 RFC_Loc035_DrVnce 9;
BA_ "GenSigSendType" SG_ 417 RFC_Loc035_VrVnce 9;
BA_ "GenSigSendType" SG_ 417 RFC_Loc035_ThetaVnce 9;
BA_ "GenSigSendType" SG_ 417 RFC_Loc035_PhiVnce 9;
BA_ "GenSigSendType" SG_ 417 RFC_Loc035_RCS 9;
BA_ "GenSigStartValue" SG_ 417 RFC_Loc035_RCS 32768;
BA_ "GenSigSendType" SG_ 417 RFC_Loc035_RSSI 9;
BA_ "GenSigSendType" SG_ 418 RFC_Loc036_CRC 9;
BA_ "GenSigSendType" SG_ 418 RFC_Loc036_AliveCtr 9;
BA_ "GenSigSendType" SG_ 418 RFC_Loc036_ProtBlockCtr 9;
BA_ "GenSigSendType" SG_ 418 RFC_Loc036_Dr 9;
BA_ "GenSigSendType" SG_ 418 RFC_Loc036_Vr 9;
BA_ "GenSigStartValue" SG_ 418 RFC_Loc036_Vr 32768;
BA_ "GenSigSendType" SG_ 418 RFC_Loc036_Theta 9;
BA_ "GenSigStartValue" SG_ 418 RFC_Loc036_Theta 32768;
BA_ "GenSigSendType" SG_ 418 RFC_Loc036_Phi 9;
BA_ "GenSigStartValue" SG_ 418 RFC_Loc036_Phi 32768;
BA_ "GenSigSendType" SG_ 418 RFC_Loc036_DrVnce 9;
BA_ "GenSigSendType" SG_ 418 RFC_Loc036_VrVnce 9;
BA_ "GenSigSendType" SG_ 418 RFC_Loc036_ThetaVnce 9;
BA_ "GenSigSendType" SG_ 418 RFC_Loc036_PhiVnce 9;
BA_ "GenSigSendType" SG_ 418 RFC_Loc036_RCS 9;
BA_ "GenSigStartValue" SG_ 418 RFC_Loc036_RCS 32768;
BA_ "GenSigSendType" SG_ 418 RFC_Loc036_RSSI 9;
BA_ "GenSigSendType" SG_ 418 RFC_Loc037_Dr 9;
BA_ "GenSigSendType" SG_ 418 RFC_Loc037_Vr 9;
BA_ "GenSigStartValue" SG_ 418 RFC_Loc037_Vr 32768;
BA_ "GenSigSendType" SG_ 418 RFC_Loc037_Theta 9;
BA_ "GenSigStartValue" SG_ 418 RFC_Loc037_Theta 32768;
BA_ "GenSigSendType" SG_ 418 RFC_Loc037_Phi 9;
BA_ "GenSigStartValue" SG_ 418 RFC_Loc037_Phi 32768;
BA_ "GenSigSendType" SG_ 418 RFC_Loc037_DrVnce 9;
BA_ "GenSigSendType" SG_ 418 RFC_Loc037_VrVnce 9;
BA_ "GenSigSendType" SG_ 418 RFC_Loc037_ThetaVnce 9;
BA_ "GenSigSendType" SG_ 418 RFC_Loc037_PhiVnce 9;
BA_ "GenSigSendType" SG_ 418 RFC_Loc037_RCS 9;
BA_ "GenSigStartValue" SG_ 418 RFC_Loc037_RCS 32768;
BA_ "GenSigSendType" SG_ 418 RFC_Loc037_RSSI 9;
BA_ "GenSigSendType" SG_ 419 RFC_Loc038_CRC 9;
BA_ "GenSigSendType" SG_ 419 RFC_Loc038_AliveCtr 9;
BA_ "GenSigSendType" SG_ 419 RFC_Loc038_ProtBlockCtr 9;
BA_ "GenSigSendType" SG_ 419 RFC_Loc038_Dr 9;
BA_ "GenSigSendType" SG_ 419 RFC_Loc038_Vr 9;
BA_ "GenSigStartValue" SG_ 419 RFC_Loc038_Vr 32768;
BA_ "GenSigSendType" SG_ 419 RFC_Loc038_Theta 9;
BA_ "GenSigStartValue" SG_ 419 RFC_Loc038_Theta 32768;
BA_ "GenSigSendType" SG_ 419 RFC_Loc038_Phi 9;
BA_ "GenSigStartValue" SG_ 419 RFC_Loc038_Phi 32768;
BA_ "GenSigSendType" SG_ 419 RFC_Loc038_DrVnce 9;
BA_ "GenSigSendType" SG_ 419 RFC_Loc038_VrVnce 9;
BA_ "GenSigSendType" SG_ 419 RFC_Loc038_ThetaVnce 9;
BA_ "GenSigSendType" SG_ 419 RFC_Loc038_PhiVnce 9;
BA_ "GenSigSendType" SG_ 419 RFC_Loc038_RCS 9;
BA_ "GenSigStartValue" SG_ 419 RFC_Loc038_RCS 32768;
BA_ "GenSigSendType" SG_ 419 RFC_Loc038_RSSI 9;
BA_ "GenSigSendType" SG_ 419 RFC_Loc039_Dr 9;
BA_ "GenSigSendType" SG_ 419 RFC_Loc039_Vr 9;
BA_ "GenSigStartValue" SG_ 419 RFC_Loc039_Vr 32768;
BA_ "GenSigSendType" SG_ 419 RFC_Loc039_Theta 9;
BA_ "GenSigStartValue" SG_ 419 RFC_Loc039_Theta 32768;
BA_ "GenSigSendType" SG_ 419 RFC_Loc039_Phi 9;
BA_ "GenSigStartValue" SG_ 419 RFC_Loc039_Phi 32768;
BA_ "GenSigSendType" SG_ 419 RFC_Loc039_DrVnce 9;
BA_ "GenSigSendType" SG_ 419 RFC_Loc039_VrVnce 9;
BA_ "GenSigSendType" SG_ 419 RFC_Loc039_ThetaVnce 9;
BA_ "GenSigSendType" SG_ 419 RFC_Loc039_PhiVnce 9;
BA_ "GenSigSendType" SG_ 419 RFC_Loc039_RCS 9;
BA_ "GenSigStartValue" SG_ 419 RFC_Loc039_RCS 32768;
BA_ "GenSigSendType" SG_ 419 RFC_Loc039_RSSI 9;
BA_ "GenSigSendType" SG_ 420 RFC_Loc040_CRC 9;
BA_ "GenSigSendType" SG_ 420 RFC_Loc040_AliveCtr 9;
BA_ "GenSigSendType" SG_ 420 RFC_Loc040_ProtBlockCtr 9;
BA_ "GenSigSendType" SG_ 420 RFC_Loc040_Dr 9;
BA_ "GenSigSendType" SG_ 420 RFC_Loc040_Vr 9;
BA_ "GenSigStartValue" SG_ 420 RFC_Loc040_Vr 32768;
BA_ "GenSigSendType" SG_ 420 RFC_Loc040_Theta 9;
BA_ "GenSigStartValue" SG_ 420 RFC_Loc040_Theta 32768;
BA_ "GenSigSendType" SG_ 420 RFC_Loc040_Phi 9;
BA_ "GenSigStartValue" SG_ 420 RFC_Loc040_Phi 32768;
BA_ "GenSigSendType" SG_ 420 RFC_Loc040_DrVnce 9;
BA_ "GenSigSendType" SG_ 420 RFC_Loc040_VrVnce 9;
BA_ "GenSigSendType" SG_ 420 RFC_Loc040_ThetaVnce 9;
BA_ "GenSigSendType" SG_ 420 RFC_Loc040_PhiVnce 9;
BA_ "GenSigSendType" SG_ 420 RFC_Loc040_RCS 9;
BA_ "GenSigStartValue" SG_ 420 RFC_Loc040_RCS 32768;
BA_ "GenSigSendType" SG_ 420 RFC_Loc040_RSSI 9;
BA_ "GenSigSendType" SG_ 420 RFC_Loc041_Dr 9;
BA_ "GenSigSendType" SG_ 420 RFC_Loc041_Vr 9;
BA_ "GenSigStartValue" SG_ 420 RFC_Loc041_Vr 32768;
BA_ "GenSigSendType" SG_ 420 RFC_Loc041_Theta 9;
BA_ "GenSigStartValue" SG_ 420 RFC_Loc041_Theta 32768;
BA_ "GenSigSendType" SG_ 420 RFC_Loc041_Phi 9;
BA_ "GenSigStartValue" SG_ 420 RFC_Loc041_Phi 32768;
BA_ "GenSigSendType" SG_ 420 RFC_Loc041_DrVnce 9;
BA_ "GenSigSendType" SG_ 420 RFC_Loc041_VrVnce 9;
BA_ "GenSigSendType" SG_ 420 RFC_Loc041_ThetaVnce 9;
BA_ "GenSigSendType" SG_ 420 RFC_Loc041_PhiVnce 9;
BA_ "GenSigSendType" SG_ 420 RFC_Loc041_RCS 9;
BA_ "GenSigStartValue" SG_ 420 RFC_Loc041_RCS 32768;
BA_ "GenSigSendType" SG_ 420 RFC_Loc041_RSSI 9;
BA_ "GenSigSendType" SG_ 421 RFC_Loc042_CRC 9;
BA_ "GenSigSendType" SG_ 421 RFC_Loc042_AliveCtr 9;
BA_ "GenSigSendType" SG_ 421 RFC_Loc042_ProtBlockCtr 9;
BA_ "GenSigSendType" SG_ 421 RFC_Loc042_Dr 9;
BA_ "GenSigSendType" SG_ 421 RFC_Loc042_Vr 9;
BA_ "GenSigStartValue" SG_ 421 RFC_Loc042_Vr 32768;
BA_ "GenSigSendType" SG_ 421 RFC_Loc042_Theta 9;
BA_ "GenSigStartValue" SG_ 421 RFC_Loc042_Theta 32768;
BA_ "GenSigSendType" SG_ 421 RFC_Loc042_Phi 9;
BA_ "GenSigStartValue" SG_ 421 RFC_Loc042_Phi 32768;
BA_ "GenSigSendType" SG_ 421 RFC_Loc042_DrVnce 9;
BA_ "GenSigSendType" SG_ 421 RFC_Loc042_VrVnce 9;
BA_ "GenSigSendType" SG_ 421 RFC_Loc042_ThetaVnce 9;
BA_ "GenSigSendType" SG_ 421 RFC_Loc042_PhiVnce 9;
BA_ "GenSigSendType" SG_ 421 RFC_Loc042_RCS 9;
BA_ "GenSigStartValue" SG_ 421 RFC_Loc042_RCS 32768;
BA_ "GenSigSendType" SG_ 421 RFC_Loc042_RSSI 9;
BA_ "GenSigSendType" SG_ 421 RFC_Loc043_Dr 9;
BA_ "GenSigSendType" SG_ 421 RFC_Loc043_Vr 9;
BA_ "GenSigStartValue" SG_ 421 RFC_Loc043_Vr 32768;
BA_ "GenSigSendType" SG_ 421 RFC_Loc043_Theta 9;
BA_ "GenSigStartValue" SG_ 421 RFC_Loc043_Theta 32768;
BA_ "GenSigSendType" SG_ 421 RFC_Loc043_Phi 9;
BA_ "GenSigStartValue" SG_ 421 RFC_Loc043_Phi 32768;
BA_ "GenSigSendType" SG_ 421 RFC_Loc043_DrVnce 9;
BA_ "GenSigSendType" SG_ 421 RFC_Loc043_VrVnce 9;
BA_ "GenSigSendType" SG_ 421 RFC_Loc043_ThetaVnce 9;
BA_ "GenSigSendType" SG_ 421 RFC_Loc043_PhiVnce 9;
BA_ "GenSigSendType" SG_ 421 RFC_Loc043_RCS 9;
BA_ "GenSigStartValue" SG_ 421 RFC_Loc043_RCS 32768;
BA_ "GenSigSendType" SG_ 421 RFC_Loc043_RSSI 9;
BA_ "GenSigSendType" SG_ 422 RFC_Loc044_CRC 9;
BA_ "GenSigSendType" SG_ 422 RFC_Loc044_AliveCtr 9;
BA_ "GenSigSendType" SG_ 422 RFC_Loc044_ProtBlockCtr 9;
BA_ "GenSigSendType" SG_ 422 RFC_Loc044_Dr 9;
BA_ "GenSigSendType" SG_ 422 RFC_Loc044_Vr 9;
BA_ "GenSigStartValue" SG_ 422 RFC_Loc044_Vr 32768;
BA_ "GenSigSendType" SG_ 422 RFC_Loc044_Theta 9;
BA_ "GenSigStartValue" SG_ 422 RFC_Loc044_Theta 32768;
BA_ "GenSigSendType" SG_ 422 RFC_Loc044_Phi 9;
BA_ "GenSigStartValue" SG_ 422 RFC_Loc044_Phi 32768;
BA_ "GenSigSendType" SG_ 422 RFC_Loc044_DrVnce 9;
BA_ "GenSigSendType" SG_ 422 RFC_Loc044_VrVnce 9;
BA_ "GenSigSendType" SG_ 422 RFC_Loc044_ThetaVnce 9;
BA_ "GenSigSendType" SG_ 422 RFC_Loc044_PhiVnce 9;
BA_ "GenSigSendType" SG_ 422 RFC_Loc044_RCS 9;
BA_ "GenSigStartValue" SG_ 422 RFC_Loc044_RCS 32768;
BA_ "GenSigSendType" SG_ 422 RFC_Loc044_RSSI 9;
BA_ "GenSigSendType" SG_ 422 RFC_Loc045_Dr 9;
BA_ "GenSigSendType" SG_ 422 RFC_Loc045_Vr 9;
BA_ "GenSigStartValue" SG_ 422 RFC_Loc045_Vr 32768;
BA_ "GenSigSendType" SG_ 422 RFC_Loc045_Theta 9;
BA_ "GenSigStartValue" SG_ 422 RFC_Loc045_Theta 32768;
BA_ "GenSigSendType" SG_ 422 RFC_Loc045_Phi 9;
BA_ "GenSigStartValue" SG_ 422 RFC_Loc045_Phi 32768;
BA_ "GenSigSendType" SG_ 422 RFC_Loc045_DrVnce 9;
BA_ "GenSigSendType" SG_ 422 RFC_Loc045_VrVnce 9;
BA_ "GenSigSendType" SG_ 422 RFC_Loc045_ThetaVnce 9;
BA_ "GenSigSendType" SG_ 422 RFC_Loc045_PhiVnce 9;
BA_ "GenSigSendType" SG_ 422 RFC_Loc045_RCS 9;
BA_ "GenSigStartValue" SG_ 422 RFC_Loc045_RCS 32768;
BA_ "GenSigSendType" SG_ 422 RFC_Loc045_RSSI 9;
BA_ "GenSigSendType" SG_ 423 RFC_Loc046_CRC 9;
BA_ "GenSigSendType" SG_ 423 RFC_Loc046_AliveCtr 9;
BA_ "GenSigSendType" SG_ 423 RFC_Loc046_ProtBlockCtr 9;
BA_ "GenSigSendType" SG_ 423 RFC_Loc046_Dr 9;
BA_ "GenSigSendType" SG_ 423 RFC_Loc046_Vr 9;
BA_ "GenSigStartValue" SG_ 423 RFC_Loc046_Vr 32768;
BA_ "GenSigSendType" SG_ 423 RFC_Loc046_Theta 9;
BA_ "GenSigStartValue" SG_ 423 RFC_Loc046_Theta 32768;
BA_ "GenSigSendType" SG_ 423 RFC_Loc046_Phi 9;
BA_ "GenSigStartValue" SG_ 423 RFC_Loc046_Phi 32768;
BA_ "GenSigSendType" SG_ 423 RFC_Loc046_DrVnce 9;
BA_ "GenSigSendType" SG_ 423 RFC_Loc046_VrVnce 9;
BA_ "GenSigSendType" SG_ 423 RFC_Loc046_ThetaVnce 9;
BA_ "GenSigSendType" SG_ 423 RFC_Loc046_PhiVnce 9;
BA_ "GenSigSendType" SG_ 423 RFC_Loc046_RCS 9;
BA_ "GenSigStartValue" SG_ 423 RFC_Loc046_RCS 32768;
BA_ "GenSigSendType" SG_ 423 RFC_Loc046_RSSI 9;
BA_ "GenSigSendType" SG_ 423 RFC_Loc047_Dr 9;
BA_ "GenSigSendType" SG_ 423 RFC_Loc047_Vr 9;
BA_ "GenSigStartValue" SG_ 423 RFC_Loc047_Vr 32768;
BA_ "GenSigSendType" SG_ 423 RFC_Loc047_Theta 9;
BA_ "GenSigStartValue" SG_ 423 RFC_Loc047_Theta 32768;
BA_ "GenSigSendType" SG_ 423 RFC_Loc047_Phi 9;
BA_ "GenSigStartValue" SG_ 423 RFC_Loc047_Phi 32768;
BA_ "GenSigSendType" SG_ 423 RFC_Loc047_DrVnce 9;
BA_ "GenSigSendType" SG_ 423 RFC_Loc047_VrVnce 9;
BA_ "GenSigSendType" SG_ 423 RFC_Loc047_ThetaVnce 9;
BA_ "GenSigSendType" SG_ 423 RFC_Loc047_PhiVnce 9;
BA_ "GenSigSendType" SG_ 423 RFC_Loc047_RCS 9;
BA_ "GenSigStartValue" SG_ 423 RFC_Loc047_RCS 32768;
BA_ "GenSigSendType" SG_ 423 RFC_Loc047_RSSI 9;
BA_ "GenSigSendType" SG_ 424 RFC_Loc048_CRC 9;
BA_ "GenSigSendType" SG_ 424 RFC_Loc048_AliveCtr 9;
BA_ "GenSigSendType" SG_ 424 RFC_Loc048_ProtBlockCtr 9;
BA_ "GenSigSendType" SG_ 424 RFC_Loc048_Dr 9;
BA_ "GenSigSendType" SG_ 424 RFC_Loc048_Vr 9;
BA_ "GenSigStartValue" SG_ 424 RFC_Loc048_Vr 32768;
BA_ "GenSigSendType" SG_ 424 RFC_Loc048_Theta 9;
BA_ "GenSigStartValue" SG_ 424 RFC_Loc048_Theta 32768;
BA_ "GenSigSendType" SG_ 424 RFC_Loc048_Phi 9;
BA_ "GenSigStartValue" SG_ 424 RFC_Loc048_Phi 32768;
BA_ "GenSigSendType" SG_ 424 RFC_Loc048_DrVnce 9;
BA_ "GenSigSendType" SG_ 424 RFC_Loc048_VrVnce 9;
BA_ "GenSigSendType" SG_ 424 RFC_Loc048_ThetaVnce 9;
BA_ "GenSigSendType" SG_ 424 RFC_Loc048_PhiVnce 9;
BA_ "GenSigSendType" SG_ 424 RFC_Loc048_RCS 9;
BA_ "GenSigStartValue" SG_ 424 RFC_Loc048_RCS 32768;
BA_ "GenSigSendType" SG_ 424 RFC_Loc048_RSSI 9;
BA_ "GenSigSendType" SG_ 424 RFC_Loc049_Dr 9;
BA_ "GenSigSendType" SG_ 424 RFC_Loc049_Vr 9;
BA_ "GenSigStartValue" SG_ 424 RFC_Loc049_Vr 32768;
BA_ "GenSigSendType" SG_ 424 RFC_Loc049_Theta 9;
BA_ "GenSigStartValue" SG_ 424 RFC_Loc049_Theta 32768;
BA_ "GenSigSendType" SG_ 424 RFC_Loc049_Phi 9;
BA_ "GenSigStartValue" SG_ 424 RFC_Loc049_Phi 32768;
BA_ "GenSigSendType" SG_ 424 RFC_Loc049_DrVnce 9;
BA_ "GenSigSendType" SG_ 424 RFC_Loc049_VrVnce 9;
BA_ "GenSigSendType" SG_ 424 RFC_Loc049_ThetaVnce 9;
BA_ "GenSigSendType" SG_ 424 RFC_Loc049_PhiVnce 9;
BA_ "GenSigSendType" SG_ 424 RFC_Loc049_RCS 9;
BA_ "GenSigStartValue" SG_ 424 RFC_Loc049_RCS 32768;
BA_ "GenSigSendType" SG_ 424 RFC_Loc049_RSSI 9;
BA_ "GenSigSendType" SG_ 425 RFC_Loc050_CRC 9;
BA_ "GenSigSendType" SG_ 425 RFC_Loc050_AliveCtr 9;
BA_ "GenSigSendType" SG_ 425 RFC_Loc050_ProtBlockCtr 9;
BA_ "GenSigSendType" SG_ 425 RFC_Loc050_Dr 9;
BA_ "GenSigSendType" SG_ 425 RFC_Loc050_Vr 9;
BA_ "GenSigStartValue" SG_ 425 RFC_Loc050_Vr 32768;
BA_ "GenSigSendType" SG_ 425 RFC_Loc050_Theta 9;
BA_ "GenSigStartValue" SG_ 425 RFC_Loc050_Theta 32768;
BA_ "GenSigSendType" SG_ 425 RFC_Loc050_Phi 9;
BA_ "GenSigStartValue" SG_ 425 RFC_Loc050_Phi 32768;
BA_ "GenSigSendType" SG_ 425 RFC_Loc050_DrVnce 9;
BA_ "GenSigSendType" SG_ 425 RFC_Loc050_VrVnce 9;
BA_ "GenSigSendType" SG_ 425 RFC_Loc050_ThetaVnce 9;
BA_ "GenSigSendType" SG_ 425 RFC_Loc050_PhiVnce 9;
BA_ "GenSigSendType" SG_ 425 RFC_Loc050_RCS 9;
BA_ "GenSigStartValue" SG_ 425 RFC_Loc050_RCS 32768;
BA_ "GenSigSendType" SG_ 425 RFC_Loc050_RSSI 9;
BA_ "GenSigSendType" SG_ 425 RFC_Loc051_Dr 9;
BA_ "GenSigSendType" SG_ 425 RFC_Loc051_Vr 9;
BA_ "GenSigStartValue" SG_ 425 RFC_Loc051_Vr 32768;
BA_ "GenSigSendType" SG_ 425 RFC_Loc051_Theta 9;
BA_ "GenSigStartValue" SG_ 425 RFC_Loc051_Theta 32768;
BA_ "GenSigSendType" SG_ 425 RFC_Loc051_Phi 9;
BA_ "GenSigStartValue" SG_ 425 RFC_Loc051_Phi 32768;
BA_ "GenSigSendType" SG_ 425 RFC_Loc051_DrVnce 9;
BA_ "GenSigSendType" SG_ 425 RFC_Loc051_VrVnce 9;
BA_ "GenSigSendType" SG_ 425 RFC_Loc051_ThetaVnce 9;
BA_ "GenSigSendType" SG_ 425 RFC_Loc051_PhiVnce 9;
BA_ "GenSigSendType" SG_ 425 RFC_Loc051_RCS 9;
BA_ "GenSigStartValue" SG_ 425 RFC_Loc051_RCS 32768;
BA_ "GenSigSendType" SG_ 425 RFC_Loc051_RSSI 9;
BA_ "GenSigSendType" SG_ 426 RFC_Loc052_CRC 9;
BA_ "GenSigSendType" SG_ 426 RFC_Loc052_AliveCtr 9;
BA_ "GenSigSendType" SG_ 426 RFC_Loc052_ProtBlockCtr 9;
BA_ "GenSigSendType" SG_ 426 RFC_Loc052_Dr 9;
BA_ "GenSigSendType" SG_ 426 RFC_Loc052_Vr 9;
BA_ "GenSigStartValue" SG_ 426 RFC_Loc052_Vr 32768;
BA_ "GenSigSendType" SG_ 426 RFC_Loc052_Theta 9;
BA_ "GenSigStartValue" SG_ 426 RFC_Loc052_Theta 32768;
BA_ "GenSigSendType" SG_ 426 RFC_Loc052_Phi 9;
BA_ "GenSigStartValue" SG_ 426 RFC_Loc052_Phi 32768;
BA_ "GenSigSendType" SG_ 426 RFC_Loc052_DrVnce 9;
BA_ "GenSigSendType" SG_ 426 RFC_Loc052_VrVnce 9;
BA_ "GenSigSendType" SG_ 426 RFC_Loc052_ThetaVnce 9;
BA_ "GenSigSendType" SG_ 426 RFC_Loc052_PhiVnce 9;
BA_ "GenSigSendType" SG_ 426 RFC_Loc052_RCS 9;
BA_ "GenSigStartValue" SG_ 426 RFC_Loc052_RCS 32768;
BA_ "GenSigSendType" SG_ 426 RFC_Loc052_RSSI 9;
BA_ "GenSigSendType" SG_ 426 RFC_Loc053_Dr 9;
BA_ "GenSigSendType" SG_ 426 RFC_Loc053_Vr 9;
BA_ "GenSigStartValue" SG_ 426 RFC_Loc053_Vr 32768;
BA_ "GenSigSendType" SG_ 426 RFC_Loc053_Theta 9;
BA_ "GenSigStartValue" SG_ 426 RFC_Loc053_Theta 32768;
BA_ "GenSigSendType" SG_ 426 RFC_Loc053_Phi 9;
BA_ "GenSigStartValue" SG_ 426 RFC_Loc053_Phi 32768;
BA_ "GenSigSendType" SG_ 426 RFC_Loc053_DrVnce 9;
BA_ "GenSigSendType" SG_ 426 RFC_Loc053_VrVnce 9;
BA_ "GenSigSendType" SG_ 426 RFC_Loc053_ThetaVnce 9;
BA_ "GenSigSendType" SG_ 426 RFC_Loc053_PhiVnce 9;
BA_ "GenSigSendType" SG_ 426 RFC_Loc053_RCS 9;
BA_ "GenSigStartValue" SG_ 426 RFC_Loc053_RCS 32768;
BA_ "GenSigSendType" SG_ 426 RFC_Loc053_RSSI 9;
BA_ "GenSigSendType" SG_ 427 RFC_Loc054_CRC 9;
BA_ "GenSigSendType" SG_ 427 RFC_Loc054_AliveCtr 9;
BA_ "GenSigSendType" SG_ 427 RFC_Loc054_ProtBlockCtr 9;
BA_ "GenSigSendType" SG_ 427 RFC_Loc054_Dr 9;
BA_ "GenSigSendType" SG_ 427 RFC_Loc054_Vr 9;
BA_ "GenSigStartValue" SG_ 427 RFC_Loc054_Vr 32768;
BA_ "GenSigSendType" SG_ 427 RFC_Loc054_Theta 9;
BA_ "GenSigStartValue" SG_ 427 RFC_Loc054_Theta 32768;
BA_ "GenSigSendType" SG_ 427 RFC_Loc054_Phi 9;
BA_ "GenSigStartValue" SG_ 427 RFC_Loc054_Phi 32768;
BA_ "GenSigSendType" SG_ 427 RFC_Loc054_DrVnce 9;
BA_ "GenSigSendType" SG_ 427 RFC_Loc054_VrVnce 9;
BA_ "GenSigSendType" SG_ 427 RFC_Loc054_ThetaVnce 9;
BA_ "GenSigSendType" SG_ 427 RFC_Loc054_PhiVnce 9;
BA_ "GenSigSendType" SG_ 427 RFC_Loc054_RCS 9;
BA_ "GenSigStartValue" SG_ 427 RFC_Loc054_RCS 32768;
BA_ "GenSigSendType" SG_ 427 RFC_Loc054_RSSI 9;
BA_ "GenSigSendType" SG_ 427 RFC_Loc055_Dr 9;
BA_ "GenSigSendType" SG_ 427 RFC_Loc055_Vr 9;
BA_ "GenSigStartValue" SG_ 427 RFC_Loc055_Vr 32768;
BA_ "GenSigSendType" SG_ 427 RFC_Loc055_Theta 9;
BA_ "GenSigStartValue" SG_ 427 RFC_Loc055_Theta 32768;
BA_ "GenSigSendType" SG_ 427 RFC_Loc055_Phi 9;
BA_ "GenSigStartValue" SG_ 427 RFC_Loc055_Phi 32768;
BA_ "GenSigSendType" SG_ 427 RFC_Loc055_DrVnce 9;
BA_ "GenSigSendType" SG_ 427 RFC_Loc055_VrVnce 9;
BA_ "GenSigSendType" SG_ 427 RFC_Loc055_ThetaVnce 9;
BA_ "GenSigSendType" SG_ 427 RFC_Loc055_PhiVnce 9;
BA_ "GenSigSendType" SG_ 427 RFC_Loc055_RCS 9;
BA_ "GenSigStartValue" SG_ 427 RFC_Loc055_RCS 32768;
BA_ "GenSigSendType" SG_ 427 RFC_Loc055_RSSI 9;
VAL_ 384 RFC_Hdr00_SensorState 0 "SENSOR FULLY OPERATIONAL" 1 "HW MALFUNCTION" 2 "DSP ISSUES" 3 "COMMUNICATION ERRORS" 4 "MISALIGNMENT (OUT OF SPEC)" 5 "SENSOR BLIDNESS DETECTED" 6 "SENSOR DISTUBED" 7 "OTHER ISSUES" 8 "RESERVED1" 9 "RESERVED2" 10 "RESERVED3" 11 "RESERVED4" 12 "RESERVED5" 13 "RESERVED6" 14 "RESERVED7" 15 "INVALID" ;
